AUTOSAR XML (schema 00046)
package /VehicleProject
  system System
package /Diagnostics
  diagnostic service table DS_HUT: diagnostic-connections=DC_0xE001_oHUT_oCAN, ecu-instance=HUT
  diagnostic connection DC_0xE001_oHUT_oCAN: functional-request=msg_diag_RequestGlobal_oTN_0x00E0_Tester, physical-request=msg_diag_Request_MyECU_oTN_0x0001_HUT, response=msg_diag_Response_MyECU_oTN_0x0001_HUT
package /NM
  nm config NmConfig: can-nm-cluster-coupling=coupled-cluster=[B30_for_SC_CAN_V3_2_CAN, CAN]
    can nm cluster B30_for_SC_CAN_V3_2_CAN: communication-cluster=B30_for_SC_CAN_V3_2, nm-channel-id=1, nm-msg-cycle-time=0.5, nm-network-timeout=2, nm-repeat-message-time=1.5, nm-user-data-length=6, nm-wait-bus-sleep-time=5
      7 x can nm node, all with nm-node-id=0, nm-range-config={lower-can-id=1280, upper-can-id=1379}:
        CEM: nm-if-ecu=CEM_CAN, rx-nm-pdu=[DVR_NM_oB30_for_SC_CAN_V3_2, HUT_NM_oB30_for_SC_CAN_V3_2, T_Box_NM_oB30_for_SC_CAN_V3_2, XBOX_D_NM_oB30_for_SC_CAN_V3_2], tx-nm-pdu=CEM_NM_oB30_for_SC_CAN_V3_2
        DVR: nm-if-ecu=DVR_CAN, rx-nm-pdu=[CEM_NM_oB30_for_SC_CAN_V3_2, HUT_NM_oB30_for_SC_CAN_V3_2, T_Box_NM_oB30_for_SC_CAN_V3_2, XBOX_D_NM_oB30_for_SC_CAN_V3_2], tx-nm-pdu=DVR_NM_oB30_for_SC_CAN_V3_2
        GW: nm-if-ecu=GW_CAN, nm-passive-mode-enabled=true
        HUT: controller=CT_B30_for_SC_CAN_V3_2, nm-if-ecu=HUT_CAN, rx-nm-pdu=[CEM_NM_oB30_for_SC_CAN_V3_2, DVR_NM_oB30_for_SC_CAN_V3_2, T_Box_NM_oB30_for_SC_CAN_V3_2, XBOX_D_NM_oB30_for_SC_CAN_V3_2], tx-nm-pdu=HUT_NM_oB30_for_SC_CAN_V3_2
        T_BOX: nm-if-ecu=T_BOX_CAN, rx-nm-pdu=[CEM_NM_oB30_for_SC_CAN_V3_2, DVR_NM_oB30_for_SC_CAN_V3_2, HUT_NM_oB30_for_SC_CAN_V3_2, XBOX_D_NM_oB30_for_SC_CAN_V3_2], tx-nm-pdu=T_Box_NM_oB30_for_SC_CAN_V3_2
        Tester: nm-if-ecu=Tester_CAN, nm-passive-mode-enabled=true
        XBOX_D: nm-if-ecu=XBOX_D_CAN, rx-nm-pdu=[CEM_NM_oB30_for_SC_CAN_V3_2, DVR_NM_oB30_for_SC_CAN_V3_2, HUT_NM_oB30_for_SC_CAN_V3_2, T_Box_NM_oB30_for_SC_CAN_V3_2], tx-nm-pdu=XBOX_D_NM_oB30_for_SC_CAN_V3_2
    can nm cluster CAN: communication-cluster=CAN, nm-channel-id=0, nm-cbv-position=0, nm-msg-cycle-time=0.1, nm-network-timeout=1, nm-nid-position=1, nm-repeat-message-time=0.4, nm-user-data-length=6, nm-wait-bus-sleep-time=0.75
      can nm node HUT: controller=CT_CAN, nm-if-ecu=HUT_CAN, nm-node-id=0, rx-nm-pdu=[msg_nm_OtherECU_oCAN, msg_nm_RearECU_oCAN], tx-nm-pdu=msg_nm_MyECU_oCAN, nm-msg-cycle-offset=0, nm-msg-reduced-time=0.05, nm-range-config={lower-can-id=1024, upper-can-id=1087}
      can nm node OtherECU: nm-if-ecu=OtherECU_CAN, nm-node-id=0, rx-nm-pdu=[msg_nm_MyECU_oCAN, msg_nm_RearECU_oCAN], tx-nm-pdu=msg_nm_OtherECU_oCAN, nm-msg-cycle-offset=0, nm-msg-reduced-time=0.05, nm-range-config={lower-can-id=1024, upper-can-id=1087}
      can nm node RearECU: nm-if-ecu=RearECU_CAN, nm-node-id=1, rx-nm-pdu=[msg_nm_MyECU_oCAN, msg_nm_OtherECU_oCAN], tx-nm-pdu=msg_nm_RearECU_oCAN, nm-msg-cycle-offset=0, nm-msg-reduced-time=0.05, nm-range-config={lower-can-id=1024, upper-can-id=1087}
    nm-if-ecus:
      9 x nm ecu, all with nm-node-id-enabled=true, nm-user-data-enabled=true:
        CEM_CAN
        DVR_CAN
        GW_CAN: nm-passive-mode-enabled=true
        HUT_CAN: ecu-instance=HUT
        OtherECU_CAN
        RearECU_CAN
        T_BOX_CAN
        Tester_CAN: nm-passive-mode-enabled=true
        XBOX_D_CAN
package /TP
  can tp config B30_for_SC_CAN_V3_2_CAN: communication-cluster=B30_for_SC_CAN_V3_2, can-tp-ecu{cycle-time-main-function=0.005, ecu-instance=HUT}
    can tp channel TPCH: channel-id=1, channel-mode=FULL-DUPLEX-MODE
    can-tp-connection addressing-format=STANDARD, can-tp-channel=B30_for_SC_CAN_V3_2_CAN/TPCH, data-pdu=DiagFuncReq_Tp_oB30_for_SC_CAN_V3_2, receiver=TN_HUT_FD, ta-type=FUNCTIONAL-CAN-FD, tp-sdu=DiagFuncReq_oB30_for_SC_CAN_V3_2, transmitter=TN_Tester_FD:
      ident DiagFuncReq_FD_oTN_Tester_FD
    can-tp-connection addressing-format=STANDARD, can-tp-channel=B30_for_SC_CAN_V3_2_CAN/TPCH, data-pdu=DiagFuncReq_Tp_oB30_for_SC_CAN_V3_2_20, receiver=B30_for_SC_CAN_V3_2_CAN/TN_HUT, ta-type=FUNCTIONAL, tp-sdu=DiagFuncReq_oB30_for_SC_CAN_V3_2_20, transmitter=TN_Tester:
      ident DiagFuncReq_oTN_Tester
    can-tp-connection addressing-format=STANDARD, can-tp-channel=B30_for_SC_CAN_V3_2_CAN/TPCH, data-pdu=HUT_Phy_Req_Tp_oB30_for_SC_CAN_V3_2_20, flow-control-pdu=HUT_Phy_Resp_Tp_oB30_for_SC_CAN_V3_2_20, receiver=B30_for_SC_CAN_V3_2_CAN/TN_HUT, ta-type=PHYSICAL, tp-sdu=HUT_Phy_Req_oB30_for_SC_CAN_V3_2_20, transmitter=TN_Tester:
      ident HUT_Phy_Req_oTN_HUT
    can-tp-connection addressing-format=STANDARD, can-tp-channel=B30_for_SC_CAN_V3_2_CAN/TPCH, data-pdu=HUT_Phy_Req_Tp_oB30_for_SC_CAN_V3_2, flow-control-pdu=HUT_Phy_Resp_Tp_oB30_for_SC_CAN_V3_2, receiver=TN_HUT_FD, ta-type=PHYSICAL-CAN-FD, tp-sdu=HUT_Phy_Req_oB30_for_SC_CAN_V3_2, transmitter=TN_Tester_FD:
      ident HUT_Phy_Req_oTN_HUT_FD
    can-tp-connection addressing-format=STANDARD, can-tp-channel=B30_for_SC_CAN_V3_2_CAN/TPCH, data-pdu=HUT_Phy_Resp_Tp_oB30_for_SC_CAN_V3_2_20, flow-control-pdu=HUT_Phy_Req_Tp_oB30_for_SC_CAN_V3_2_20, receiver=TN_Tester, ta-type=PHYSICAL, tp-sdu=HUT_Phy_Resp_oB30_for_SC_CAN_V3_2_20, transmitter=B30_for_SC_CAN_V3_2_CAN/TN_HUT:
      ident HUT_Phy_Resp_oTN_HUT
    can-tp-connection addressing-format=STANDARD, can-tp-channel=B30_for_SC_CAN_V3_2_CAN/TPCH, data-pdu=HUT_Phy_Resp_Tp_oB30_for_SC_CAN_V3_2, flow-control-pdu=HUT_Phy_Req_Tp_oB30_for_SC_CAN_V3_2, receiver=TN_Tester_FD, ta-type=PHYSICAL-CAN-FD, tp-sdu=HUT_Phy_Resp_oB30_for_SC_CAN_V3_2, transmitter=TN_HUT_FD:
      ident HUT_Phy_Resp_oTN_HUT_FD
    4 x can tp node:
      TN_HUT: connector=CN_B30_for_SC_CAN_V3_2
      TN_HUT_FD: connector=CN_B30_for_SC_CAN_V3_2
      TN_Tester
      TN_Tester_FD
  can tp config CAN: communication-cluster=CAN, can-tp-ecu{cycle-time-main-function=0.005, ecu-instance=HUT}
    can tp address TA_0x0000: tp-address=0
    can tp address TA_0x0001: tp-address=1
    can tp address TA_0x00E0: tp-address=224
    can tp channel TPCH: channel-id=0, channel-mode=FULL-DUPLEX-MODE
    can-tp-connection addressing-format=STANDARD, can-tp-channel=CAN/TPCH, data-pdu=msg_diag_RequestGlobal_Tp_oCAN, multicast=TA_0x0000, receiver=CAN/TN_HUT, ta-type=FUNCTIONAL, tp-sdu=msg_diag_RequestGlobal_oCAN, transmitter=TN_0x00E0_Tester:
      ident msg_diag_RequestGlobal_oTN_0x00E0_Tester
    can-tp-connection addressing-format=STANDARD, can-tp-channel=CAN/TPCH, data-pdu=msg_diag_Request_MyECU_Tp_oCAN, flow-control-pdu=msg_diag_Response_MyECU_Tp_oCAN, receiver=TN_0x0001_HUT, ta-type=PHYSICAL, tp-sdu=msg_diag_Request_MyECU_oCAN, transmitter=TN_0x00E0_Tester:
      ident msg_diag_Request_MyECU_oTN_0x0001_HUT
    can-tp-connection addressing-format=STANDARD, can-tp-channel=CAN/TPCH, data-pdu=msg_diag_Response_MyECU_Tp_oCAN, flow-control-pdu=msg_diag_Request_MyECU_Tp_oCAN, receiver=TN_0x00E0_Tester, ta-type=PHYSICAL, tp-sdu=msg_diag_Response_MyECU_oCAN, transmitter=TN_0x0001_HUT:
      ident msg_diag_Response_MyECU_oTN_0x0001_HUT
    can tp node TN_0x0001_HUT: connector=CN_CAN, tp-address=TA_0x0001
    can tp node TN_0x00E0_Tester: tp-address=TA_0x00E0
    can tp node TN_HUT: connector=CN_CAN
  lin tp config LIN00: communication-cluster=LIN00
    tp address TA_0x0001: tp-address=1
    tp address TA_0x0003: tp-address=3
    tp address TA_0x007E: tp-address=126
    tp-connections:
      data-pdu=MasterReq_Tp_oLIN00, lin-tp-n-sdu=MasterReq_oLIN00, multicast=TA_0x007E, receiver=[TN_0x0001_RearECU, TN_0x0003_Slave3], transmitter=TN_Master
      data-pdu=SlaveResp_Tp_oLIN00, flow-control=MasterReq_Tp_oLIN00, lin-tp-n-sdu=SlaveResp_RearECU_oLIN00, receiver=TN_Master, transmitter=TN_0x0001_RearECU
      data-pdu=SlaveResp_Tp_oLIN00, flow-control=MasterReq_Tp_oLIN00, lin-tp-n-sdu=SlaveResp_Slave3_oLIN00, receiver=TN_Master, transmitter=TN_0x0003_Slave3
      data-pdu=MasterReq_Tp_oLIN00, flow-control=SlaveResp_Tp_oLIN00, lin-tp-n-sdu=MasterReq_RearECU_oLIN00, receiver=TN_0x0001_RearECU, transmitter=TN_Master
      data-pdu=MasterReq_Tp_oLIN00, flow-control=SlaveResp_Tp_oLIN00, lin-tp-n-sdu=MasterReq_Slave3_oLIN00, receiver=TN_0x0003_Slave3, transmitter=TN_Master
    lin tp node TN_0x0001_RearECU: tp-address=TA_0x0001
    lin tp node TN_0x0003_Slave3: tp-address=TA_0x0003
    lin tp node TN_Master: connector=CN_LIN00
package /Cluster
  can cluster B30_for_SC_CAN_V3_2: protocol-name=CAN  # P02-001-020MM01 C_Matrix for SC_CANFD_V3.0_Merge_OnlyBigSignal_20220329
    can physical channel CHNL: comm-connectors=CN_B30_for_SC_CAN_V3_2
      frame ABM1_oB30_for_SC_CAN_V3_2: id 0x351, to HUT, frame-length=16, can-addressing-mode=STANDARD, can-frame-rx-behavior=ANY, can-frame-tx-behavior=CAN-FD
        secured i pdu ABM1_Sc_oB30_for_SC_CAN_V3_2: length=16, authentication-props=AuthABM1_Sc_oB30_for_SC_CAN_V3_2, freshness-props=FreshnessABM1_Sc_oB30_for_SC_CAN_V3_2, payload=PT_ABM1, secure-communication-props={auth-info-tx-length=48, data-id=849, freshness-value-length=64, freshness-value-tx-length=16}
      frame ABM2_oB30_for_SC_CAN_V3_2: id 0x245, to HUT, frame-length=8, can-addressing-mode=STANDARD, can-frame-rx-behavior=ANY, can-frame-tx-behavior=CAN-FD
        pdu ABM2_oB30_for_SC_CAN_V3_2: length=8, minimum-delay=0, transmission-mode-false-timing=cyclic-timing=time-period=0.02, transmission-mode-true-timing=cyclic-timing=time-period=0.02, unused-bit-pattern=0
          signal ABM2_0x245_oABM2_oB30_for_SC_CAN_V3_2: start 0, 64 bit, opaque, i-signal-type=ARRAY, init-value=8 x 0, base-type=uint8_8_none, compu-method=CM_ABM2_0x245, data-constr=DC_ABM2_0x245, transfer-property=PENDING, to HUT
      frame ABS1_oB30_for_SC_CAN_V3_2: id 0x231, to HUT, frame-length=8, can-addressing-mode=STANDARD, can-frame-rx-behavior=ANY, can-frame-tx-behavior=CAN-FD
        pdu ABS1_oB30_for_SC_CAN_V3_2: length=8, minimum-delay=0, transmission-mode-false-timing=cyclic-timing=time-period=0.02, transmission-mode-true-timing=cyclic-timing=time-period=0.02, unused-bit-pattern=0
          signal ABS1_0x231_oABS1_oB30_for_SC_CAN_V3_2: start 0, 64 bit, opaque, i-signal-type=ARRAY, init-value=8 x 0, base-type=uint8_8_none, compu-method=CM_ABS1_0x231, data-constr=DC_ABS1_0x231, transfer-property=PENDING, to HUT
      frame ABS2_oB30_for_SC_CAN_V3_2: id 0x246, to HUT, frame-length=8, can-addressing-mode=STANDARD, can-frame-rx-behavior=ANY, can-frame-tx-behavior=CAN-FD
        pdu ABS2_oB30_for_SC_CAN_V3_2: length=8, minimum-delay=0, transmission-mode-false-timing=cyclic-timing=time-period=0.02, transmission-mode-true-timing=cyclic-timing=time-period=0.02, unused-bit-pattern=0
          signal ABS2_0x246_oABS2_oB30_for_SC_CAN_V3_2: start 0, 64 bit, opaque, i-signal-type=ARRAY, init-value=8 x 0, base-type=uint8_8_none, compu-method=CM_ABS2_0x246, data-constr=DC_ABS2_0x246, transfer-property=PENDING, to HUT
      frame AC1_oB30_for_SC_CAN_V3_2: id 0x29D, to HUT, frame-length=8, can-addressing-mode=STANDARD, can-frame-rx-behavior=ANY, can-frame-tx-behavior=CAN-FD
        pdu AC1_oB30_for_SC_CAN_V3_2: length=8, minimum-delay=0, transmission-mode-false-timing=cyclic-timing=time-period=0.1, transmission-mode-true-timing=cyclic-timing=time-period=0.1, unused-bit-pattern=0
          signal AC1_0x29D_oAC1_oB30_for_SC_CAN_V3_2: start 0, 64 bit, opaque, i-signal-type=ARRAY, init-value=8 x 0, base-type=uint8_8_none, compu-method=CM_AC1_0x29D, data-constr=DC_AC1_0x29D, transfer-property=PENDING, to HUT
      frame AC14_oB30_for_SC_CAN_V3_2: id 0x299, to HUT, frame-length=8, can-addressing-mode=STANDARD, can-frame-rx-behavior=ANY, can-frame-tx-behavior=CAN-FD
        pdu AC14_oB30_for_SC_CAN_V3_2: length=8, minimum-delay=0, transmission-mode-false-timing=cyclic-timing=time-period=0.1, transmission-mode-true-timing=cyclic-timing=time-period=0.1, unused-bit-pattern=0
          signal AC14_0x299_oAC14_oB30_for_SC_CAN_V3_2: start 0, 64 bit, opaque, i-signal-type=ARRAY, init-value=8 x 0, base-type=uint8_8_none, compu-method=CM_AC14_0x299, data-constr=DC_AC14_0x299, transfer-property=PENDING, to HUT
      frame AC2_oB30_for_SC_CAN_V3_2: id 0x385, to HUT, frame-length=8, can-addressing-mode=STANDARD, can-frame-rx-behavior=ANY, can-frame-tx-behavior=CAN-FD
        pdu AC2_oB30_for_SC_CAN_V3_2: length=8, minimum-delay=0, transmission-mode-false-timing=cyclic-timing=time-period=0.1, transmission-mode-true-timing=cyclic-timing=time-period=0.1, unused-bit-pattern=0
          signal AC2_0x385_oAC2_oB30_for_SC_CAN_V3_2: start 0, 64 bit, opaque, i-signal-type=ARRAY, init-value=8 x 0, base-type=uint8_8_none, compu-method=CM_AC2_0x385, data-constr=DC_AC2_0x385, transfer-property=PENDING, to HUT
      frame AC3_oB30_for_SC_CAN_V3_2: id 0x2FD, to HUT, frame-length=8, can-addressing-mode=STANDARD, can-frame-rx-behavior=ANY, can-frame-tx-behavior=CAN-FD
        pdu AC3_oB30_for_SC_CAN_V3_2: length=8, minimum-delay=0, transmission-mode-false-timing=cyclic-timing=time-period=0.1, transmission-mode-true-timing=cyclic-timing=time-period=0.1, unused-bit-pattern=0
          signal AC3_0x2FD_oAC3_oB30_for_SC_CAN_V3_2: start 0, 64 bit, opaque, i-signal-type=ARRAY, init-value=8 x 0, base-type=uint8_8_none, compu-method=CM_AC3_0x2FD, data-constr=DC_AC3_0x2FD, transfer-property=PENDING, to HUT
      frame AC4_oB30_for_SC_CAN_V3_2: id 0x2CC, to HUT, frame-length=8, can-addressing-mode=STANDARD, can-frame-rx-behavior=ANY, can-frame-tx-behavior=CAN-FD
        pdu AC4_oB30_for_SC_CAN_V3_2: length=8, minimum-delay=0, transmission-mode-false-timing=cyclic-timing=time-period=0.1, transmission-mode-true-timing=cyclic-timing=time-period=0.1, unused-bit-pattern=0
          signal AC4_0x2CC_oAC4_oB30_for_SC_CAN_V3_2: start 0, 64 bit, opaque, i-signal-type=ARRAY, init-value=8 x 0, base-type=uint8_8_none, compu-method=CM_AC4_0x2CC, data-constr=DC_AC4_0x2CC, transfer-property=PENDING, to HUT
      frame AC6_oB30_for_SC_CAN_V3_2: id 0x2F8, to HUT, frame-length=8, can-addressing-mode=STANDARD, can-frame-rx-behavior=ANY, can-frame-tx-behavior=CAN-FD
        pdu AC6_oB30_for_SC_CAN_V3_2: length=8, minimum-delay=0, transmission-mode-false-timing=cyclic-timing=time-period=0.1, transmission-mode-true-timing=cyclic-timing=time-period=0.1, unused-bit-pattern=0
          signal AC6_0x2F8_oAC6_oB30_for_SC_CAN_V3_2: start 0, 64 bit, opaque, i-signal-type=ARRAY, init-value=8 x 0, base-type=uint8_8_none, compu-method=CM_AC6_0x2F8, data-constr=DC_AC6_0x2F8, transfer-property=PENDING, to HUT
      frame AC7_oB30_for_SC_CAN_V3_2: id 0x2D0, to HUT, frame-length=8, can-addressing-mode=STANDARD, can-frame-rx-behavior=ANY, can-frame-tx-behavior=CAN-FD
        pdu AC7_oB30_for_SC_CAN_V3_2: length=8, minimum-delay=0, transmission-mode-false-timing=cyclic-timing=time-period=0.1, transmission-mode-true-timing=cyclic-timing=time-period=0.1, unused-bit-pattern=0
          signal AC7_0x2D0_oAC7_oB30_for_SC_CAN_V3_2: start 0, 64 bit, opaque, i-signal-type=ARRAY, init-value=8 x 0, base-type=uint8_8_none, compu-method=CM_AC7_0x2D0, data-constr=DC_AC7_0x2D0, transfer-property=PENDING, to HUT
      frame AC8_oB30_for_SC_CAN_V3_2: id 0x27C, to HUT, frame-length=8, can-addressing-mode=STANDARD, can-frame-rx-behavior=ANY, can-frame-tx-behavior=CAN-FD
        pdu AC8_oB30_for_SC_CAN_V3_2: length=8, minimum-delay=0, transmission-mode-false-timing=cyclic-timing=time-period=0.05, transmission-mode-true-timing=cyclic-timing=time-period=0.05, unused-bit-pattern=0
          signal AC8_0x27C_oAC8_oB30_for_SC_CAN_V3_2: start 0, 64 bit, opaque, i-signal-type=ARRAY, init-value=8 x 0, base-type=uint8_8_none, compu-method=CM_AC8_0x27C, data-constr=DC_AC8_0x27C, transfer-property=PENDING, to HUT
      frame ACC_FD2_oB30_for_SC_CAN_V3_2: id 0x2AB, to HUT, frame-length=64, can-addressing-mode=STANDARD, can-frame-rx-behavior=ANY, can-frame-tx-behavior=CAN-FD
        secured i pdu ACC_FD2_Sc_oB30_for_SC_CAN_V3_2: length=64, authentication-props=AuthACC_FD2_Sc_oB30_for_SC_CAN_V3_2, freshness-props=FreshnessACC_FD2_Sc_oB30_for_SC_CAN_V3_2, payload=PT_ACC_FD2, secure-communication-props={auth-info-tx-length=48, data-id=683, freshness-value-length=64, freshness-value-tx-length=16}
      frame ACC_FD3_oB30_for_SC_CAN_V3_2: id 0x2B4, to HUT, frame-length=64, can-addressing-mode=STANDARD, can-frame-rx-behavior=ANY, can-frame-tx-behavior=CAN-FD
        pdu ACC_FD3_oB30_for_SC_CAN_V3_2: length=64, minimum-delay=0, transmission-mode-false-timing=cyclic-timing=time-period=0.1, transmission-mode-true-timing=cyclic-timing=time-period=0.1, unused-bit-pattern=0
          signal ACC_FD3_0x2B4_oACC_FD3_oB30_for_SC_CAN_V3_2: start 0, 512 bit, opaque, i-signal-type=ARRAY, init-value=64 x 0, base-type=uint8_64_none, compu-method=CM_ACC_FD3_0x2B4, data-constr=DC_ACC_FD3_0x2B4, transfer-property=PENDING, to HUT
      frame ACC_FD4_oB30_for_SC_CAN_V3_2: id 0x2B8, to HUT, frame-length=64, can-addressing-mode=STANDARD, can-frame-rx-behavior=ANY, can-frame-tx-behavior=CAN-FD
        pdu ACC_FD4_oB30_for_SC_CAN_V3_2: length=64, minimum-delay=0, transmission-mode-false-timing=cyclic-timing=time-period=0.1, transmission-mode-true-timing=cyclic-timing=time-period=0.1, unused-bit-pattern=0
          signal ACC_FD4_0x2B8_oACC_FD4_oB30_for_SC_CAN_V3_2: start 0, 512 bit, opaque, i-signal-type=ARRAY, init-value=64 x 0, base-type=uint8_64_none, compu-method=CM_ACC_FD4_0x2B8, data-constr=DC_ACC_FD4_0x2B8, transfer-property=PENDING, to HUT
      frame AEB_FD1_oB30_for_SC_CAN_V3_2: id 0x18B, to HUT, frame-length=64, can-addressing-mode=STANDARD, can-frame-rx-behavior=ANY, can-frame-tx-behavior=CAN-FD
        pdu AEB_FD1_oB30_for_SC_CAN_V3_2: length=64, minimum-delay=0, transmission-mode-false-timing=cyclic-timing=time-period=0.02, transmission-mode-true-timing=cyclic-timing=time-period=0.02, unused-bit-pattern=0
          signal AEB_FD1_0x18B_oAEB_FD1_oB30_for_SC_CAN_V3_2: start 0, 512 bit, opaque, i-signal-type=ARRAY, init-value=64 x 0, base-type=uint8_64_none, compu-method=CM_AEB_FD1_0x18B, data-constr=DC_AEB_FD1_0x18B, transfer-property=PENDING, to HUT
      frame AEB_FD2_oB30_for_SC_CAN_V3_2: id 0x227, to HUT, frame-length=64, can-addressing-mode=STANDARD, can-frame-rx-behavior=ANY, can-frame-tx-behavior=CAN-FD
        secured i pdu AEB_FD2_Sc_oB30_for_SC_CAN_V3_2: length=64, authentication-props=AuthAEB_FD2_Sc_oB30_for_SC_CAN_V3_2, freshness-props=FreshnessAEB_FD2_Sc_oB30_for_SC_CAN_V3_2, payload=PT_AEB_FD2, secure-communication-props={auth-info-tx-length=48, data-id=551, freshness-value-length=64, freshness-value-tx-length=16}
      frame ALS1_oB30_for_SC_CAN_V3_2: id 0x287, to HUT, frame-length=16, can-addressing-mode=STANDARD, can-frame-rx-behavior=ANY, can-frame-tx-behavior=CAN-FD
        pdu ALS1_oB30_for_SC_CAN_V3_2: length=16, minimum-delay=0, transmission-mode-false-timing=cyclic-timing=time-period=0.1, transmission-mode-true-timing=cyclic-timing=time-period=0.1, unused-bit-pattern=0
          signal ALS1_0x287_oALS1_oB30_for_SC_CAN_V3_2: start 0, 128 bit, opaque, i-signal-type=ARRAY, init-value=16 x 0, base-type=uint8_16_none, compu-method=CM_ALS1_0x287, data-constr=DC_ALS1_0x287, transfer-property=PENDING, to HUT
      frame AMP1_oB30_for_SC_CAN_V3_2: id 0x3E1, to HUT, frame-length=8, can-addressing-mode=STANDARD, can-frame-rx-behavior=ANY, can-frame-tx-behavior=CAN-FD
        pdu AMP1_oB30_for_SC_CAN_V3_2: length=8, minimum-delay=0, transmission-mode-false-timing=event-controlled-timing={number-of-repetitions=5, repetition-period=0.02}, transmission-mode-true-timing=event-controlled-timing={number-of-repetitions=5, repetition-period=0.02}, unused-bit-pattern=0
          signal AMP1_0x3E1_oAMP1_oB30_for_SC_CAN_V3_2: start 0, 64 bit, opaque, i-signal-type=ARRAY, init-value=8 x 0, base-type=uint8_8_none, compu-method=CM_AMP1_0x3E1, data-constr=DC_AMP1_0x3E1, transfer-property=TRIGGERED, to HUT
      frame AMP2_oB30_for_SC_CAN_V3_2: id 0x3E3, to HUT, frame-length=16, can-addressing-mode=STANDARD, can-frame-rx-behavior=ANY, can-frame-tx-behavior=CAN-FD
        secured i pdu AMP2_Sc_oB30_for_SC_CAN_V3_2: length=16, authentication-props=AuthAMP2_Sc_oB30_for_SC_CAN_V3_2, freshness-props=FreshnessAMP2_Sc_oB30_for_SC_CAN_V3_2, payload=PT_AMP2, secure-communication-props={auth-info-tx-length=48, data-id=995, freshness-value-length=64, freshness-value-tx-length=16}
      frame AMP3_oB30_for_SC_CAN_V3_2: id 0x3E5, to HUT, frame-length=8, can-addressing-mode=STANDARD, can-frame-rx-behavior=ANY, can-frame-tx-behavior=CAN-FD
        pdu AMP3_oB30_for_SC_CAN_V3_2: length=8, minimum-delay=0, transmission-mode-false-timing=event-controlled-timing={number-of-repetitions=5, repetition-period=0.02}, transmission-mode-true-timing=event-controlled-timing={number-of-repetitions=5, repetition-period=0.02}, unused-bit-pattern=0
          signal AMP3_0x3E5_oAMP3_oB30_for_SC_CAN_V3_2: start 0, 64 bit, opaque, i-signal-type=ARRAY, init-value=8 x 0, base-type=uint8_8_none, compu-method=CM_AMP3_0x3E5, data-constr=DC_AMP3_0x3E5, transfer-property=TRIGGERED, to HUT
      frame AMP4_ANC1_oB30_for_SC_CAN_V3_2: id 0x2D2, to HUT, frame-length=8, can-addressing-mode=STANDARD, can-frame-rx-behavior=ANY, can-frame-tx-behavior=CAN-FD
        pdu AMP4_ANC1_oB30_for_SC_CAN_V3_2: length=8, minimum-delay=0, transmission-mode-false-timing=event-controlled-timing={number-of-repetitions=5, repetition-period=0.02}, transmission-mode-true-timing=event-controlled-timing={number-of-repetitions=5, repetition-period=0.02}, unused-bit-pattern=0
          signal AMP4_ANC1_0x2D2_oAMP4_ANC1_oB30_for_SC_CAN_V3_2: start 0, 64 bit, opaque, i-signal-type=ARRAY, init-value=8 x 0, base-type=uint8_8_none, compu-method=CM_AMP4_ANC1_0x2D2, data-constr=DC_AMP4_ANC1_0x2D2, transfer-property=TRIGGERED, to HUT
      frame BCM1_oB30_for_SC_CAN_V3_2: id 0x319, to HUT, frame-length=16, can-addressing-mode=STANDARD, can-frame-rx-behavior=ANY, can-frame-tx-behavior=CAN-FD
        secured i pdu BCM1_Sc_oB30_for_SC_CAN_V3_2: length=16, authentication-props=AuthBCM1_Sc_oB30_for_SC_CAN_V3_2, freshness-props=FreshnessBCM1_Sc_oB30_for_SC_CAN_V3_2, payload=PT_BCM1, secure-communication-props={auth-info-tx-length=48, data-id=793, freshness-value-length=64, freshness-value-tx-length=16}
      frame BCM11_oB30_for_SC_CAN_V3_2: id 0x305, to HUT, frame-length=8, can-addressing-mode=STANDARD, can-frame-rx-behavior=ANY, can-frame-tx-behavior=CAN-FD
        pdu BCM11_oB30_for_SC_CAN_V3_2: length=8, minimum-delay=0, transmission-mode-false-timing=cyclic-timing=time-period=0.1, transmission-mode-true-timing=cyclic-timing=time-period=0.1, unused-bit-pattern=0
          signal BCM11_0x305_oBCM11_oB30_for_SC_CAN_V3_2: start 0, 64 bit, opaque, i-signal-type=ARRAY, init-value=8 x 0, base-type=uint8_8_none, compu-method=CM_BCM11_0x305, data-constr=DC_BCM11_0x305, transfer-property=PENDING, to HUT
      frame BCM12_oB30_for_SC_CAN_V3_2: id 0x238, to HUT, frame-length=8, can-addressing-mode=STANDARD, can-frame-rx-behavior=ANY, can-frame-tx-behavior=CAN-FD
        pdu BCM12_oB30_for_SC_CAN_V3_2: length=8, minimum-delay=0, transmission-mode-false-timing=cyclic-timing=time-period=0.05, transmission-mode-true-timing=cyclic-timing=time-period=0.05, unused-bit-pattern=0
          signal BCM12_0x238_oBCM12_oB30_for_SC_CAN_V3_2: start 0, 64 bit, opaque, i-signal-type=ARRAY, init-value=8 x 0, base-type=uint8_8_none, compu-method=CM_BCM12_0x238, data-constr=DC_BCM12_0x238, transfer-property=PENDING, to HUT
      frame BCM14_oB30_for_SC_CAN_V3_2: id 0x2A3, to HUT, frame-length=8, can-addressing-mode=STANDARD, can-frame-rx-behavior=ANY, can-frame-tx-behavior=CAN-FD
        pdu BCM14_oB30_for_SC_CAN_V3_2: length=8, minimum-delay=0, transmission-mode-false-timing=cyclic-timing=time-period=0.1, transmission-mode-true-timing=cyclic-timing=time-period=0.1, unused-bit-pattern=0
          signal BCM14_0x2A3_oBCM14_oB30_for_SC_CAN_V3_2: start 0, 64 bit, opaque, i-signal-type=ARRAY, init-value=8 x 0, base-type=uint8_8_none, compu-method=CM_BCM14_0x2A3, data-constr=DC_BCM14_0x2A3, transfer-property=PENDING, to HUT
      frame BCM18_oB30_for_SC_CAN_V3_2: id 0x34D, to HUT, frame-length=8, can-addressing-mode=STANDARD, can-frame-rx-behavior=ANY, can-frame-tx-behavior=CAN-FD
        pdu BCM18_oB30_for_SC_CAN_V3_2: length=8, minimum-delay=0, transmission-mode-false-timing=cyclic-timing=time-period=0.5, transmission-mode-true-timing=cyclic-timing=time-period=0.5, unused-bit-pattern=0
          signal BCM18_0x34D_oBCM18_oB30_for_SC_CAN_V3_2: start 0, 64 bit, opaque, i-signal-type=ARRAY, init-value=8 x 0, base-type=uint8_8_none, compu-method=CM_BCM18_0x34D, data-constr=DC_BCM18_0x34D, transfer-property=PENDING, to HUT
      frame BCM19_oB30_for_SC_CAN_V3_2: id 0x30F, to HUT, frame-length=8, can-addressing-mode=STANDARD, can-frame-rx-behavior=ANY, can-frame-tx-behavior=CAN-FD
        pdu BCM19_oB30_for_SC_CAN_V3_2: length=8, minimum-delay=0, transmission-mode-false-timing=cyclic-timing=time-period=0.1, transmission-mode-true-timing=cyclic-timing=time-period=0.1, unused-bit-pattern=0
          signal BCM19_0x30F_oBCM19_oB30_for_SC_CAN_V3_2: start 0, 64 bit, opaque, i-signal-type=ARRAY, init-value=8 x 0, base-type=uint8_8_none, compu-method=CM_BCM19_0x30F, data-constr=DC_BCM19_0x30F, transfer-property=PENDING, to HUT
      frame BCM3_oB30_for_SC_CAN_V3_2: id 0x345, to HUT, frame-length=16, can-addressing-mode=STANDARD, can-frame-rx-behavior=ANY, can-frame-tx-behavior=CAN-FD
        secured i pdu BCM3_Sc_oB30_for_SC_CAN_V3_2: length=16, authentication-props=AuthBCM3_Sc_oB30_for_SC_CAN_V3_2, freshness-props=FreshnessBCM3_Sc_oB30_for_SC_CAN_V3_2, payload=PT_BCM3, secure-communication-props={auth-info-tx-length=48, data-id=837, freshness-value-length=64, freshness-value-tx-length=16}
      frame BCM7_oB30_for_SC_CAN_V3_2: id 0x28D, to HUT, frame-length=8, can-addressing-mode=STANDARD, can-frame-rx-behavior=ANY, can-frame-tx-behavior=CAN-FD
        pdu BCM7_oB30_for_SC_CAN_V3_2: length=8, minimum-delay=0, transmission-mode-false-timing=cyclic-timing=time-period=0.1, transmission-mode-true-timing=cyclic-timing=time-period=0.1, unused-bit-pattern=0
          signal BCM7_0x28D_oBCM7_oB30_for_SC_CAN_V3_2: start 0, 64 bit, opaque, i-signal-type=ARRAY, init-value=8 x 0, base-type=uint8_8_none, compu-method=CM_BCM7_0x28D, data-constr=DC_BCM7_0x28D, transfer-property=PENDING, to HUT
      frame BCM8_oB30_for_SC_CAN_V3_2: id 0x29F, to HUT, frame-length=8, can-addressing-mode=STANDARD, can-frame-rx-behavior=ANY, can-frame-tx-behavior=CAN-FD
        pdu BCM8_oB30_for_SC_CAN_V3_2: length=8, minimum-delay=0, transmission-mode-false-timing=cyclic-timing=time-period=0.1, transmission-mode-true-timing=cyclic-timing=time-period=0.1, unused-bit-pattern=0
          signal BCM8_0x29F_oBCM8_oB30_for_SC_CAN_V3_2: start 0, 64 bit, opaque, i-signal-type=ARRAY, init-value=8 x 0, base-type=uint8_8_none, compu-method=CM_BCM8_0x29F, data-constr=DC_BCM8_0x29F, transfer-property=PENDING, to HUT
      frame BLE1_oB30_for_SC_CAN_V3_2: id 0x25C, to HUT, frame-length=8, can-addressing-mode=STANDARD, can-frame-rx-behavior=ANY, can-frame-tx-behavior=CAN-FD
        pdu BLE1_oB30_for_SC_CAN_V3_2: length=8, minimum-delay=0, transmission-mode-false-timing=cyclic-timing=time-period=0.05, transmission-mode-true-timing=cyclic-timing=time-period=0.05, unused-bit-pattern=0
          signal BLE1_0x25C_oBLE1_oB30_for_SC_CAN_V3_2: start 0, 64 bit, opaque, i-signal-type=ARRAY, init-value=8 x 0, base-type=uint8_8_none, compu-method=CM_BLE1_0x25C, data-constr=DC_BLE1_0x25C, transfer-property=PENDING, to HUT
      frame BLE5_oB30_for_SC_CAN_V3_2: id 0x1FA, to HUT, frame-length=8, can-addressing-mode=STANDARD, can-frame-rx-behavior=ANY, can-frame-tx-behavior=CAN-FD
        pdu BLE5_oB30_for_SC_CAN_V3_2: length=8, minimum-delay=0, transmission-mode-false-timing=event-controlled-timing={number-of-repetitions=5, repetition-period=0.02}, transmission-mode-true-timing=event-controlled-timing={number-of-repetitions=5, repetition-period=0.02}, unused-bit-pattern=0
          signal BLE5_0x1FA_oBLE5_oB30_for_SC_CAN_V3_2: start 0, 64 bit, opaque, i-signal-type=ARRAY, init-value=8 x 0, base-type=uint8_8_none, compu-method=CM_BLE5_0x1FA, data-constr=DC_BLE5_0x1FA, transfer-property=TRIGGERED, to HUT
      frame BMS_FD14_oB30_for_SC_CAN_V3_2: id 0x1E3, to HUT, frame-length=8, can-addressing-mode=STANDARD, can-frame-rx-behavior=ANY, can-frame-tx-behavior=CAN-FD
        pdu BMS_FD14_oB30_for_SC_CAN_V3_2: length=8, minimum-delay=0, transmission-mode-false-timing=event-controlled-timing={number-of-repetitions=5, repetition-period=0.02}, transmission-mode-true-timing=event-controlled-timing={number-of-repetitions=5, repetition-period=0.02}, unused-bit-pattern=0
          signal BMS_FD14_0x1E3_oBMS_FD14_oB30_for_SC_CAN_V3_2: start 0, 64 bit, opaque, i-signal-type=ARRAY, init-value=8 x 0, base-type=uint8_8_none, compu-method=CM_BMS_FD14_0x1E3, data-constr=DC_BMS_FD14_0x1E3, transfer-property=TRIGGERED, to HUT
      frame BMS19_oB30_for_SC_CAN_V3_2: id 0x352, to HUT, frame-length=8, can-addressing-mode=STANDARD, can-frame-rx-behavior=ANY, can-frame-tx-behavior=CAN-FD
        pdu BMS19_oB30_for_SC_CAN_V3_2: length=8, minimum-delay=0, transmission-mode-false-timing=cyclic-timing=time-period=0.5, transmission-mode-true-timing=cyclic-timing=time-period=0.5, unused-bit-pattern=0
          signal BMS19_0x352_oBMS19_oB30_for_SC_CAN_V3_2: start 0, 64 bit, opaque, i-signal-type=ARRAY, init-value=8 x 0, base-type=uint8_8_none, compu-method=CM_BMS19_0x352, data-constr=DC_BMS19_0x352, transfer-property=PENDING, to HUT
      frame BMS22_oB30_for_SC_CAN_V3_2: id 0x3BF, to HUT, frame-length=8, can-addressing-mode=STANDARD, can-frame-rx-behavior=ANY, can-frame-tx-behavior=CAN-FD
        pdu BMS22_oB30_for_SC_CAN_V3_2: length=8, minimum-delay=0, transmission-mode-false-timing=cyclic-timing=time-period=1, transmission-mode-true-timing=cyclic-timing=time-period=1, unused-bit-pattern=0
          signal BMS22_0x3BF_oBMS22_oB30_for_SC_CAN_V3_2: start 0, 64 bit, opaque, i-signal-type=ARRAY, init-value=8 x 0, base-type=uint8_8_none, compu-method=CM_BMS22_0x3BF, data-constr=DC_BMS22_0x3BF, transfer-property=PENDING, to HUT
      frame BMS30_oB30_for_SC_CAN_V3_2: id 0x3F1, to HUT, frame-length=8, can-addressing-mode=STANDARD, can-frame-rx-behavior=ANY, can-frame-tx-behavior=CAN-FD
        pdu BMS30_oB30_for_SC_CAN_V3_2: length=8, minimum-delay=0, transmission-mode-false-timing=cyclic-timing=time-period=1, transmission-mode-true-timing=cyclic-timing=time-period=1, unused-bit-pattern=0
          signal BMS30_0x3F1_oBMS30_oB30_for_SC_CAN_V3_2: start 0, 64 bit, opaque, i-signal-type=ARRAY, init-value=8 x 0, base-type=uint8_8_none, compu-method=CM_BMS30_0x3F1, data-constr=DC_BMS30_0x3F1, transfer-property=PENDING, to HUT
      frame BMS35_oB30_for_SC_CAN_V3_2: id 0x2C4, to HUT, frame-length=8, can-addressing-mode=STANDARD, can-frame-rx-behavior=ANY, can-frame-tx-behavior=CAN-FD
        pdu BMS35_oB30_for_SC_CAN_V3_2: length=8, minimum-delay=0, transmission-mode-false-timing=cyclic-timing=time-period=0.1, transmission-mode-true-timing=cyclic-timing=time-period=0.1, unused-bit-pattern=0
          signal BMS35_0x2C4_oBMS35_oB30_for_SC_CAN_V3_2: start 0, 64 bit, opaque, i-signal-type=ARRAY, init-value=8 x 0, base-type=uint8_8_none, compu-method=CM_BMS35_0x2C4, data-constr=DC_BMS35_0x2C4, transfer-property=PENDING, to HUT
      frame BMS4_oB30_for_SC_CAN_V3_2: id 0xF1, to HUT, frame-length=8, can-addressing-mode=STANDARD, can-frame-rx-behavior=ANY, can-frame-tx-behavior=CAN-FD
        pdu BMS4_oB30_for_SC_CAN_V3_2: length=8, minimum-delay=0, transmission-mode-false-timing=cyclic-timing=time-period=0.01, transmission-mode-true-timing=cyclic-timing=time-period=0.01, unused-bit-pattern=0
          signal BMS4_0xF1_oBMS4_oB30_for_SC_CAN_V3_2: start 0, 64 bit, opaque, i-signal-type=ARRAY, init-value=8 x 0, base-type=uint8_8_none, compu-method=CM_BMS4_0xF1, data-constr=DC_BMS4_0xF1, transfer-property=PENDING, to HUT
      frame BMS65_oB30_for_SC_CAN_V3_2: id 0x14F, to HUT, frame-length=8, can-addressing-mode=STANDARD, can-frame-rx-behavior=ANY, can-frame-tx-behavior=CAN-FD
        pdu BMS65_oB30_for_SC_CAN_V3_2: length=8, minimum-delay=0, transmission-mode-false-timing=cyclic-timing=time-period=0.02, transmission-mode-true-timing=cyclic-timing=time-period=0.02, unused-bit-pattern=0
          signal BMS65_0x14F_oBMS65_oB30_for_SC_CAN_V3_2: start 0, 64 bit, opaque, i-signal-type=ARRAY, init-value=8 x 0, base-type=uint8_8_none, compu-method=CM_BMS65_0x14F, data-constr=DC_BMS65_0x14F, transfer-property=PENDING, to HUT
      frame BMS66_oB30_for_SC_CAN_V3_2: id 0x3AE, to HUT, frame-length=8, can-addressing-mode=STANDARD, can-frame-rx-behavior=ANY, can-frame-tx-behavior=CAN-FD
        pdu BMS66_oB30_for_SC_CAN_V3_2: length=8, minimum-delay=0, transmission-mode-false-timing=cyclic-timing=time-period=1, transmission-mode-true-timing=cyclic-timing=time-period=1, unused-bit-pattern=0
          signal BMS66_0x3AE_oBMS66_oB30_for_SC_CAN_V3_2: start 0, 64 bit, opaque, i-signal-type=ARRAY, init-value=8 x 0, base-type=uint8_8_none, compu-method=CM_BMS66_0x3AE, data-constr=DC_BMS66_0x3AE, transfer-property=PENDING, to HUT
      frame BMS8_oB30_for_SC_CAN_V3_2: id 0x285, to HUT, frame-length=8, can-addressing-mode=STANDARD, can-frame-rx-behavior=ANY, can-frame-tx-behavior=CAN-FD
        pdu BMS8_oB30_for_SC_CAN_V3_2: length=8, minimum-delay=0, transmission-mode-false-timing=cyclic-timing=time-period=0.1, transmission-mode-true-timing=cyclic-timing=time-period=0.1, unused-bit-pattern=0
          signal BMS8_0x285_oBMS8_oB30_for_SC_CAN_V3_2: start 0, 64 bit, opaque, i-signal-type=ARRAY, init-value=8 x 0, base-type=uint8_8_none, compu-method=CM_BMS8_0x285, data-constr=DC_BMS8_0x285, transfer-property=PENDING, to HUT
      frame CEM_NM_oB30_for_SC_CAN_V3_2: id 0x501, to HUT, frame-length=8, can-addressing-mode=STANDARD, can-frame-rx-behavior=ANY, can-frame-tx-behavior=CAN-20
        nm pdu CEM_NM_oB30_for_SC_CAN_V3_2: length=8, unused-bit-pattern=0
      frame CP1_oB30_for_SC_CAN_V3_2: id 0x35E, to HUT, frame-length=8, can-addressing-mode=STANDARD, can-frame-rx-behavior=ANY, can-frame-tx-behavior=CAN-FD
        pdu CP1_oB30_for_SC_CAN_V3_2: length=8, minimum-delay=0, transmission-mode-false-timing=cyclic-timing=time-period=0.5, transmission-mode-true-timing=cyclic-timing=time-period=0.5, unused-bit-pattern=0
          signal CP1_0x35E_oCP1_oB30_for_SC_CAN_V3_2: start 0, 64 bit, opaque, i-signal-type=ARRAY, init-value=8 x 0, base-type=uint8_8_none, compu-method=CM_CP1_0x35E, data-constr=DC_CP1_0x35E, transfer-property=PENDING, to HUT
      frame CR_FD1_oB30_for_SC_CAN_V3_2: id 0x15E, to HUT, frame-length=64, can-addressing-mode=STANDARD, can-frame-rx-behavior=ANY, can-frame-tx-behavior=CAN-FD
        pdu CR_FD1_oB30_for_SC_CAN_V3_2: length=64, minimum-delay=0, transmission-mode-false-timing=cyclic-timing=time-period=0.02, transmission-mode-true-timing=cyclic-timing=time-period=0.02, unused-bit-pattern=0
          signal CR_FD1_0x15E_oCR_FD1_oB30_for_SC_CAN_V3_2: start 0, 512 bit, opaque, i-signal-type=ARRAY, init-value=64 x 0, base-type=uint8_64_none, compu-method=CM_CR_FD1_0x15E, data-constr=DC_CR_FD1_0x15E, transfer-property=PENDING, to HUT
      frame CSA1_oB30_for_SC_CAN_V3_2: id 0x165, to HUT, frame-length=8, can-addressing-mode=STANDARD, can-frame-rx-behavior=ANY, can-frame-tx-behavior=CAN-FD
        pdu CSA1_oB30_for_SC_CAN_V3_2: length=8, minimum-delay=0, transmission-mode-false-timing=cyclic-timing=time-period=0.02, transmission-mode-true-timing=cyclic-timing=time-period=0.02, unused-bit-pattern=0
          signal CSA1_0x165_oCSA1_oB30_for_SC_CAN_V3_2: start 0, 64 bit, opaque, i-signal-type=ARRAY, init-value=8 x 0, base-type=uint8_8_none, compu-method=CM_CSA1_0x165, data-constr=DC_CSA1_0x165, transfer-property=PENDING, to HUT
      frame CSA2_oB30_for_SC_CAN_V3_2: id 0xA1, to HUT, frame-length=8, can-addressing-mode=STANDARD, can-frame-rx-behavior=ANY, can-frame-tx-behavior=CAN-FD
        pdu CSA2_oB30_for_SC_CAN_V3_2: length=8, minimum-delay=0, transmission-mode-false-timing=cyclic-timing=time-period=0.01, transmission-mode-true-timing=cyclic-timing=time-period=0.01, unused-bit-pattern=0
          signal CSA2_0xA1_oCSA2_oB30_for_SC_CAN_V3_2: start 0, 64 bit, opaque, i-signal-type=ARRAY, init-value=8 x 0, base-type=uint8_8_none, compu-method=CM_CSA2_0xA1, data-constr=DC_CSA2_0xA1, transfer-property=PENDING, to HUT
      frame CSA3_oB30_for_SC_CAN_V3_2: id 0x244, to HUT, frame-length=8, can-addressing-mode=STANDARD, can-frame-rx-behavior=ANY, can-frame-tx-behavior=CAN-FD
        pdu CSA3_oB30_for_SC_CAN_V3_2: length=8, minimum-delay=0, transmission-mode-false-timing=cyclic-timing=time-period=0.05, transmission-mode-true-timing=cyclic-timing=time-period=0.05, unused-bit-pattern=0
          signal CSA3_0x244_oCSA3_oB30_for_SC_CAN_V3_2: start 0, 64 bit, opaque, i-signal-type=ARRAY, init-value=8 x 0, base-type=uint8_8_none, compu-method=CM_CSA3_0x244, data-constr=DC_CSA3_0x244, transfer-property=PENDING, to HUT
      frame DCT_FD4_oB30_for_SC_CAN_V3_2: id 0x236, to HUT, frame-length=64, can-addressing-mode=STANDARD, can-frame-rx-behavior=ANY, can-frame-tx-behavior=CAN-FD
        pdu DCT_FD4_oB30_for_SC_CAN_V3_2: length=64, minimum-delay=0, transmission-mode-false-timing=cyclic-timing=time-period=0.05, transmission-mode-true-timing=cyclic-timing=time-period=0.05, unused-bit-pattern=0
          signal DCT_FD4_0x236_oDCT_FD4_oB30_for_SC_CAN_V3_2: start 0, 512 bit, opaque, i-signal-type=ARRAY, init-value=64 x 0, base-type=uint8_64_none, compu-method=CM_DCT_FD4_0x236, data-constr=DC_DCT_FD4_0x236, transfer-property=PENDING, to HUT
      frame DCT3_oB30_for_SC_CAN_V3_2: id 0xA6, to HUT, frame-length=8, can-addressing-mode=STANDARD, can-frame-rx-behavior=ANY, can-frame-tx-behavior=CAN-FD
        pdu DCT3_oB30_for_SC_CAN_V3_2: length=8, minimum-delay=0, transmission-mode-false-timing=cyclic-timing=time-period=0.01, transmission-mode-true-timing=cyclic-timing=time-period=0.01, unused-bit-pattern=0
          signal DCT3_0xA6_oDCT3_oB30_for_SC_CAN_V3_2: start 0, 64 bit, opaque, i-signal-type=ARRAY, init-value=8 x 0, base-type=uint8_8_none, compu-method=CM_DCT3_0xA6, data-constr=DC_DCT3_0xA6, transfer-property=PENDING, to HUT
      frame DCT5_oB30_for_SC_CAN_V3_2: id 0x221, to HUT, frame-length=8, can-addressing-mode=STANDARD, can-frame-rx-behavior=ANY, can-frame-tx-behavior=CAN-FD
        pdu DCT5_oB30_for_SC_CAN_V3_2: length=8, minimum-delay=0, transmission-mode-false-timing=cyclic-timing=time-period=0.02, transmission-mode-true-timing=cyclic-timing=time-period=0.02, unused-bit-pattern=0
          signal DCT5_0x221_oDCT5_oB30_for_SC_CAN_V3_2: start 0, 64 bit, opaque, i-signal-type=ARRAY, init-value=8 x 0, base-type=uint8_8_none, compu-method=CM_DCT5_0x221, data-constr=DC_DCT5_0x221, transfer-property=PENDING, to HUT
      frame DDCM1_oB30_for_SC_CAN_V3_2: id 0x2CA, to HUT, frame-length=8, can-addressing-mode=STANDARD, can-frame-rx-behavior=ANY, can-frame-tx-behavior=CAN-FD
        pdu DDCM1_oB30_for_SC_CAN_V3_2: length=8, minimum-delay=0, transmission-mode-false-timing=cyclic-timing=time-period=0.1, transmission-mode-true-timing=cyclic-timing=time-period=0.1, unused-bit-pattern=0
          signal DDCM1_0x2CA_oDDCM1_oB30_for_SC_CAN_V3_2: start 0, 64 bit, opaque, i-signal-type=ARRAY, init-value=8 x 0, base-type=uint8_8_none, compu-method=CM_DDCM1_0x2CA, data-constr=DC_DDCM1_0x2CA, transfer-property=PENDING, to HUT
      frame DDCM3_oB30_for_SC_CAN_V3_2: id 0x2F7, to HUT, frame-length=8, can-addressing-mode=STANDARD, can-frame-rx-behavior=ANY, can-frame-tx-behavior=CAN-FD
        pdu DDCM3_oB30_for_SC_CAN_V3_2: length=8, minimum-delay=0, transmission-mode-false-timing=cyclic-timing=time-period=0.1, transmission-mode-true-timing=cyclic-timing=time-period=0.1, unused-bit-pattern=0
          signal DDCM3_0x2F7_oDDCM3_oB30_for_SC_CAN_V3_2: start 0, 64 bit, opaque, i-signal-type=ARRAY, init-value=8 x 0, base-type=uint8_8_none, compu-method=CM_DDCM3_0x2F7, data-constr=DC_DDCM3_0x2F7, transfer-property=PENDING, to HUT
      frame DiagFuncReq_oB30_for_SC_CAN_V3_2: id 0x760, to HUT, frame-length=8, can-addressing-mode=STANDARD, can-frame-rx-behavior=CAN-FD, can-frame-tx-behavior=CAN-FD
        n pdu DiagFuncReq_Tp_oB30_for_SC_CAN_V3_2: length=8
      frame DiagFuncReq_oB30_for_SC_CAN_V3_2_20: id 0x760, to HUT, frame-length=8, can-addressing-mode=STANDARD, can-frame-rx-behavior=CAN-20, can-frame-tx-behavior=CAN-20
        n pdu DiagFuncReq_Tp_oB30_for_SC_CAN_V3_2_20: length=8
      frame DMS_FD1_oB30_for_SC_CAN_V3_2: id 0x24D, from HUT, frame-length=64, can-addressing-mode=STANDARD, can-frame-rx-behavior=ANY, can-frame-tx-behavior=CAN-FD
        pdu DMS_FD1_oB30_for_SC_CAN_V3_2: length=64, minimum-delay=0, transmission-mode-false-timing=cyclic-timing=time-period=0.05, transmission-mode-true-timing=cyclic-timing=time-period=0.05, unused-bit-pattern=0
          signal DMS_FD1_0x24D_oDMS_FD1_oB30_for_SC_CAN_V3_2: start 0, 512 bit, opaque, i-signal-type=ARRAY, init-value=64 x 0, base-type=uint8_64_none, compu-method=CM_DMS_FD1_0x24D, data-constr=DC_DMS_FD1_0x24D, transfer-property=PENDING
      frame DOCK1_oB30_for_SC_CAN_V3_2: id 0x311, to HUT, frame-length=64, can-addressing-mode=STANDARD, can-frame-rx-behavior=ANY, can-frame-tx-behavior=CAN-FD
        pdu DOCK1_oB30_for_SC_CAN_V3_2: length=64, minimum-delay=0, transmission-mode-false-timing=cyclic-timing=time-period=0.2, transmission-mode-true-timing=cyclic-timing=time-period=0.2, unused-bit-pattern=0
          signal DOCK1_0x311_oDOCK1_oB30_for_SC_CAN_V3_2: start 0, 512 bit, opaque, i-signal-type=ARRAY, init-value=64 x 0, base-type=uint8_64_none, compu-method=CM_DOCK1_0x311, data-constr=DC_DOCK1_0x311, transfer-property=PENDING, to HUT
      frame DOCK2_oB30_for_SC_CAN_V3_2: id 0x1DF, to HUT, frame-length=64, can-addressing-mode=STANDARD, can-frame-rx-behavior=ANY, can-frame-tx-behavior=CAN-FD
        pdu DOCK2_oB30_for_SC_CAN_V3_2: length=64, minimum-delay=0, transmission-mode-false-timing=event-controlled-timing={number-of-repetitions=5, repetition-period=0.02}, transmission-mode-true-timing=event-controlled-timing={number-of-repetitions=5, repetition-period=0.02}, unused-bit-pattern=0
          signal DOCK2_0x1DF_oDOCK2_oB30_for_SC_CAN_V3_2: start 0, 512 bit, opaque, i-signal-type=ARRAY, init-value=64 x 0, base-type=uint8_64_none, compu-method=CM_DOCK2_0x1DF, data-constr=DC_DOCK2_0x1DF, transfer-property=TRIGGERED, to HUT
      frame DSC4_oB30_for_SC_CAN_V3_2: id 0x2CE, to HUT, frame-length=8, can-addressing-mode=STANDARD, can-frame-rx-behavior=ANY, can-frame-tx-behavior=CAN-FD
        pdu DSC4_oB30_for_SC_CAN_V3_2: length=8, minimum-delay=0, transmission-mode-false-timing=cyclic-timing=time-period=0.1, transmission-mode-true-timing=cyclic-timing=time-period=0.1, unused-bit-pattern=0
          signal DSC4_0x2CE_oDSC4_oB30_for_SC_CAN_V3_2: start 0, 64 bit, opaque, i-signal-type=ARRAY, init-value=8 x 0, base-type=uint8_8_none, compu-method=CM_DSC4_0x2CE, data-constr=DC_DSC4_0x2CE, transfer-property=PENDING, to HUT
      frame DSM1_oB30_for_SC_CAN_V3_2: id 0x2C1, to HUT, frame-length=8, can-addressing-mode=STANDARD, can-frame-rx-behavior=ANY, can-frame-tx-behavior=CAN-FD
        pdu DSM1_oB30_for_SC_CAN_V3_2: length=8, minimum-delay=0, transmission-mode-false-timing=cyclic-timing=time-period=0.1, transmission-mode-true-timing=cyclic-timing=time-period=0.1, unused-bit-pattern=0
          signal DSM1_0x2C1_oDSM1_oB30_for_SC_CAN_V3_2: start 0, 64 bit, opaque, i-signal-type=ARRAY, init-value=8 x 0, base-type=uint8_8_none, compu-method=CM_DSM1_0x2C1, data-constr=DC_DSM1_0x2C1, transfer-property=PENDING, to HUT
      frame DVR_FD1_oB30_for_SC_CAN_V3_2: id 0x2EC, from HUT, frame-length=64, can-addressing-mode=STANDARD, can-frame-rx-behavior=ANY, can-frame-tx-behavior=CAN-FD
        pdu DVR_FD1_oB30_for_SC_CAN_V3_2: length=64, minimum-delay=0, transmission-mode-false-timing=cyclic-timing=time-period=0.1, transmission-mode-true-timing=cyclic-timing=time-period=0.1, unused-bit-pattern=0
          signal DVR_FD1_0x2EC_oDVR_FD1_oB30_for_SC_CAN_V3_2: start 0, 512 bit, opaque, i-signal-type=ARRAY, init-value=64 x 0, base-type=uint8_64_none, compu-method=CM_DVR_FD1_0x2EC, data-constr=DC_DVR_FD1_0x2EC, transfer-property=PENDING
      frame DVR_NM_oB30_for_SC_CAN_V3_2: id 0x517, to HUT, frame-length=8, can-addressing-mode=STANDARD, can-frame-rx-behavior=ANY, can-frame-tx-behavior=CAN-20
        nm pdu DVR_NM_oB30_for_SC_CAN_V3_2: length=8, unused-bit-pattern=0
      frame DWD1_oB30_for_SC_CAN_V3_2: id 0x2B9, to HUT, frame-length=8, can-addressing-mode=STANDARD, can-frame-rx-behavior=ANY, can-frame-tx-behavior=CAN-FD
        pdu DWD1_oB30_for_SC_CAN_V3_2: length=8, minimum-delay=0, transmission-mode-false-timing=cyclic-timing=time-period=0.1, transmission-mode-true-timing=cyclic-timing=time-period=0.1, unused-bit-pattern=0
          signal DWD1_0x2B9_oDWD1_oB30_for_SC_CAN_V3_2: start 0, 64 bit, opaque, i-signal-type=ARRAY, init-value=8 x 0, base-type=uint8_8_none, compu-method=CM_DWD1_0x2B9, data-constr=DC_DWD1_0x2B9, transfer-property=PENDING, to HUT
      frame EBOOSTER_FD1_oB30_for_SC_CAN_V3_2: id 0x12D, to HUT, frame-length=64, can-addressing-mode=STANDARD, can-frame-rx-behavior=ANY, can-frame-tx-behavior=CAN-FD
        pdu EBOOSTER_FD1_oB30_for_SC_CAN_V3_2: length=64, minimum-delay=0, transmission-mode-false-timing=cyclic-timing=time-period=0.02, transmission-mode-true-timing=cyclic-timing=time-period=0.02, unused-bit-pattern=0
          signal EBOOSTER_FD1_0x12D_oEBOOSTER_FD1_oB30_for_SC_CAN_V3_2: start 0, 512 bit, opaque, i-signal-type=ARRAY, init-value=64 x 0, base-type=uint8_64_none, compu-method=CM_EBOOSTER_FD1_0x12D, data-constr=DC_EBOOSTER_FD1_0x12D, transfer-property=PENDING, to HUT
      frame ECM_PT5_oB30_for_SC_CAN_V3_2: id 0x8E, to HUT, frame-length=8, can-addressing-mode=STANDARD, can-frame-rx-behavior=ANY, can-frame-tx-behavior=CAN-FD
        pdu ECM_PT5_oB30_for_SC_CAN_V3_2: length=8, minimum-delay=0, transmission-mode-false-timing=cyclic-timing=time-period=0.01, transmission-mode-true-timing=cyclic-timing=time-period=0.01, unused-bit-pattern=0
          signal ECM_PT5_0x8E_oECM_PT5_oB30_for_SC_CAN_V3_2: start 0, 64 bit, opaque, i-signal-type=ARRAY, init-value=8 x 0, base-type=uint8_8_none, compu-method=CM_ECM_PT5_0x8E, data-constr=DC_ECM_PT5_0x8E, transfer-property=PENDING, to HUT
      frame ECM_PT6_oB30_for_SC_CAN_V3_2: id 0x290, to HUT, frame-length=8, can-addressing-mode=STANDARD, can-frame-rx-behavior=ANY, can-frame-tx-behavior=CAN-FD
        pdu ECM_PT6_oB30_for_SC_CAN_V3_2: length=8, minimum-delay=0, transmission-mode-false-timing=cyclic-timing=time-period=0.1, transmission-mode-true-timing=cyclic-timing=time-period=0.1, unused-bit-pattern=0
          signal ECM_PT6_0x290_oECM_PT6_oB30_for_SC_CAN_V3_2: start 0, 64 bit, opaque, i-signal-type=ARRAY, init-value=8 x 0, base-type=uint8_8_none, compu-method=CM_ECM_PT6_0x290, data-constr=DC_ECM_PT6_0x290, transfer-property=PENDING, to HUT
      frame ECM_PT7_oB30_for_SC_CAN_V3_2: id 0x117, to HUT, frame-length=8, can-addressing-mode=STANDARD, can-frame-rx-behavior=ANY, can-frame-tx-behavior=CAN-FD
        pdu ECM_PT7_oB30_for_SC_CAN_V3_2: length=8, minimum-delay=0, transmission-mode-false-timing=cyclic-timing=time-period=0.02, transmission-mode-true-timing=cyclic-timing=time-period=0.02, unused-bit-pattern=0
          signal ECM_PT7_0x117_oECM_PT7_oB30_for_SC_CAN_V3_2: start 0, 64 bit, opaque, i-signal-type=ARRAY, init-value=8 x 0, base-type=uint8_8_none, compu-method=CM_ECM_PT7_0x117, data-constr=DC_ECM_PT7_0x117, transfer-property=PENDING, to HUT
      frame ECM1_oB30_for_SC_CAN_V3_2: id 0x111, to HUT, frame-length=8, can-addressing-mode=STANDARD, can-frame-rx-behavior=ANY, can-frame-tx-behavior=CAN-FD
        pdu ECM1_oB30_for_SC_CAN_V3_2: length=8, minimum-delay=0, transmission-mode-false-timing=cyclic-timing=time-period=0.01, transmission-mode-true-timing=cyclic-timing=time-period=0.01, unused-bit-pattern=0
          signal ECM1_0x111_oECM1_oB30_for_SC_CAN_V3_2: start 0, 64 bit, opaque, i-signal-type=ARRAY, init-value=8 x 0, base-type=uint8_8_none, compu-method=CM_ECM1_0x111, data-constr=DC_ECM1_0x111, transfer-property=PENDING, to HUT
      frame ECM11_oB30_for_SC_CAN_V3_2: id 0x2D3, to HUT, frame-length=8, can-addressing-mode=STANDARD, can-frame-rx-behavior=ANY, can-frame-tx-behavior=CAN-FD
        pdu ECM11_oB30_for_SC_CAN_V3_2: length=8, minimum-delay=0, transmission-mode-false-timing=cyclic-timing=time-period=0.1, transmission-mode-true-timing=cyclic-timing=time-period=0.1, unused-bit-pattern=0
          signal ECM11_0x2D3_oECM11_oB30_for_SC_CAN_V3_2: start 0, 64 bit, opaque, i-signal-type=ARRAY, init-value=8 x 0, base-type=uint8_8_none, compu-method=CM_ECM11_0x2D3, data-constr=DC_ECM11_0x2D3, transfer-property=PENDING, to HUT
      frame ECM16_oB30_for_SC_CAN_V3_2: id 0x2D4, to HUT, frame-length=8, can-addressing-mode=STANDARD, can-frame-rx-behavior=ANY, can-frame-tx-behavior=CAN-FD
        pdu ECM16_oB30_for_SC_CAN_V3_2: length=8, minimum-delay=0, transmission-mode-false-timing=cyclic-timing=time-period=0.1, transmission-mode-true-timing=cyclic-timing=time-period=0.1, unused-bit-pattern=0
          signal ECM16_0x2D4_oECM16_oB30_for_SC_CAN_V3_2: start 0, 64 bit, opaque, i-signal-type=ARRAY, init-value=8 x 0, base-type=uint8_8_none, compu-method=CM_ECM16_0x2D4, data-constr=DC_ECM16_0x2D4, transfer-property=PENDING, to HUT
      frame ECM19_oB30_for_SC_CAN_V3_2: id 0x3B5, to HUT, frame-length=8, can-addressing-mode=STANDARD, can-frame-rx-behavior=ANY, can-frame-tx-behavior=CAN-FD
        pdu ECM19_oB30_for_SC_CAN_V3_2: length=8, minimum-delay=0, transmission-mode-false-timing=cyclic-timing=time-period=1, transmission-mode-true-timing=cyclic-timing=time-period=1, unused-bit-pattern=0
          signal ECM19_0x3B5_oECM19_oB30_for_SC_CAN_V3_2: start 0, 64 bit, opaque, i-signal-type=ARRAY, init-value=8 x 0, base-type=uint8_8_none, compu-method=CM_ECM19_0x3B5, data-constr=DC_ECM19_0x3B5, transfer-property=PENDING, to HUT
      frame ECM2_oB30_for_SC_CAN_V3_2: id 0x271, to HUT, frame-length=8, can-addressing-mode=STANDARD, can-frame-rx-behavior=ANY, can-frame-tx-behavior=CAN-FD
        pdu ECM2_oB30_for_SC_CAN_V3_2: length=8, minimum-delay=0, transmission-mode-false-timing=cyclic-timing=time-period=0.02, transmission-mode-true-timing=cyclic-timing=time-period=0.02, unused-bit-pattern=0
          signal ECM2_0x271_oECM2_oB30_for_SC_CAN_V3_2: start 0, 64 bit, opaque, i-signal-type=ARRAY, init-value=8 x 0, base-type=uint8_8_none, compu-method=CM_ECM2_0x271, data-constr=DC_ECM2_0x271, transfer-property=PENDING, to HUT
      frame ECM20_oB30_for_SC_CAN_V3_2: id 0x3B7, to HUT, frame-length=8, can-addressing-mode=STANDARD, can-frame-rx-behavior=ANY, can-frame-tx-behavior=CAN-FD
        pdu ECM20_oB30_for_SC_CAN_V3_2: length=8, minimum-delay=0, transmission-mode-false-timing=cyclic-timing=time-period=1, transmission-mode-true-timing=cyclic-timing=time-period=1, unused-bit-pattern=0
          signal ECM20_0x3B7_oECM20_oB30_for_SC_CAN_V3_2: start 0, 64 bit, opaque, i-signal-type=ARRAY, init-value=8 x 0, base-type=uint8_8_none, compu-method=CM_ECM20_0x3B7, data-constr=DC_ECM20_0x3B7, transfer-property=PENDING, to HUT
      frame ECM24_oB30_for_SC_CAN_V3_2: id 0x350, to HUT, frame-length=8, can-addressing-mode=STANDARD, can-frame-rx-behavior=ANY, can-frame-tx-behavior=CAN-FD
        pdu ECM24_oB30_for_SC_CAN_V3_2: length=8, minimum-delay=0, transmission-mode-false-timing=cyclic-timing=time-period=0.5, transmission-mode-true-timing=cyclic-timing=time-period=0.5, unused-bit-pattern=0
          signal ECM24_0x350_oECM24_oB30_for_SC_CAN_V3_2: start 0, 64 bit, opaque, i-signal-type=ARRAY, init-value=8 x 0, base-type=uint8_8_none, compu-method=CM_ECM24_0x350, data-constr=DC_ECM24_0x350, transfer-property=PENDING, to HUT
      frame ECM3_oB30_for_SC_CAN_V3_2: id 0x371, to HUT, frame-length=8, can-addressing-mode=STANDARD, can-frame-rx-behavior=ANY, can-frame-tx-behavior=CAN-FD
        pdu ECM3_oB30_for_SC_CAN_V3_2: length=8, minimum-delay=0, transmission-mode-false-timing=cyclic-timing=time-period=0.1, transmission-mode-true-timing=cyclic-timing=time-period=0.1, unused-bit-pattern=0
          signal ECM3_0x371_oECM3_oB30_for_SC_CAN_V3_2: start 0, 64 bit, opaque, i-signal-type=ARRAY, init-value=8 x 0, base-type=uint8_8_none, compu-method=CM_ECM3_0x371, data-constr=DC_ECM3_0x371, transfer-property=PENDING, to HUT
      frame ECM4_oB30_for_SC_CAN_V3_2: id 0x82, to HUT, frame-length=8, can-addressing-mode=STANDARD, can-frame-rx-behavior=ANY, can-frame-tx-behavior=CAN-FD
        pdu ECM4_oB30_for_SC_CAN_V3_2: length=8, minimum-delay=0, transmission-mode-false-timing=cyclic-timing=time-period=0.01, transmission-mode-true-timing=cyclic-timing=time-period=0.01, unused-bit-pattern=0
          signal ECM4_0x82_oECM4_oB30_for_SC_CAN_V3_2: start 0, 64 bit, opaque, i-signal-type=ARRAY, init-value=8 x 0, base-type=uint8_8_none, compu-method=CM_ECM4_0x82, data-constr=DC_ECM4_0x82, transfer-property=PENDING, to HUT
      frame ECM7_oB30_for_SC_CAN_V3_2: id 0x84, to HUT, frame-length=8, can-addressing-mode=STANDARD, can-frame-rx-behavior=ANY, can-frame-tx-behavior=CAN-FD
        pdu ECM7_oB30_for_SC_CAN_V3_2: length=8, minimum-delay=0, transmission-mode-false-timing=cyclic-timing=time-period=0.01, transmission-mode-true-timing=cyclic-timing=time-period=0.01, unused-bit-pattern=0
          signal ECM7_0x84_oECM7_oB30_for_SC_CAN_V3_2: start 0, 64 bit, opaque, i-signal-type=ARRAY, init-value=8 x 0, base-type=uint8_8_none, compu-method=CM_ECM7_0x84, data-constr=DC_ECM7_0x84, transfer-property=PENDING, to HUT
      frame ECM9_oB30_for_SC_CAN_V3_2: id 0x102, to HUT, frame-length=8, can-addressing-mode=STANDARD, can-frame-rx-behavior=ANY, can-frame-tx-behavior=CAN-FD
        pdu ECM9_oB30_for_SC_CAN_V3_2: length=8, minimum-delay=0, transmission-mode-false-timing=cyclic-timing=time-period=0.02, transmission-mode-true-timing=cyclic-timing=time-period=0.02, unused-bit-pattern=0
          signal ECM9_0x102_oECM9_oB30_for_SC_CAN_V3_2: start 0, 64 bit, opaque, i-signal-type=ARRAY, init-value=8 x 0, base-type=uint8_8_none, compu-method=CM_ECM9_0x102, data-constr=DC_ECM9_0x102, transfer-property=PENDING, to HUT
      frame EEM1_oB30_for_SC_CAN_V3_2: id 0x2A8, to HUT, frame-length=8, can-addressing-mode=STANDARD, can-frame-rx-behavior=ANY, can-frame-tx-behavior=CAN-FD
        pdu EEM1_oB30_for_SC_CAN_V3_2: length=8, minimum-delay=0, transmission-mode-false-timing=cyclic-timing=time-period=0.1, transmission-mode-true-timing=cyclic-timing=time-period=0.1, unused-bit-pattern=0
          signal EEM1_0x2A8_oEEM1_oB30_for_SC_CAN_V3_2: start 0, 64 bit, opaque, i-signal-type=ARRAY, init-value=8 x 0, base-type=uint8_8_none, compu-method=CM_EEM1_0x2A8, data-constr=DC_EEM1_0x2A8, transfer-property=PENDING, to HUT
      frame ELD1_oB30_for_SC_CAN_V3_2: id 0x152, to HUT, frame-length=8, can-addressing-mode=STANDARD, can-frame-rx-behavior=ANY, can-frame-tx-behavior=CAN-FD
        pdu ELD1_oB30_for_SC_CAN_V3_2: length=8, minimum-delay=0, transmission-mode-false-timing=cyclic-timing=time-period=0.02, transmission-mode-true-timing=cyclic-timing=time-period=0.02, unused-bit-pattern=0
          signal ELD1_0x152_oELD1_oB30_for_SC_CAN_V3_2: start 0, 64 bit, opaque, i-signal-type=ARRAY, init-value=8 x 0, base-type=uint8_8_none, compu-method=CM_ELD1_0x152, data-constr=DC_ELD1_0x152, transfer-property=PENDING, to HUT
      frame EPB1_oB30_for_SC_CAN_V3_2: id 0x16B, to HUT, frame-length=8, can-addressing-mode=STANDARD, can-frame-rx-behavior=ANY, can-frame-tx-behavior=CAN-FD
        pdu EPB1_oB30_for_SC_CAN_V3_2: length=8, minimum-delay=0, transmission-mode-false-timing=cyclic-timing=time-period=0.02, transmission-mode-true-timing=cyclic-timing=time-period=0.02, unused-bit-pattern=0
          signal EPB1_0x16B_oEPB1_oB30_for_SC_CAN_V3_2: start 0, 64 bit, opaque, i-signal-type=ARRAY, init-value=8 x 0, base-type=uint8_8_none, compu-method=CM_EPB1_0x16B, data-constr=DC_EPB1_0x16B, transfer-property=PENDING, to HUT
      frame EPS_FD1_oB30_for_SC_CAN_V3_2: id 0x147, to HUT, frame-length=64, can-addressing-mode=STANDARD, can-frame-rx-behavior=ANY, can-frame-tx-behavior=CAN-FD
        pdu EPS_FD1_oB30_for_SC_CAN_V3_2: length=64, minimum-delay=0, transmission-mode-false-timing=cyclic-timing=time-period=0.02, transmission-mode-true-timing=cyclic-timing=time-period=0.02, unused-bit-pattern=0
          signal EPS_FD1_0x147_oEPS_FD1_oB30_for_SC_CAN_V3_2: start 0, 512 bit, opaque, i-signal-type=ARRAY, init-value=64 x 0, base-type=uint8_64_none, compu-method=CM_EPS_FD1_0x147, data-constr=DC_EPS_FD1_0x147, transfer-property=PENDING, to HUT
      frame ESCL2_oB30_for_SC_CAN_V3_2: id 0x303, to HUT, frame-length=8, can-addressing-mode=STANDARD, can-frame-rx-behavior=ANY, can-frame-tx-behavior=CAN-FD
        pdu ESCL2_oB30_for_SC_CAN_V3_2: length=8, minimum-delay=0, transmission-mode-false-timing=cyclic-timing=time-period=0.2, transmission-mode-true-timing=cyclic-timing=time-period=0.2, unused-bit-pattern=0
          signal ESCL2_0x303_oESCL2_oB30_for_SC_CAN_V3_2: start 0, 64 bit, opaque, i-signal-type=ARRAY, init-value=8 x 0, base-type=uint8_8_none, compu-method=CM_ESCL2_0x303, data-constr=DC_ESCL2_0x303, transfer-property=PENDING, to HUT
      frame ESP_FD2_oB30_for_SC_CAN_V3_2: id 0x137, to HUT, frame-length=64, can-addressing-mode=STANDARD, can-frame-rx-behavior=ANY, can-frame-tx-behavior=CAN-FD
        secured i pdu ESP_FD2_Sc_oB30_for_SC_CAN_V3_2: length=64, authentication-props=AuthESP_FD2_Sc_oB30_for_SC_CAN_V3_2, freshness-props=FreshnessESP_FD2_Sc_oB30_for_SC_CAN_V3_2, payload=PT_ESP_FD2, secure-communication-props={auth-info-tx-length=48, data-id=311, freshness-value-length=64, freshness-value-tx-length=16}
      frame ESP11_oB30_for_SC_CAN_V3_2: id 0xC8, to HUT, frame-length=8, can-addressing-mode=STANDARD, can-frame-rx-behavior=ANY, can-frame-tx-behavior=CAN-FD
        pdu ESP11_oB30_for_SC_CAN_V3_2: length=8, minimum-delay=0, transmission-mode-false-timing=cyclic-timing=time-period=0.01, transmission-mode-true-timing=cyclic-timing=time-period=0.01, unused-bit-pattern=0
          signal ESP11_0xC8_oESP11_oB30_for_SC_CAN_V3_2: start 0, 64 bit, opaque, i-signal-type=ARRAY, init-value=8 x 0, base-type=uint8_8_none, compu-method=CM_ESP11_0xC8, data-constr=DC_ESP11_0xC8, transfer-property=PENDING, to HUT
      frame ESP8_oB30_for_SC_CAN_V3_2: id 0x170, to HUT, frame-length=8, can-addressing-mode=STANDARD, can-frame-rx-behavior=ANY, can-frame-tx-behavior=CAN-FD
        pdu ESP8_oB30_for_SC_CAN_V3_2: length=8, minimum-delay=0, transmission-mode-false-timing=cyclic-timing=time-period=0.02, transmission-mode-true-timing=cyclic-timing=time-period=0.02, unused-bit-pattern=0
          signal ESP8_0x170_oESP8_oB30_for_SC_CAN_V3_2: start 0, 64 bit, opaque, i-signal-type=ARRAY, init-value=8 x 0, base-type=uint8_8_none, compu-method=CM_ESP8_0x170, data-constr=DC_ESP8_0x170, transfer-property=PENDING, to HUT
      frame ETC2_oB30_for_SC_CAN_V3_2: id 0x1F1, to HUT, frame-length=8, can-addressing-mode=STANDARD, can-frame-rx-behavior=ANY, can-frame-tx-behavior=CAN-FD
        pdu ETC2_oB30_for_SC_CAN_V3_2: length=8, minimum-delay=0, transmission-mode-false-timing=event-controlled-timing={number-of-repetitions=5, repetition-period=0.02}, transmission-mode-true-timing=event-controlled-timing={number-of-repetitions=5, repetition-period=0.02}, unused-bit-pattern=0
          signal ETC2_0x1F1_oETC2_oB30_for_SC_CAN_V3_2: start 0, 64 bit, opaque, i-signal-type=ARRAY, init-value=8 x 0, base-type=uint8_8_none, compu-method=CM_ETC2_0x1F1, data-constr=DC_ETC2_0x1F1, transfer-property=TRIGGERED, to HUT
      frame ETC3_oB30_for_SC_CAN_V3_2: id 0x344, to HUT, frame-length=8, can-addressing-mode=STANDARD, can-frame-rx-behavior=ANY, can-frame-tx-behavior=CAN-FD
        pdu ETC3_oB30_for_SC_CAN_V3_2: length=8, minimum-delay=0, transmission-mode-false-timing=cyclic-timing=time-period=0.5, transmission-mode-true-timing=cyclic-timing=time-period=0.5, unused-bit-pattern=0
          signal ETC3_0x344_oETC3_oB30_for_SC_CAN_V3_2: start 0, 64 bit, opaque, i-signal-type=ARRAY, init-value=8 x 0, base-type=uint8_8_none, compu-method=CM_ETC3_0x344, data-constr=DC_ETC3_0x344, transfer-property=PENDING, to HUT
      frame ETC4_oB30_for_SC_CAN_V3_2: id 0x1F2, to HUT, frame-length=8, can-addressing-mode=STANDARD, can-frame-rx-behavior=ANY, can-frame-tx-behavior=CAN-FD
        pdu ETC4_oB30_for_SC_CAN_V3_2: length=8, minimum-delay=0, transmission-mode-false-timing=event-controlled-timing={number-of-repetitions=5, repetition-period=0.02}, transmission-mode-true-timing=event-controlled-timing={number-of-repetitions=5, repetition-period=0.02}, unused-bit-pattern=0
          signal ETC4_0x1F2_oETC4_oB30_for_SC_CAN_V3_2: start 0, 64 bit, opaque, i-signal-type=ARRAY, init-value=8 x 0, base-type=uint8_8_none, compu-method=CM_ETC4_0x1F2, data-constr=DC_ETC4_0x1F2, transfer-property=TRIGGERED, to HUT
      frame F_PBOX1_oB30_for_SC_CAN_V3_2: id 0x19B, to HUT, frame-length=8, can-addressing-mode=STANDARD, can-frame-rx-behavior=ANY, can-frame-tx-behavior=CAN-FD
        pdu F_PBOX1_oB30_for_SC_CAN_V3_2: length=8, minimum-delay=0, transmission-mode-false-timing=cyclic-timing=time-period=0.05, transmission-mode-true-timing=cyclic-timing=time-period=0.05, unused-bit-pattern=0
          signal F_PBOX1_0x19B_oF_PBOX1_oB30_for_SC_CAN_V3_2: start 0, 64 bit, opaque, i-signal-type=ARRAY, init-value=8 x 0, base-type=uint8_8_none, compu-method=CM_F_PBOX1_0x19B, data-constr=DC_F_PBOX1_0x19B, transfer-property=PENDING, to HUT
      frame GLO_NASS1_oB30_for_SC_CAN_V3_2: id 0x56, to HUT, frame-length=8, can-addressing-mode=STANDARD, can-frame-rx-behavior=ANY, can-frame-tx-behavior=CAN-FD
        pdu GLO_NASS1_oB30_for_SC_CAN_V3_2: length=8, minimum-delay=0, transmission-mode-false-timing=event-controlled-timing={number-of-repetitions=5, repetition-period=0.02}, transmission-mode-true-timing=event-controlled-timing={number-of-repetitions=5, repetition-period=0.02}, unused-bit-pattern=0
          signal GLO_NASS1_0x56_oGLO_NASS1_oB30_for_SC_CAN_V3_2: start 0, 64 bit, opaque, i-signal-type=ARRAY, init-value=8 x 0, base-type=uint8_8_none, compu-method=CM_GLO_NASS1_0x56, data-constr=DC_GLO_NASS1_0x56, transfer-property=TRIGGERED, to HUT
      frame GW_FD1_oB30_for_SC_CAN_V3_2: id 0x2BB, to HUT, frame-length=64, can-addressing-mode=STANDARD, can-frame-rx-behavior=ANY, can-frame-tx-behavior=CAN-FD
        pdu GW_FD1_oB30_for_SC_CAN_V3_2: length=64, minimum-delay=0, transmission-mode-false-timing=cyclic-timing=time-period=0.1, transmission-mode-true-timing=cyclic-timing=time-period=0.1, unused-bit-pattern=0
          signal GW_FD1_0x2BB_oGW_FD1_oB30_for_SC_CAN_V3_2: start 0, 512 bit, opaque, i-signal-type=ARRAY, init-value=64 x 0, base-type=uint8_64_none, compu-method=CM_GW_FD1_0x2BB, data-constr=DC_GW_FD1_0x2BB, transfer-property=PENDING, to HUT
      frame GW_OTA_oB30_for_SC_CAN_V3_2: id 0x1D9, to HUT, frame-length=8, can-addressing-mode=STANDARD, can-frame-rx-behavior=ANY, can-frame-tx-behavior=CAN-FD
        pdu GW_OTA_oB30_for_SC_CAN_V3_2: length=8, minimum-delay=0, transmission-mode-false-timing=event-controlled-timing={number-of-repetitions=5, repetition-period=0.02}, transmission-mode-true-timing=event-controlled-timing={number-of-repetitions=5, repetition-period=0.02}, unused-bit-pattern=0
          signal GW_OTA_0x1D9_oGW_OTA_oB30_for_SC_CAN_V3_2: start 0, 64 bit, opaque, i-signal-type=ARRAY, init-value=8 x 0, base-type=uint8_8_none, compu-method=CM_GW_OTA_0x1D9, data-constr=DC_GW_OTA_0x1D9, transfer-property=TRIGGERED, to HUT
      frame GW_Sync_Req_oB30_for_SC_CAN_V3_2: id 0x461, to HUT, frame-length=16, can-addressing-mode=STANDARD, can-frame-rx-behavior=ANY, can-frame-tx-behavior=CAN-FD
        secured i pdu GW_Sync_Req_Sc_oB30_for_SC_CAN_V3_2: length=16, authentication-props=AuthGW_Sync_Req_Sc_oB30_for_SC_CAN_V3_2, freshness-props=FreshnessGW_Sync_Req_Sc_oB30_for_SC_CAN_V3_2, payload=PT_GW_Sync_Req, secure-communication-props={auth-info-tx-length=88, data-id=1121, freshness-value-length=40, freshness-value-tx-length=40}
      frame HAP_FD1_oB30_for_SC_CAN_V3_2: id 0x15B, to HUT, frame-length=64, can-addressing-mode=STANDARD, can-frame-rx-behavior=ANY, can-frame-tx-behavior=CAN-FD
        pdu HAP_FD1_oB30_for_SC_CAN_V3_2: length=64, minimum-delay=0, transmission-mode-false-timing=cyclic-timing=time-period=0.02, transmission-mode-true-timing=cyclic-timing=time-period=0.02, unused-bit-pattern=0
          signal HAP_FD1_0x15B_oHAP_FD1_oB30_for_SC_CAN_V3_2: start 0, 512 bit, opaque, i-signal-type=ARRAY, init-value=64 x 0, base-type=uint8_64_none, compu-method=CM_HAP_FD1_0x15B, data-constr=DC_HAP_FD1_0x15B, transfer-property=PENDING, to HUT
      frame HAP_FD2_oB30_for_SC_CAN_V3_2: id 0x274, to HUT, frame-length=64, can-addressing-mode=STANDARD, can-frame-rx-behavior=ANY, can-frame-tx-behavior=CAN-FD
        pdu HAP_FD2_oB30_for_SC_CAN_V3_2: length=64, minimum-delay=0, transmission-mode-false-timing=cyclic-timing=time-period=0.05, transmission-mode-true-timing=cyclic-timing=time-period=0.05, unused-bit-pattern=0
          signal HAP_FD2_0x274_oHAP_FD2_oB30_for_SC_CAN_V3_2: start 0, 512 bit, opaque, i-signal-type=ARRAY, init-value=64 x 0, base-type=uint8_64_none, compu-method=CM_HAP_FD2_0x274, data-constr=DC_HAP_FD2_0x274, transfer-property=PENDING, to HUT
      frame HAP_FD3_oB30_for_SC_CAN_V3_2: id 0x298, to HUT, frame-length=64, can-addressing-mode=STANDARD, can-frame-rx-behavior=ANY, can-frame-tx-behavior=CAN-FD
        pdu HAP_FD3_oB30_for_SC_CAN_V3_2: length=64, minimum-delay=0, transmission-mode-false-timing=cyclic-timing=time-period=0.1, transmission-mode-true-timing=cyclic-timing=time-period=0.1, unused-bit-pattern=0
          signal HAP_FD3_0x298_oHAP_FD3_oB30_for_SC_CAN_V3_2: start 0, 512 bit, opaque, i-signal-type=ARRAY, init-value=64 x 0, base-type=uint8_64_none, compu-method=CM_HAP_FD3_0x298, data-constr=DC_HAP_FD3_0x298, transfer-property=PENDING, to HUT
      frame HAP_FD6_oB30_for_SC_CAN_V3_2: id 0x289, to HUT, frame-length=64, can-addressing-mode=STANDARD, can-frame-rx-behavior=ANY, can-frame-tx-behavior=CAN-FD
        pdu HAP_FD6_oB30_for_SC_CAN_V3_2: length=64, minimum-delay=0, transmission-mode-false-timing=cyclic-timing=time-period=0.1, transmission-mode-true-timing=cyclic-timing=time-period=0.1, unused-bit-pattern=0
          signal HAP_FD6_0x289_oHAP_FD6_oB30_for_SC_CAN_V3_2: start 0, 512 bit, opaque, i-signal-type=ARRAY, init-value=64 x 0, base-type=uint8_64_none, compu-method=CM_HAP_FD6_0x289, data-constr=DC_HAP_FD6_0x289, transfer-property=PENDING, to HUT
      frame HAP_FD7_oB30_for_SC_CAN_V3_2: id 0x29B, to HUT, frame-length=64, can-addressing-mode=STANDARD, can-frame-rx-behavior=ANY, can-frame-tx-behavior=CAN-FD
        pdu HAP_FD7_oB30_for_SC_CAN_V3_2: length=64, minimum-delay=0, transmission-mode-false-timing=cyclic-timing=time-period=0.1, transmission-mode-true-timing=cyclic-timing=time-period=0.1, unused-bit-pattern=0
          signal HAP_FD7_0x29B_oHAP_FD7_oB30_for_SC_CAN_V3_2: start 0, 512 bit, opaque, i-signal-type=ARRAY, init-value=64 x 0, base-type=uint8_64_none, compu-method=CM_HAP_FD7_0x29B, data-constr=DC_HAP_FD7_0x29B, transfer-property=PENDING, to HUT
      frame HCM_L1_oB30_for_SC_CAN_V3_2: id 0x308, to HUT, frame-length=8, can-addressing-mode=STANDARD, can-frame-rx-behavior=ANY, can-frame-tx-behavior=CAN-FD
        pdu HCM_L1_oB30_for_SC_CAN_V3_2: length=8, minimum-delay=0, transmission-mode-false-timing=cyclic-timing=time-period=0.2, transmission-mode-true-timing=cyclic-timing=time-period=0.2, unused-bit-pattern=0
          signal HCM_L1_0x308_oHCM_L1_oB30_for_SC_CAN_V3_2: start 0, 64 bit, opaque, i-signal-type=ARRAY, init-value=8 x 0, base-type=uint8_8_none, compu-method=CM_HCM_L1_0x308, data-constr=DC_HCM_L1_0x308, transfer-property=PENDING, to HUT
      frame HCM_L2_oB30_for_SC_CAN_V3_2: id 0x304, to HUT, frame-length=8, can-addressing-mode=STANDARD, can-frame-rx-behavior=ANY, can-frame-tx-behavior=CAN-FD
        pdu HCM_L2_oB30_for_SC_CAN_V3_2: length=8, minimum-delay=0, transmission-mode-false-timing=cyclic-timing=time-period=0.2, transmission-mode-true-timing=cyclic-timing=time-period=0.2, unused-bit-pattern=0
          signal HCM_L2_0x304_oHCM_L2_oB30_for_SC_CAN_V3_2: start 0, 64 bit, opaque, i-signal-type=ARRAY, init-value=8 x 0, base-type=uint8_8_none, compu-method=CM_HCM_L2_0x304, data-constr=DC_HCM_L2_0x304, transfer-property=PENDING, to HUT
      frame HCM_R1_oB30_for_SC_CAN_V3_2: id 0x30D, to HUT, frame-length=8, can-addressing-mode=STANDARD, can-frame-rx-behavior=ANY, can-frame-tx-behavior=CAN-FD
        pdu HCM_R1_oB30_for_SC_CAN_V3_2: length=8, minimum-delay=0, transmission-mode-false-timing=cyclic-timing=time-period=0.2, transmission-mode-true-timing=cyclic-timing=time-period=0.2, unused-bit-pattern=0
          signal HCM_R1_0x30D_oHCM_R1_oB30_for_SC_CAN_V3_2: start 0, 64 bit, opaque, i-signal-type=ARRAY, init-value=8 x 0, base-type=uint8_8_none, compu-method=CM_HCM_R1_0x30D, data-constr=DC_HCM_R1_0x30D, transfer-property=PENDING, to HUT
      frame HCM_R2_oB30_for_SC_CAN_V3_2: id 0x330, to HUT, frame-length=8, can-addressing-mode=STANDARD, can-frame-rx-behavior=ANY, can-frame-tx-behavior=CAN-FD
        pdu HCM_R2_oB30_for_SC_CAN_V3_2: length=8, minimum-delay=0, transmission-mode-false-timing=cyclic-timing=time-period=0.2, transmission-mode-true-timing=cyclic-timing=time-period=0.2, unused-bit-pattern=0
          signal HCM_R2_0x330_oHCM_R2_oB30_for_SC_CAN_V3_2: start 0, 64 bit, opaque, i-signal-type=ARRAY, init-value=8 x 0, base-type=uint8_8_none, compu-method=CM_HCM_R2_0x330, data-constr=DC_HCM_R2_0x330, transfer-property=PENDING, to HUT
      frame HCU_FD1_oB30_for_SC_CAN_V3_2: id 0x60, to HUT, frame-length=64, can-addressing-mode=STANDARD, can-frame-rx-behavior=ANY, can-frame-tx-behavior=CAN-FD
        pdu HCU_FD1_oB30_for_SC_CAN_V3_2: length=64, minimum-delay=0, transmission-mode-false-timing=cyclic-timing=time-period=0.01, transmission-mode-true-timing=cyclic-timing=time-period=0.01, unused-bit-pattern=0
          signal HCU_FD1_0x60_oHCU_FD1_oB30_for_SC_CAN_V3_2: start 0, 512 bit, opaque, i-signal-type=ARRAY, init-value=64 x 0, base-type=uint8_64_none, compu-method=CM_HCU_FD1_0x60, data-constr=DC_HCU_FD1_0x60, transfer-property=PENDING, to HUT
      frame HCU_HC16_oB30_for_SC_CAN_V3_2: id 0x9E, to HUT, frame-length=8, can-addressing-mode=STANDARD, can-frame-rx-behavior=ANY, can-frame-tx-behavior=CAN-FD
        pdu HCU_HC16_oB30_for_SC_CAN_V3_2: length=8, minimum-delay=0, transmission-mode-false-timing=cyclic-timing=time-period=0.01, transmission-mode-true-timing=cyclic-timing=time-period=0.01, unused-bit-pattern=0
          signal HCU_HC16_0x9E_oHCU_HC16_oB30_for_SC_CAN_V3_2: start 0, 64 bit, opaque, i-signal-type=ARRAY, init-value=8 x 0, base-type=uint8_8_none, compu-method=CM_HCU_HC16_0x9E, data-constr=DC_HCU_HC16_0x9E, transfer-property=PENDING, to HUT
      frame HCU_HC3_oB30_for_SC_CAN_V3_2: id 0x268, to HUT, frame-length=8, can-addressing-mode=STANDARD, can-frame-rx-behavior=ANY, can-frame-tx-behavior=CAN-FD
        pdu HCU_HC3_oB30_for_SC_CAN_V3_2: length=8, minimum-delay=0, transmission-mode-false-timing=cyclic-timing=time-period=0.05, transmission-mode-true-timing=cyclic-timing=time-period=0.05, unused-bit-pattern=0
          signal HCU_HC3_0x268_oHCU_HC3_oB30_for_SC_CAN_V3_2: start 0, 64 bit, opaque, i-signal-type=ARRAY, init-value=8 x 0, base-type=uint8_8_none, compu-method=CM_HCU_HC3_0x268, data-constr=DC_HCU_HC3_0x268, transfer-property=PENDING, to HUT
      frame HCU_HC6_oB30_for_SC_CAN_V3_2: id 0x314, to HUT, frame-length=8, can-addressing-mode=STANDARD, can-frame-rx-behavior=ANY, can-frame-tx-behavior=CAN-FD
        pdu HCU_HC6_oB30_for_SC_CAN_V3_2: length=8, minimum-delay=0, transmission-mode-false-timing=cyclic-timing=time-period=0.2, transmission-mode-true-timing=cyclic-timing=time-period=0.2, unused-bit-pattern=0
          signal HCU_HC6_0x314_oHCU_HC6_oB30_for_SC_CAN_V3_2: start 0, 64 bit, opaque, i-signal-type=ARRAY, init-value=8 x 0, base-type=uint8_8_none, compu-method=CM_HCU_HC6_0x314, data-constr=DC_HCU_HC6_0x314, transfer-property=PENDING, to HUT
      frame HCU_HC7_oB30_for_SC_CAN_V3_2: id 0x3C2, to HUT, frame-length=8, can-addressing-mode=STANDARD, can-frame-rx-behavior=ANY, can-frame-tx-behavior=CAN-FD
        pdu HCU_HC7_oB30_for_SC_CAN_V3_2: length=8, minimum-delay=0, transmission-mode-false-timing=cyclic-timing=time-period=1, transmission-mode-true-timing=cyclic-timing=time-period=1, unused-bit-pattern=0
          signal HCU_HC7_0x3C2_oHCU_HC7_oB30_for_SC_CAN_V3_2: start 0, 64 bit, opaque, i-signal-type=ARRAY, init-value=8 x 0, base-type=uint8_8_none, compu-method=CM_HCU_HC7_0x3C2, data-constr=DC_HCU_HC7_0x3C2, transfer-property=PENDING, to HUT
      frame HCU_HC8_oB30_for_SC_CAN_V3_2: id 0x1E2, to HUT, frame-length=8, can-addressing-mode=STANDARD, can-frame-rx-behavior=ANY, can-frame-tx-behavior=CAN-FD
        pdu HCU_HC8_oB30_for_SC_CAN_V3_2: length=8, minimum-delay=0, transmission-mode-false-timing=event-controlled-timing={number-of-repetitions=5, repetition-period=0.02}, transmission-mode-true-timing=event-controlled-timing={number-of-repetitions=5, repetition-period=0.02}, unused-bit-pattern=0
          signal HCU_HC8_0x1E2_oHCU_HC8_oB30_for_SC_CAN_V3_2: start 0, 64 bit, opaque, i-signal-type=ARRAY, init-value=8 x 0, base-type=uint8_8_none, compu-method=CM_HCU_HC8_0x1E2, data-constr=DC_HCU_HC8_0x1E2, transfer-property=TRIGGERED, to HUT
      frame HCU_HP5_oB30_for_SC_CAN_V3_2: id 0x201, to HUT, frame-length=8, can-addressing-mode=STANDARD, can-frame-rx-behavior=ANY, can-frame-tx-behavior=CAN-FD
        pdu HCU_HP5_oB30_for_SC_CAN_V3_2: length=8, minimum-delay=0, transmission-mode-false-timing=cyclic-timing=time-period=0.05, transmission-mode-true-timing=cyclic-timing=time-period=0.05, unused-bit-pattern=0
          signal HCU_HP5_0x201_oHCU_HP5_oB30_for_SC_CAN_V3_2: start 0, 64 bit, opaque, i-signal-type=ARRAY, init-value=8 x 0, base-type=uint8_8_none, compu-method=CM_HCU_HP5_0x201, data-constr=DC_HCU_HP5_0x201, transfer-property=PENDING, to HUT
      frame HCU_HP6_oB30_for_SC_CAN_V3_2: id 0x11A, to HUT, frame-length=8, can-addressing-mode=STANDARD, can-frame-rx-behavior=ANY, can-frame-tx-behavior=CAN-FD
        pdu HCU_HP6_oB30_for_SC_CAN_V3_2: length=8, minimum-delay=0, transmission-mode-false-timing=cyclic-timing=time-period=0.02, transmission-mode-true-timing=cyclic-timing=time-period=0.02, unused-bit-pattern=0
          signal HCU_HP6_0x11A_oHCU_HP6_oB30_for_SC_CAN_V3_2: start 0, 64 bit, opaque, i-signal-type=ARRAY, init-value=8 x 0, base-type=uint8_8_none, compu-method=CM_HCU_HP6_0x11A, data-constr=DC_HCU_HP6_0x11A, transfer-property=PENDING, to HUT
      frame HCU_HP8_oB30_for_SC_CAN_V3_2: id 0xF9, to HUT, frame-length=8, can-addressing-mode=STANDARD, can-frame-rx-behavior=ANY, can-frame-tx-behavior=CAN-FD
        pdu HCU_HP8_oB30_for_SC_CAN_V3_2: length=8, minimum-delay=0, transmission-mode-false-timing=cyclic-timing=time-period=0.01, transmission-mode-true-timing=cyclic-timing=time-period=0.01, unused-bit-pattern=0
          signal HCU_HP8_0xF9_oHCU_HP8_oB30_for_SC_CAN_V3_2: start 0, 64 bit, opaque, i-signal-type=ARRAY, init-value=8 x 0, base-type=uint8_8_none, compu-method=CM_HCU_HP8_0xF9, data-constr=DC_HCU_HP8_0xF9, transfer-property=PENDING, to HUT
      frame HCU_PT4_oB30_for_SC_CAN_V3_2: id 0x2FA, to HUT, frame-length=8, can-addressing-mode=STANDARD, can-frame-rx-behavior=ANY, can-frame-tx-behavior=CAN-FD
        pdu HCU_PT4_oB30_for_SC_CAN_V3_2: length=8, minimum-delay=0, transmission-mode-false-timing=cyclic-timing=time-period=0.1, transmission-mode-true-timing=cyclic-timing=time-period=0.1, unused-bit-pattern=0
          signal HCU_PT4_0x2FA_oHCU_PT4_oB30_for_SC_CAN_V3_2: start 0, 64 bit, opaque, i-signal-type=ARRAY, init-value=8 x 0, base-type=uint8_8_none, compu-method=CM_HCU_PT4_0x2FA, data-constr=DC_HCU_PT4_0x2FA, transfer-property=PENDING, to HUT
      frame HCU_PT5_oB30_for_SC_CAN_V3_2: id 0x14A, to HUT, frame-length=8, can-addressing-mode=STANDARD, can-frame-rx-behavior=ANY, can-frame-tx-behavior=CAN-FD
        pdu HCU_PT5_oB30_for_SC_CAN_V3_2: length=8, minimum-delay=0, transmission-mode-false-timing=cyclic-timing=time-period=0.02, transmission-mode-true-timing=cyclic-timing=time-period=0.02, unused-bit-pattern=0
          signal HCU_PT5_0x14A_oHCU_PT5_oB30_for_SC_CAN_V3_2: start 0, 64 bit, opaque, i-signal-type=ARRAY, init-value=8 x 0, base-type=uint8_8_none, compu-method=CM_HCU_PT5_0x14A, data-constr=DC_HCU_PT5_0x14A, transfer-property=PENDING, to HUT
      frame HCU_PT7_oB30_for_SC_CAN_V3_2: id 0x248, to HUT, frame-length=8, can-addressing-mode=STANDARD, can-frame-rx-behavior=ANY, can-frame-tx-behavior=CAN-FD
        pdu HCU_PT7_oB30_for_SC_CAN_V3_2: length=8, minimum-delay=0, transmission-mode-false-timing=cyclic-timing=time-period=0.05, transmission-mode-true-timing=cyclic-timing=time-period=0.05, unused-bit-pattern=0
          signal HCU_PT7_0x248_oHCU_PT7_oB30_for_SC_CAN_V3_2: start 0, 64 bit, opaque, i-signal-type=ARRAY, init-value=8 x 0, base-type=uint8_8_none, compu-method=CM_HCU_PT7_0x248, data-constr=DC_HCU_PT7_0x248, transfer-property=PENDING, to HUT
      frame HCU_PT8_oB30_for_SC_CAN_V3_2: id 0x1C0, to HUT, frame-length=8, can-addressing-mode=STANDARD, can-frame-rx-behavior=ANY, can-frame-tx-behavior=CAN-FD
        pdu HCU_PT8_oB30_for_SC_CAN_V3_2: length=8, minimum-delay=0, transmission-mode-false-timing=cyclic-timing=time-period=0.05, transmission-mode-true-timing=cyclic-timing=time-period=0.05, unused-bit-pattern=0
          signal HCU_PT8_0x1C0_oHCU_PT8_oB30_for_SC_CAN_V3_2: start 0, 64 bit, opaque, i-signal-type=ARRAY, init-value=8 x 0, base-type=uint8_8_none, compu-method=CM_HCU_PT8_0x1C0, data-constr=DC_HCU_PT8_0x1C0, transfer-property=PENDING, to HUT
      frame HUD1_oB30_for_SC_CAN_V3_2: id 0x325, to HUT, frame-length=8, can-addressing-mode=STANDARD, can-frame-rx-behavior=ANY, can-frame-tx-behavior=CAN-FD
        pdu HUD1_oB30_for_SC_CAN_V3_2: length=8, minimum-delay=0, transmission-mode-false-timing=cyclic-timing=time-period=0.2, transmission-mode-true-timing=cyclic-timing=time-period=0.2, unused-bit-pattern=0
          signal HUD1_0x325_oHUD1_oB30_for_SC_CAN_V3_2: start 0, 64 bit, opaque, i-signal-type=ARRAY, init-value=8 x 0, base-type=uint8_8_none, compu-method=CM_HUD1_0x325, data-constr=DC_HUD1_0x325, transfer-property=PENDING, to HUT
      frame HUT_FD1_oB30_for_SC_CAN_V3_2: id 0x2C3, from HUT, frame-length=64, can-addressing-mode=STANDARD, can-frame-rx-behavior=ANY, can-frame-tx-behavior=CAN-FD
        secured i pdu HUT_FD1_Sc_oB30_for_SC_CAN_V3_2: length=64, authentication-props=AuthHUT_FD1_Sc_oB30_for_SC_CAN_V3_2, freshness-props=FreshnessHUT_FD1_Sc_oB30_for_SC_CAN_V3_2, payload=PT_HUT_FD1, secure-communication-props={auth-info-tx-length=48, data-id=707, freshness-value-length=64, freshness-value-tx-length=16}
      frame HUT_FD2_oB30_for_SC_CAN_V3_2: id 0x203, from HUT, frame-length=64, can-addressing-mode=STANDARD, can-frame-rx-behavior=ANY, can-frame-tx-behavior=CAN-FD
        pdu HUT_FD2_oB30_for_SC_CAN_V3_2: length=64, minimum-delay=0, transmission-mode-false-timing=cyclic-timing=time-period=0.05, transmission-mode-true-timing=cyclic-timing=time-period=0.05, unused-bit-pattern=0
          signal HUT_FD2_0x203_oHUT_FD2_oB30_for_SC_CAN_V3_2: start 0, 512 bit, opaque, i-signal-type=ARRAY, init-value=64 x 0, base-type=uint8_64_none, compu-method=CM_HUT_FD2_0x203, data-constr=DC_HUT_FD2_0x203, transfer-property=PENDING
      frame HUT_FD3_oB30_for_SC_CAN_V3_2: id 0x243, from HUT, frame-length=64, can-addressing-mode=STANDARD, can-frame-rx-behavior=ANY, can-frame-tx-behavior=CAN-FD
        pdu HUT_FD3_oB30_for_SC_CAN_V3_2: length=64, minimum-delay=0, transmission-mode-false-timing=cyclic-timing=time-period=0.05, transmission-mode-true-timing=cyclic-timing=time-period=0.05, unused-bit-pattern=0
          signal HUT_FD3_0x243_oHUT_FD3_oB30_for_SC_CAN_V3_2: start 0, 512 bit, opaque, i-signal-type=ARRAY, init-value=64 x 0, base-type=uint8_64_none, compu-method=CM_HUT_FD3_0x243, data-constr=DC_HUT_FD3_0x243, transfer-property=PENDING
      frame HUT_FD4_oB30_for_SC_CAN_V3_2: id 0x1DA, from HUT, frame-length=64, can-addressing-mode=STANDARD, can-frame-rx-behavior=ANY, can-frame-tx-behavior=CAN-FD
        pdu HUT_FD4_oB30_for_SC_CAN_V3_2: length=64, minimum-delay=0, transmission-mode-false-timing=event-controlled-timing={number-of-repetitions=5, repetition-period=0.05}, transmission-mode-true-timing=event-controlled-timing={number-of-repetitions=5, repetition-period=0.05}, unused-bit-pattern=0
          signal HUT_FD4_0x1DA_oHUT_FD4_oB30_for_SC_CAN_V3_2: start 0, 512 bit, opaque, i-signal-type=ARRAY, init-value=64 x 0, base-type=uint8_64_none, compu-method=CM_HUT_FD4_0x1DA, data-constr=DC_HUT_FD4_0x1DA, transfer-property=TRIGGERED
      frame HUT_FD5_oB30_for_SC_CAN_V3_2: id 0x1DB, from HUT, frame-length=64, can-addressing-mode=STANDARD, can-frame-rx-behavior=ANY, can-frame-tx-behavior=CAN-FD
        pdu HUT_FD5_oB30_for_SC_CAN_V3_2: length=64, minimum-delay=0, transmission-mode-false-timing=event-controlled-timing={number-of-repetitions=5, repetition-period=0.05}, transmission-mode-true-timing=event-controlled-timing={number-of-repetitions=5, repetition-period=0.05}, unused-bit-pattern=0
          signal HUT_FD5_0x1DB_oHUT_FD5_oB30_for_SC_CAN_V3_2: start 0, 512 bit, opaque, i-signal-type=ARRAY, init-value=64 x 0, base-type=uint8_64_none, compu-method=CM_HUT_FD5_0x1DB, data-constr=DC_HUT_FD5_0x1DB, transfer-property=TRIGGERED
      frame HUT_NM_oB30_for_SC_CAN_V3_2: id 0x509, from HUT, frame-length=8, can-addressing-mode=STANDARD, can-frame-rx-behavior=ANY, can-frame-tx-behavior=CAN-20
        nm pdu HUT_NM_oB30_for_SC_CAN_V3_2: length=8, unused-bit-pattern=0
      frame HUT_Phy_Req_oB30_for_SC_CAN_V3_2: id 0x773, to HUT, frame-length=8, can-addressing-mode=STANDARD, can-frame-rx-behavior=CAN-FD, can-frame-tx-behavior=CAN-FD
        n pdu HUT_Phy_Req_Tp_oB30_for_SC_CAN_V3_2: length=8
      frame HUT_Phy_Req_oB30_for_SC_CAN_V3_2_20: id 0x773, to HUT, frame-length=8, can-addressing-mode=STANDARD, can-frame-rx-behavior=CAN-20, can-frame-tx-behavior=CAN-20
        n pdu HUT_Phy_Req_Tp_oB30_for_SC_CAN_V3_2_20: length=8
      frame HUT_Phy_Resp_oB30_for_SC_CAN_V3_2: id 0x7B3, from HUT, frame-length=8, can-addressing-mode=STANDARD, can-frame-rx-behavior=CAN-FD, can-frame-tx-behavior=CAN-FD
        n pdu HUT_Phy_Resp_Tp_oB30_for_SC_CAN_V3_2: length=8
      frame HUT_Phy_Resp_oB30_for_SC_CAN_V3_2_20: id 0x7B3, from HUT, frame-length=8, can-addressing-mode=STANDARD, can-frame-rx-behavior=CAN-20, can-frame-tx-behavior=CAN-20
        n pdu HUT_Phy_Resp_Tp_oB30_for_SC_CAN_V3_2_20: length=8
      frame HUT_Sync_Req_oB30_for_SC_CAN_V3_2: id 0x462, from HUT, frame-length=16, can-addressing-mode=STANDARD, can-frame-rx-behavior=ANY, can-frame-tx-behavior=CAN-FD
        pdu HUT_Sync_Req_oB30_for_SC_CAN_V3_2: length=16, minimum-delay=0, transmission-mode-false-timing=event-controlled-timing={number-of-repetitions=0, repetition-period=0}, transmission-mode-true-timing=event-controlled-timing={number-of-repetitions=0, repetition-period=0}, unused-bit-pattern=0
          signal SyncRequestMessageId_oHUT_Sync_Req_oB30_for_SC_CAN_V3_2: start 7, 8 bit, big-endian, i-signal-type=PRIMITIVE, init-value=0, base-type=uint8, compu-method=CM_SyncRequestMessageId, data-constr=DC_SyncRequestMessageId, transfer-property=TRIGGERED
          signal SyncRequstReseverData_oHUT_Sync_Req_oB30_for_SC_CAN_V3_2: start 8, 56 bit, opaque, i-signal-type=ARRAY, init-value=7 x 0, base-type=uint8_7_none, compu-method=CM_SyncRequstReseverData, data-constr=DC_SyncRequstReseverData, transfer-property=TRIGGERED
      frame HUT1_oB30_for_SC_CAN_V3_2: id 0x367, from HUT, frame-length=8, can-addressing-mode=STANDARD, can-frame-rx-behavior=ANY, can-frame-tx-behavior=CAN-FD
        pdu HUT1_oB30_for_SC_CAN_V3_2: length=8, minimum-delay=0, transmission-mode-false-timing=event-controlled-timing={number-of-repetitions=5, repetition-period=0.06}, transmission-mode-true-timing=event-controlled-timing={number-of-repetitions=5, repetition-period=0.06}, unused-bit-pattern=0
          signal HUT1_0x367_oHUT1_oB30_for_SC_CAN_V3_2: start 0, 64 bit, opaque, i-signal-type=ARRAY, init-value=8 x 0, base-type=uint8_8_none, compu-method=CM_HUT1_0x367, data-constr=DC_HUT1_0x367, transfer-property=TRIGGERED
      frame HUT10_oB30_for_SC_CAN_V3_2: id 0x331, from HUT, frame-length=8, can-addressing-mode=STANDARD, can-frame-rx-behavior=ANY, can-frame-tx-behavior=CAN-FD
        pdu HUT10_oB30_for_SC_CAN_V3_2: length=8, minimum-delay=0, transmission-mode-false-timing=event-controlled-timing={number-of-repetitions=5, repetition-period=0.06}, transmission-mode-true-timing=event-controlled-timing={number-of-repetitions=5, repetition-period=0.06}, unused-bit-pattern=0
          signal HUT10_0x331_oHUT10_oB30_for_SC_CAN_V3_2: start 0, 64 bit, opaque, i-signal-type=ARRAY, init-value=8 x 0, base-type=uint8_8_none, compu-method=CM_HUT10_0x331, data-constr=DC_HUT10_0x331, transfer-property=TRIGGERED
      frame HUT12_oB30_for_SC_CAN_V3_2: id 0x3AF, from HUT, frame-length=8, can-addressing-mode=STANDARD, can-frame-rx-behavior=ANY, can-frame-tx-behavior=CAN-FD
        pdu HUT12_oB30_for_SC_CAN_V3_2: length=8, minimum-delay=0, transmission-mode-false-timing=cyclic-timing=time-period=1, transmission-mode-true-timing=cyclic-timing=time-period=1, unused-bit-pattern=0
          signal HUT12_0x3AF_oHUT12_oB30_for_SC_CAN_V3_2: start 0, 64 bit, opaque, i-signal-type=ARRAY, init-value=8 x 0, base-type=uint8_8_none, compu-method=CM_HUT12_0x3AF, data-constr=DC_HUT12_0x3AF, transfer-property=PENDING
      frame HUT13_oB30_for_SC_CAN_V3_2: id 0x31C, from HUT, frame-length=8, can-addressing-mode=STANDARD, can-frame-rx-behavior=ANY, can-frame-tx-behavior=CAN-FD
        pdu HUT13_oB30_for_SC_CAN_V3_2: length=8, minimum-delay=0, transmission-mode-false-timing=cyclic-timing=time-period=0.1, transmission-mode-true-timing=cyclic-timing=time-period=0.1, unused-bit-pattern=0
          signal HUT13_0x31C_oHUT13_oB30_for_SC_CAN_V3_2: start 0, 64 bit, opaque, i-signal-type=ARRAY, init-value=8 x 0, base-type=uint8_8_none, compu-method=CM_HUT13_0x31C, data-constr=DC_HUT13_0x31C, transfer-property=PENDING
      frame HUT15_oB30_for_SC_CAN_V3_2: id 0x1EE, from HUT, frame-length=16, can-addressing-mode=STANDARD, can-frame-rx-behavior=ANY, can-frame-tx-behavior=CAN-FD
        secured i pdu HUT15_Sc_oB30_for_SC_CAN_V3_2: length=16, authentication-props=AuthHUT15_Sc_oB30_for_SC_CAN_V3_2, freshness-props=FreshnessHUT15_Sc_oB30_for_SC_CAN_V3_2, payload=PT_HUT15, secure-communication-props={auth-info-tx-length=48, data-id=494, freshness-value-length=64, freshness-value-tx-length=16}
      frame HUT16_oB30_for_SC_CAN_V3_2: id 0x348, from HUT, frame-length=8, can-addressing-mode=STANDARD, can-frame-rx-behavior=ANY, can-frame-tx-behavior=CAN-FD
        pdu HUT16_oB30_for_SC_CAN_V3_2: length=8, minimum-delay=0, transmission-mode-false-timing=cyclic-timing=time-period=0.5, transmission-mode-true-timing=cyclic-timing=time-period=0.5, unused-bit-pattern=0
          signal HUT16_0x348_oHUT16_oB30_for_SC_CAN_V3_2: start 0, 64 bit, opaque, i-signal-type=ARRAY, init-value=8 x 0, base-type=uint8_8_none, compu-method=CM_HUT16_0x348, data-constr=DC_HUT16_0x348, transfer-property=PENDING
      frame HUT17_oB30_for_SC_CAN_V3_2: id 0x33B, from HUT, frame-length=8, can-addressing-mode=STANDARD, can-frame-rx-behavior=ANY, can-frame-tx-behavior=CAN-FD
        pdu HUT17_oB30_for_SC_CAN_V3_2: length=8, minimum-delay=0, transmission-mode-false-timing=event-controlled-timing={number-of-repetitions=5, repetition-period=0.05}, transmission-mode-true-timing=event-controlled-timing={number-of-repetitions=5, repetition-period=0.05}, unused-bit-pattern=0
          signal HUT17_0x33B_oHUT17_oB30_for_SC_CAN_V3_2: start 0, 64 bit, opaque, i-signal-type=ARRAY, init-value=8 x 0, base-type=uint8_8_none, compu-method=CM_HUT17_0x33B, data-constr=DC_HUT17_0x33B, transfer-property=TRIGGERED
      frame HUT19_oB30_for_SC_CAN_V3_2: id 0x415, from HUT, frame-length=8, can-addressing-mode=STANDARD, can-frame-rx-behavior=ANY, can-frame-tx-behavior=CAN-FD
        pdu HUT19_oB30_for_SC_CAN_V3_2: length=8, minimum-delay=0, transmission-mode-false-timing=cyclic-timing=time-period=5, transmission-mode-true-timing=cyclic-timing=time-period=5, unused-bit-pattern=0
          signal HUT19_0x415_oHUT19_oB30_for_SC_CAN_V3_2: start 0, 64 bit, opaque, i-signal-type=ARRAY, init-value=8 x 0, base-type=uint8_8_none, compu-method=CM_HUT19_0x415, data-constr=DC_HUT19_0x415, transfer-property=PENDING
      frame HUT2_oB30_for_SC_CAN_V3_2: id 0x369, from HUT, frame-length=8, can-addressing-mode=STANDARD, can-frame-rx-behavior=ANY, can-frame-tx-behavior=CAN-FD
        pdu HUT2_oB30_for_SC_CAN_V3_2: length=8, minimum-delay=0, transmission-mode-false-timing=event-controlled-timing={number-of-repetitions=5, repetition-period=0.06}, transmission-mode-true-timing=event-controlled-timing={number-of-repetitions=5, repetition-period=0.06}, unused-bit-pattern=0
          signal HUT2_0x369_oHUT2_oB30_for_SC_CAN_V3_2: start 0, 64 bit, opaque, i-signal-type=ARRAY, init-value=8 x 0, base-type=uint8_8_none, compu-method=CM_HUT2_0x369, data-constr=DC_HUT2_0x369, transfer-property=TRIGGERED
      frame HUT20_oB30_for_SC_CAN_V3_2: id 0x2DE, from HUT, frame-length=8, can-addressing-mode=STANDARD, can-frame-rx-behavior=ANY, can-frame-tx-behavior=CAN-FD
        pdu HUT20_oB30_for_SC_CAN_V3_2: length=8, minimum-delay=0, transmission-mode-false-timing=event-controlled-timing={number-of-repetitions=5, repetition-period=0.02}, transmission-mode-true-timing=event-controlled-timing={number-of-repetitions=5, repetition-period=0.02}, unused-bit-pattern=0
          signal HUT20_0x2DE_oHUT20_oB30_for_SC_CAN_V3_2: start 0, 64 bit, opaque, i-signal-type=ARRAY, init-value=8 x 0, base-type=uint8_8_none, compu-method=CM_HUT20_0x2DE, data-constr=DC_HUT20_0x2DE, transfer-property=TRIGGERED
      frame HUT21_oB30_for_SC_CAN_V3_2: id 0x2DD, from HUT, frame-length=8, can-addressing-mode=STANDARD, can-frame-rx-behavior=ANY, can-frame-tx-behavior=CAN-FD
        pdu HUT21_oB30_for_SC_CAN_V3_2: length=8, minimum-delay=0, transmission-mode-false-timing=event-controlled-timing={number-of-repetitions=5, repetition-period=0.02}, transmission-mode-true-timing=event-controlled-timing={number-of-repetitions=5, repetition-period=0.02}, unused-bit-pattern=0
          signal HUT21_0x2DD_oHUT21_oB30_for_SC_CAN_V3_2: start 0, 64 bit, opaque, i-signal-type=ARRAY, init-value=8 x 0, base-type=uint8_8_none, compu-method=CM_HUT21_0x2DD, data-constr=DC_HUT21_0x2DD, transfer-property=TRIGGERED
      frame HUT22_oB30_for_SC_CAN_V3_2: id 0x2DA, from HUT, frame-length=8, can-addressing-mode=STANDARD, can-frame-rx-behavior=ANY, can-frame-tx-behavior=CAN-FD
        pdu HUT22_oB30_for_SC_CAN_V3_2: length=8, minimum-delay=0, transmission-mode-false-timing=event-controlled-timing={number-of-repetitions=5, repetition-period=0.02}, transmission-mode-true-timing=event-controlled-timing={number-of-repetitions=5, repetition-period=0.02}, unused-bit-pattern=0
          signal HUT22_0x2DA_oHUT22_oB30_for_SC_CAN_V3_2: start 0, 64 bit, opaque, i-signal-type=ARRAY, init-value=8 x 0, base-type=uint8_8_none, compu-method=CM_HUT22_0x2DA, data-constr=DC_HUT22_0x2DA, transfer-property=TRIGGERED
      frame HUT23_oB30_for_SC_CAN_V3_2: id 0x2D8, from HUT, frame-length=8, can-addressing-mode=STANDARD, can-frame-rx-behavior=ANY, can-frame-tx-behavior=CAN-FD
        pdu HUT23_oB30_for_SC_CAN_V3_2: length=8, minimum-delay=0, transmission-mode-false-timing=event-controlled-timing={number-of-repetitions=5, repetition-period=0.02}, transmission-mode-true-timing=event-controlled-timing={number-of-repetitions=5, repetition-period=0.02}, unused-bit-pattern=0
          signal HUT23_0x2D8_oHUT23_oB30_for_SC_CAN_V3_2: start 0, 64 bit, opaque, i-signal-type=ARRAY, init-value=8 x 0, base-type=uint8_8_none, compu-method=CM_HUT23_0x2D8, data-constr=DC_HUT23_0x2D8, transfer-property=TRIGGERED
      frame HUT25_oB30_for_SC_CAN_V3_2: id 0x339, from HUT, frame-length=8, can-addressing-mode=STANDARD, can-frame-rx-behavior=ANY, can-frame-tx-behavior=CAN-FD
        pdu HUT25_oB30_for_SC_CAN_V3_2: length=8, minimum-delay=0, transmission-mode-false-timing=event-controlled-timing={number-of-repetitions=5, repetition-period=0.05}, transmission-mode-true-timing=event-controlled-timing={number-of-repetitions=5, repetition-period=0.05}, unused-bit-pattern=0
          signal HUT25_0x339_oHUT25_oB30_for_SC_CAN_V3_2: start 0, 64 bit, opaque, i-signal-type=ARRAY, init-value=8 x 0, base-type=uint8_8_none, compu-method=CM_HUT25_0x339, data-constr=DC_HUT25_0x339, transfer-property=TRIGGERED
      frame HUT26_oB30_for_SC_CAN_V3_2: id 0x2B6, from HUT, frame-length=8, can-addressing-mode=STANDARD, can-frame-rx-behavior=ANY, can-frame-tx-behavior=CAN-FD
        pdu HUT26_oB30_for_SC_CAN_V3_2: length=8, minimum-delay=0, transmission-mode-false-timing=cyclic-timing=time-period=0.1, transmission-mode-true-timing=cyclic-timing=time-period=0.1, unused-bit-pattern=0
          signal HUT26_0x2B6_oHUT26_oB30_for_SC_CAN_V3_2: start 0, 64 bit, opaque, i-signal-type=ARRAY, init-value=8 x 0, base-type=uint8_8_none, compu-method=CM_HUT26_0x2B6, data-constr=DC_HUT26_0x2B6, transfer-property=PENDING
      frame HUT27_oB30_for_SC_CAN_V3_2: id 0x2B2, from HUT, frame-length=8, can-addressing-mode=STANDARD, can-frame-rx-behavior=ANY, can-frame-tx-behavior=CAN-FD
        pdu HUT27_oB30_for_SC_CAN_V3_2: length=8, minimum-delay=0, transmission-mode-false-timing=cyclic-timing=time-period=0.1, transmission-mode-true-timing=cyclic-timing=time-period=0.1, unused-bit-pattern=0
          signal HUT27_0x2B2_oHUT27_oB30_for_SC_CAN_V3_2: start 0, 64 bit, opaque, i-signal-type=ARRAY, init-value=8 x 0, base-type=uint8_8_none, compu-method=CM_HUT27_0x2B2, data-constr=DC_HUT27_0x2B2, transfer-property=PENDING
      frame HUT3_oB30_for_SC_CAN_V3_2: id 0x36B, from HUT, frame-length=8, can-addressing-mode=STANDARD, can-frame-rx-behavior=ANY, can-frame-tx-behavior=CAN-FD
        pdu HUT3_oB30_for_SC_CAN_V3_2: length=8, minimum-delay=0, transmission-mode-false-timing=event-controlled-timing={number-of-repetitions=5, repetition-period=0.05}, transmission-mode-true-timing=event-controlled-timing={number-of-repetitions=5, repetition-period=0.05}, unused-bit-pattern=0
          signal HUT3_0x36B_oHUT3_oB30_for_SC_CAN_V3_2: start 0, 64 bit, opaque, i-signal-type=ARRAY, init-value=8 x 0, base-type=uint8_8_none, compu-method=CM_HUT3_0x36B, data-constr=DC_HUT3_0x36B, transfer-property=TRIGGERED
      frame HUT30_oB30_for_SC_CAN_V3_2: id 0x1E9, from HUT, frame-length=8, can-addressing-mode=STANDARD, can-frame-rx-behavior=ANY, can-frame-tx-behavior=CAN-FD
        pdu HUT30_oB30_for_SC_CAN_V3_2: length=8, minimum-delay=0, transmission-mode-false-timing=event-controlled-timing={number-of-repetitions=5, repetition-period=0.05}, transmission-mode-true-timing=event-controlled-timing={number-of-repetitions=5, repetition-period=0.05}, unused-bit-pattern=0
          signal HUT30_0x1E9_oHUT30_oB30_for_SC_CAN_V3_2: start 0, 64 bit, opaque, i-signal-type=ARRAY, init-value=8 x 0, base-type=uint8_8_none, compu-method=CM_HUT30_0x1E9, data-constr=DC_HUT30_0x1E9, transfer-property=TRIGGERED
      frame HUT31_oB30_for_SC_CAN_V3_2: id 0x30C, from HUT, frame-length=8, can-addressing-mode=STANDARD, can-frame-rx-behavior=ANY, can-frame-tx-behavior=CAN-FD
        pdu HUT31_oB30_for_SC_CAN_V3_2: length=8, minimum-delay=0, transmission-mode-false-timing=cyclic-timing=time-period=0.2, transmission-mode-true-timing=cyclic-timing=time-period=0.2, unused-bit-pattern=0
          signal HUT31_0x30C_oHUT31_oB30_for_SC_CAN_V3_2: start 0, 64 bit, opaque, i-signal-type=ARRAY, init-value=8 x 0, base-type=uint8_8_none, compu-method=CM_HUT31_0x30C, data-constr=DC_HUT31_0x30C, transfer-property=PENDING
      frame HUT32_oB30_for_SC_CAN_V3_2: id 0x26F, from HUT, frame-length=8, can-addressing-mode=STANDARD, can-frame-rx-behavior=ANY, can-frame-tx-behavior=CAN-FD
        pdu HUT32_oB30_for_SC_CAN_V3_2: length=8, minimum-delay=0, transmission-mode-false-timing=cyclic-timing=time-period=0.05, transmission-mode-true-timing=cyclic-timing=time-period=0.05, unused-bit-pattern=0
          signal HUT32_0x26F_oHUT32_oB30_for_SC_CAN_V3_2: start 0, 64 bit, opaque, i-signal-type=ARRAY, init-value=8 x 0, base-type=uint8_8_none, compu-method=CM_HUT32_0x26F, data-constr=DC_HUT32_0x26F, transfer-property=PENDING
      frame HUT33_oB30_for_SC_CAN_V3_2: id 0x1ED, from HUT, frame-length=8, can-addressing-mode=STANDARD, can-frame-rx-behavior=ANY, can-frame-tx-behavior=CAN-FD
        pdu HUT33_oB30_for_SC_CAN_V3_2: length=8, minimum-delay=0, transmission-mode-false-timing=event-controlled-timing={number-of-repetitions=6, repetition-period=0.05}, transmission-mode-true-timing=event-controlled-timing={number-of-repetitions=6, repetition-period=0.05}, unused-bit-pattern=0
          signal HUT33_0x1ED_oHUT33_oB30_for_SC_CAN_V3_2: start 0, 64 bit, opaque, i-signal-type=ARRAY, init-value=8 x 0, base-type=uint8_8_none, compu-method=CM_HUT33_0x1ED, data-constr=DC_HUT33_0x1ED, transfer-property=TRIGGERED
      frame HUT34_oB30_for_SC_CAN_V3_2: id 0x370, from HUT, frame-length=8, can-addressing-mode=STANDARD, can-frame-rx-behavior=ANY, can-frame-tx-behavior=CAN-FD
        pdu HUT34_oB30_for_SC_CAN_V3_2: length=8, minimum-delay=0, transmission-mode-false-timing=cyclic-timing=time-period=1, transmission-mode-true-timing=cyclic-timing=time-period=1, unused-bit-pattern=0
          signal HUT34_0x370_oHUT34_oB30_for_SC_CAN_V3_2: start 0, 64 bit, opaque, i-signal-type=ARRAY, init-value=8 x 0, base-type=uint8_8_none, compu-method=CM_HUT34_0x370, data-constr=DC_HUT34_0x370, transfer-property=PENDING
      frame HUT35_oB30_for_SC_CAN_V3_2: id 0x1E5, from HUT, frame-length=8, can-addressing-mode=STANDARD, can-frame-rx-behavior=ANY, can-frame-tx-behavior=CAN-FD
        pdu HUT35_oB30_for_SC_CAN_V3_2: length=8, minimum-delay=0, transmission-mode-false-timing=event-controlled-timing={number-of-repetitions=5, repetition-period=0.05}, transmission-mode-true-timing=event-controlled-timing={number-of-repetitions=5, repetition-period=0.05}, unused-bit-pattern=0
          signal HUT35_0x1E5_oHUT35_oB30_for_SC_CAN_V3_2: start 0, 64 bit, opaque, i-signal-type=ARRAY, init-value=8 x 0, base-type=uint8_8_none, compu-method=CM_HUT35_0x1E5, data-constr=DC_HUT35_0x1E5, transfer-property=TRIGGERED
      frame HUT36_oB30_for_SC_CAN_V3_2: id 0x1E6, from HUT, frame-length=8, can-addressing-mode=STANDARD, can-frame-rx-behavior=ANY, can-frame-tx-behavior=CAN-FD
        pdu HUT36_oB30_for_SC_CAN_V3_2: length=8, minimum-delay=0, transmission-mode-false-timing=event-controlled-timing={number-of-repetitions=5, repetition-period=0.05}, transmission-mode-true-timing=event-controlled-timing={number-of-repetitions=5, repetition-period=0.05}, unused-bit-pattern=0
          signal HUT36_0x1E6_oHUT36_oB30_for_SC_CAN_V3_2: start 0, 64 bit, opaque, i-signal-type=ARRAY, init-value=8 x 0, base-type=uint8_8_none, compu-method=CM_HUT36_0x1E6, data-constr=DC_HUT36_0x1E6, transfer-property=TRIGGERED
      frame HUT37_oB30_for_SC_CAN_V3_2: id 0x1EC, from HUT, frame-length=8, can-addressing-mode=STANDARD, can-frame-rx-behavior=ANY, can-frame-tx-behavior=CAN-FD
        pdu HUT37_oB30_for_SC_CAN_V3_2: length=8, minimum-delay=0, transmission-mode-false-timing=event-controlled-timing={number-of-repetitions=5, repetition-period=0.05}, transmission-mode-true-timing=event-controlled-timing={number-of-repetitions=5, repetition-period=0.05}, unused-bit-pattern=0
          signal HUT37_0x1EC_oHUT37_oB30_for_SC_CAN_V3_2: start 0, 64 bit, opaque, i-signal-type=ARRAY, init-value=8 x 0, base-type=uint8_8_none, compu-method=CM_HUT37_0x1EC, data-constr=DC_HUT37_0x1EC, transfer-property=TRIGGERED
      frame HUT38_oB30_for_SC_CAN_V3_2: id 0x1E7, from HUT, frame-length=8, can-addressing-mode=STANDARD, can-frame-rx-behavior=ANY, can-frame-tx-behavior=CAN-FD
        pdu HUT38_oB30_for_SC_CAN_V3_2: length=8, minimum-delay=0, transmission-mode-false-timing=event-controlled-timing={number-of-repetitions=5, repetition-period=0.05}, transmission-mode-true-timing=event-controlled-timing={number-of-repetitions=5, repetition-period=0.05}, unused-bit-pattern=0
          signal HUT38_0x1E7_oHUT38_oB30_for_SC_CAN_V3_2: start 0, 64 bit, opaque, i-signal-type=ARRAY, init-value=8 x 0, base-type=uint8_8_none, compu-method=CM_HUT38_0x1E7, data-constr=DC_HUT38_0x1E7, transfer-property=TRIGGERED
      frame HUT39_oB30_for_SC_CAN_V3_2: id 0x1EB, from HUT, frame-length=8, can-addressing-mode=STANDARD, can-frame-rx-behavior=ANY, can-frame-tx-behavior=CAN-FD
        pdu HUT39_oB30_for_SC_CAN_V3_2: length=8, minimum-delay=0, transmission-mode-false-timing=event-controlled-timing={number-of-repetitions=5, repetition-period=0.05}, transmission-mode-true-timing=event-controlled-timing={number-of-repetitions=5, repetition-period=0.05}, unused-bit-pattern=0
          signal HUT39_0x1EB_oHUT39_oB30_for_SC_CAN_V3_2: start 0, 64 bit, opaque, i-signal-type=ARRAY, init-value=8 x 0, base-type=uint8_8_none, compu-method=CM_HUT39_0x1EB, data-constr=DC_HUT39_0x1EB, transfer-property=TRIGGERED
      frame HUT4_oB30_for_SC_CAN_V3_2: id 0x36D, from HUT, frame-length=8, can-addressing-mode=STANDARD, can-frame-rx-behavior=ANY, can-frame-tx-behavior=CAN-FD
        pdu HUT4_oB30_for_SC_CAN_V3_2: length=8, minimum-delay=0, transmission-mode-false-timing=event-controlled-timing={number-of-repetitions=5, repetition-period=0.05}, transmission-mode-true-timing=event-controlled-timing={number-of-repetitions=5, repetition-period=0.05}, unused-bit-pattern=0
          signal HUT4_0x36D_oHUT4_oB30_for_SC_CAN_V3_2: start 0, 64 bit, opaque, i-signal-type=ARRAY, init-value=8 x 0, base-type=uint8_8_none, compu-method=CM_HUT4_0x36D, data-constr=DC_HUT4_0x36D, transfer-property=TRIGGERED
      frame HUT40_oB30_for_SC_CAN_V3_2: id 0x224, from HUT, frame-length=8, can-addressing-mode=STANDARD, can-frame-rx-behavior=ANY, can-frame-tx-behavior=CAN-FD
        pdu HUT40_oB30_for_SC_CAN_V3_2: length=8, minimum-delay=0, transmission-mode-false-timing=cyclic-timing=time-period=0.05, transmission-mode-true-timing=cyclic-timing=time-period=0.05, unused-bit-pattern=0
          signal HUT40_0x224_oHUT40_oB30_for_SC_CAN_V3_2: start 0, 64 bit, opaque, i-signal-type=ARRAY, init-value=8 x 0, base-type=uint8_8_none, compu-method=CM_HUT40_0x224, data-constr=DC_HUT40_0x224, transfer-property=PENDING
      frame HUT41_oB30_for_SC_CAN_V3_2: id 0x1FB, from HUT, frame-length=8, can-addressing-mode=STANDARD, can-frame-rx-behavior=ANY, can-frame-tx-behavior=CAN-FD
        pdu HUT41_oB30_for_SC_CAN_V3_2: length=8, minimum-delay=0, transmission-mode-false-timing=event-controlled-timing={number-of-repetitions=5, repetition-period=0.05}, transmission-mode-true-timing=event-controlled-timing={number-of-repetitions=5, repetition-period=0.05}, unused-bit-pattern=0
          signal HUT41_0x1FB_oHUT41_oB30_for_SC_CAN_V3_2: start 0, 64 bit, opaque, i-signal-type=ARRAY, init-value=8 x 0, base-type=uint8_8_none, compu-method=CM_HUT41_0x1FB, data-constr=DC_HUT41_0x1FB, transfer-property=TRIGGERED
      frame HUT42_oB30_for_SC_CAN_V3_2: id 0x1F9, from HUT, frame-length=8, can-addressing-mode=STANDARD, can-frame-rx-behavior=ANY, can-frame-tx-behavior=CAN-FD
        pdu HUT42_oB30_for_SC_CAN_V3_2: length=8, minimum-delay=0, transmission-mode-false-timing=event-controlled-timing={number-of-repetitions=5, repetition-period=0.05}, transmission-mode-true-timing=event-controlled-timing={number-of-repetitions=5, repetition-period=0.05}, unused-bit-pattern=0
          signal HUT42_0x1F9_oHUT42_oB30_for_SC_CAN_V3_2: start 0, 64 bit, opaque, i-signal-type=ARRAY, init-value=8 x 0, base-type=uint8_8_none, compu-method=CM_HUT42_0x1F9, data-constr=DC_HUT42_0x1F9, transfer-property=TRIGGERED
      frame HUT43_oB30_for_SC_CAN_V3_2: id 0x1FD, from HUT, frame-length=8, can-addressing-mode=STANDARD, can-frame-rx-behavior=ANY, can-frame-tx-behavior=CAN-FD
        pdu HUT43_oB30_for_SC_CAN_V3_2: length=8, minimum-delay=0, transmission-mode-false-timing=event-controlled-timing={number-of-repetitions=5, repetition-period=0.05}, transmission-mode-true-timing=event-controlled-timing={number-of-repetitions=5, repetition-period=0.05}, unused-bit-pattern=0
          signal HUT43_0x1FD_oHUT43_oB30_for_SC_CAN_V3_2: start 0, 64 bit, opaque, i-signal-type=ARRAY, init-value=8 x 0, base-type=uint8_8_none, compu-method=CM_HUT43_0x1FD, data-constr=DC_HUT43_0x1FD, transfer-property=TRIGGERED
      frame HUT45_oB30_for_SC_CAN_V3_2: id 0x1DC, from HUT, frame-length=8, can-addressing-mode=STANDARD, can-frame-rx-behavior=ANY, can-frame-tx-behavior=CAN-FD
        pdu HUT45_oB30_for_SC_CAN_V3_2: length=8, minimum-delay=0, transmission-mode-false-timing=event-controlled-timing={number-of-repetitions=5, repetition-period=0.05}, transmission-mode-true-timing=event-controlled-timing={number-of-repetitions=5, repetition-period=0.05}, unused-bit-pattern=0
          signal HUT45_0x1DC_oHUT45_oB30_for_SC_CAN_V3_2: start 0, 64 bit, opaque, i-signal-type=ARRAY, init-value=8 x 0, base-type=uint8_8_none, compu-method=CM_HUT45_0x1DC, data-constr=DC_HUT45_0x1DC, transfer-property=TRIGGERED
      frame HUT46_oB30_for_SC_CAN_V3_2: id 0x1DD, from HUT, frame-length=8, can-addressing-mode=STANDARD, can-frame-rx-behavior=ANY, can-frame-tx-behavior=CAN-FD
        pdu HUT46_oB30_for_SC_CAN_V3_2: length=8, minimum-delay=0, transmission-mode-false-timing=event-controlled-timing={number-of-repetitions=5, repetition-period=0.05}, transmission-mode-true-timing=event-controlled-timing={number-of-repetitions=5, repetition-period=0.05}, unused-bit-pattern=0
          signal HUT46_0x1DD_oHUT46_oB30_for_SC_CAN_V3_2: start 0, 64 bit, opaque, i-signal-type=ARRAY, init-value=8 x 0, base-type=uint8_8_none, compu-method=CM_HUT46_0x1DD, data-constr=DC_HUT46_0x1DD, transfer-property=TRIGGERED
      frame HUT49_oB30_for_SC_CAN_V3_2: id 0x1D1, from HUT, frame-length=8, can-addressing-mode=STANDARD, can-frame-rx-behavior=ANY, can-frame-tx-behavior=CAN-FD
        pdu HUT49_oB30_for_SC_CAN_V3_2: length=8, minimum-delay=0, transmission-mode-false-timing=event-controlled-timing={number-of-repetitions=5, repetition-period=0.05}, transmission-mode-true-timing=event-controlled-timing={number-of-repetitions=5, repetition-period=0.05}, unused-bit-pattern=0
          signal HUT49_0x1D1_oHUT49_oB30_for_SC_CAN_V3_2: start 0, 64 bit, opaque, i-signal-type=ARRAY, init-value=8 x 0, base-type=uint8_8_none, compu-method=CM_HUT49_0x1D1, data-constr=DC_HUT49_0x1D1, transfer-property=TRIGGERED
      frame HUT6_oB30_for_SC_CAN_V3_2: id 0x4A, from HUT, frame-length=8, can-addressing-mode=STANDARD, can-frame-rx-behavior=ANY, can-frame-tx-behavior=CAN-FD
        pdu HUT6_oB30_for_SC_CAN_V3_2: length=8, minimum-delay=0, transmission-mode-false-timing=event-controlled-timing={number-of-repetitions=5, repetition-period=0.05}, transmission-mode-true-timing=event-controlled-timing={number-of-repetitions=5, repetition-period=0.05}, unused-bit-pattern=0
          signal HUT6_0x4A_oHUT6_oB30_for_SC_CAN_V3_2: start 0, 64 bit, opaque, i-signal-type=ARRAY, init-value=8 x 0, base-type=uint8_8_none, compu-method=CM_HUT6_0x4A, data-constr=DC_HUT6_0x4A, transfer-property=TRIGGERED
      frame HUT7_oB30_for_SC_CAN_V3_2: id 0x44, from HUT, frame-length=8, can-addressing-mode=STANDARD, can-frame-rx-behavior=ANY, can-frame-tx-behavior=CAN-FD
        pdu HUT7_oB30_for_SC_CAN_V3_2: length=8, minimum-delay=0, transmission-mode-false-timing=event-controlled-timing={number-of-repetitions=5, repetition-period=0.05}, transmission-mode-true-timing=event-controlled-timing={number-of-repetitions=5, repetition-period=0.05}, unused-bit-pattern=0
          signal HUT7_0x44_oHUT7_oB30_for_SC_CAN_V3_2: start 0, 64 bit, opaque, i-signal-type=ARRAY, init-value=8 x 0, base-type=uint8_8_none, compu-method=CM_HUT7_0x44, data-constr=DC_HUT7_0x44, transfer-property=TRIGGERED
      frame Ibooster_FD2_oB30_for_SC_CAN_V3_2: id 0x120, to HUT, frame-length=64, can-addressing-mode=STANDARD, can-frame-rx-behavior=ANY, can-frame-tx-behavior=CAN-FD
        pdu Ibooster_FD2_oB30_for_SC_CAN_V3_2: length=64, minimum-delay=0, transmission-mode-false-timing=cyclic-timing=time-period=0.02, transmission-mode-true-timing=cyclic-timing=time-period=0.02, unused-bit-pattern=0
          signal Ibooster_FD2_0x120_oIbooster_FD2_oB30_for_SC_CAN_V3_2: start 0, 512 bit, opaque, i-signal-type=ARRAY, init-value=64 x 0, base-type=uint8_64_none, compu-method=CM_Ibooster_FD2_0x120, data-constr=DC_Ibooster_FD2_0x120, transfer-property=PENDING, to HUT
      frame IFC_FD2_oB30_for_SC_CAN_V3_2: id 0x23D, to HUT, frame-length=64, can-addressing-mode=STANDARD, can-frame-rx-behavior=ANY, can-frame-tx-behavior=CAN-FD
        secured i pdu IFC_FD2_Sc_oB30_for_SC_CAN_V3_2: length=64, authentication-props=AuthIFC_FD2_Sc_oB30_for_SC_CAN_V3_2, freshness-props=FreshnessIFC_FD2_Sc_oB30_for_SC_CAN_V3_2, payload=PT_IFC_FD2, secure-communication-props={auth-info-tx-length=48, data-id=573, freshness-value-length=64, freshness-value-tx-length=16}
      frame IFC_FD3_oB30_for_SC_CAN_V3_2: id 0x2CF, to HUT, frame-length=64, can-addressing-mode=STANDARD, can-frame-rx-behavior=ANY, can-frame-tx-behavior=CAN-FD
        pdu IFC_FD3_oB30_for_SC_CAN_V3_2: length=64, minimum-delay=0, transmission-mode-false-timing=cyclic-timing=time-period=0.1, transmission-mode-true-timing=cyclic-timing=time-period=0.1, unused-bit-pattern=0
          signal IFC_FD3_0x2CF_oIFC_FD3_oB30_for_SC_CAN_V3_2: start 0, 512 bit, opaque, i-signal-type=ARRAY, init-value=64 x 0, base-type=uint8_64_none, compu-method=CM_IFC_FD3_0x2CF, data-constr=DC_IFC_FD3_0x2CF, transfer-property=PENDING, to HUT
      frame IFC_FD5_oB30_for_SC_CAN_V3_2: id 0x19F, to HUT, frame-length=64, can-addressing-mode=STANDARD, can-frame-rx-behavior=ANY, can-frame-tx-behavior=CAN-FD
        pdu IFC_FD5_oB30_for_SC_CAN_V3_2: length=64, minimum-delay=0, transmission-mode-false-timing=cyclic-timing=time-period=0.05, transmission-mode-true-timing=cyclic-timing=time-period=0.05, unused-bit-pattern=0
          signal IFC_FD5_0x19F_oIFC_FD5_oB30_for_SC_CAN_V3_2: start 0, 512 bit, opaque, i-signal-type=ARRAY, init-value=64 x 0, base-type=uint8_64_none, compu-method=CM_IFC_FD5_0x19F, data-constr=DC_IFC_FD5_0x19F, transfer-property=PENDING, to HUT
      frame IFC_FD6_oB30_for_SC_CAN_V3_2: id 0x222, to HUT, frame-length=64, can-addressing-mode=STANDARD, can-frame-rx-behavior=ANY, can-frame-tx-behavior=CAN-FD
        pdu IFC_FD6_oB30_for_SC_CAN_V3_2: length=64, minimum-delay=0, transmission-mode-false-timing=cyclic-timing=time-period=0.05, transmission-mode-true-timing=cyclic-timing=time-period=0.05, unused-bit-pattern=0
          signal IFC_FD6_0x222_oIFC_FD6_oB30_for_SC_CAN_V3_2: start 0, 512 bit, opaque, i-signal-type=ARRAY, init-value=64 x 0, base-type=uint8_64_none, compu-method=CM_IFC_FD6_0x222, data-constr=DC_IFC_FD6_0x222, transfer-property=PENDING, to HUT
      frame IFC1_oB30_for_SC_CAN_V3_2: id 0x109, to HUT, frame-length=8, can-addressing-mode=STANDARD, can-frame-rx-behavior=ANY, can-frame-tx-behavior=CAN-FD
        pdu IFC1_oB30_for_SC_CAN_V3_2: length=8, minimum-delay=0, transmission-mode-false-timing=cyclic-timing=time-period=0.02, transmission-mode-true-timing=cyclic-timing=time-period=0.02, unused-bit-pattern=0
          signal IFC1_0x109_oIFC1_oB30_for_SC_CAN_V3_2: start 0, 64 bit, opaque, i-signal-type=ARRAY, init-value=8 x 0, base-type=uint8_8_none, compu-method=CM_IFC1_0x109, data-constr=DC_IFC1_0x109, transfer-property=PENDING, to HUT
      frame IP1_oB30_for_SC_CAN_V3_2: id 0x293, from HUT, frame-length=8, can-addressing-mode=STANDARD, can-frame-rx-behavior=ANY, can-frame-tx-behavior=CAN-FD
        pdu IP1_oB30_for_SC_CAN_V3_2: length=8, minimum-delay=0, transmission-mode-false-timing=cyclic-timing=time-period=0.1, transmission-mode-true-timing=cyclic-timing=time-period=0.1, unused-bit-pattern=0
          signal IP1_0x293_oIP1_oB30_for_SC_CAN_V3_2: start 0, 64 bit, opaque, i-signal-type=ARRAY, init-value=8 x 0, base-type=uint8_8_none, compu-method=CM_IP1_0x293, data-constr=DC_IP1_0x293, transfer-property=PENDING
      frame IP2_oB30_for_SC_CAN_V3_2: id 0x27F, from HUT, frame-length=16, can-addressing-mode=STANDARD, can-frame-rx-behavior=ANY, can-frame-tx-behavior=CAN-FD
        secured i pdu IP2_Sc_oB30_for_SC_CAN_V3_2: length=16, authentication-props=AuthIP2_Sc_oB30_for_SC_CAN_V3_2, freshness-props=FreshnessIP2_Sc_oB30_for_SC_CAN_V3_2, payload=PT_IP2, secure-communication-props={auth-info-tx-length=48, data-id=639, freshness-value-length=64, freshness-value-tx-length=16}
      frame IP3_oB30_for_SC_CAN_V3_2: id 0x34A, from HUT, frame-length=16, can-addressing-mode=STANDARD, can-frame-rx-behavior=ANY, can-frame-tx-behavior=CAN-FD
        pdu IP3_oB30_for_SC_CAN_V3_2: length=16, minimum-delay=0, transmission-mode-false-timing=cyclic-timing=time-period=0.5, transmission-mode-true-timing=cyclic-timing=time-period=0.5, unused-bit-pattern=0
          signal IP3_0x34A_oIP3_oB30_for_SC_CAN_V3_2: start 0, 128 bit, opaque, i-signal-type=ARRAY, init-value=16 x 0, base-type=uint8_16_none, compu-method=CM_IP3_0x34A, data-constr=DC_IP3_0x34A, transfer-property=PENDING
      frame OBC1_oB30_for_SC_CAN_V3_2: id 0x316, to HUT, frame-length=8, can-addressing-mode=STANDARD, can-frame-rx-behavior=ANY, can-frame-tx-behavior=CAN-FD
        pdu OBC1_oB30_for_SC_CAN_V3_2: length=8, minimum-delay=0, transmission-mode-false-timing=cyclic-timing=time-period=0.2, transmission-mode-true-timing=cyclic-timing=time-period=0.2, unused-bit-pattern=0
          signal OBC1_0x316_oOBC1_oB30_for_SC_CAN_V3_2: start 0, 64 bit, opaque, i-signal-type=ARRAY, init-value=8 x 0, base-type=uint8_8_none, compu-method=CM_OBC1_0x316, data-constr=DC_OBC1_0x316, transfer-property=PENDING, to HUT
      frame OBC2_oB30_for_SC_CAN_V3_2: id 0x317, to HUT, frame-length=8, can-addressing-mode=STANDARD, can-frame-rx-behavior=ANY, can-frame-tx-behavior=CAN-FD
        pdu OBC2_oB30_for_SC_CAN_V3_2: length=8, minimum-delay=0, transmission-mode-false-timing=cyclic-timing=time-period=0.2, transmission-mode-true-timing=cyclic-timing=time-period=0.2, unused-bit-pattern=0
          signal OBC2_0x317_oOBC2_oB30_for_SC_CAN_V3_2: start 0, 64 bit, opaque, i-signal-type=ARRAY, init-value=8 x 0, base-type=uint8_8_none, compu-method=CM_OBC2_0x317, data-constr=DC_OBC2_0x317, transfer-property=PENDING, to HUT
      frame P2M1_oB30_for_SC_CAN_V3_2: id 0xAC, to HUT, frame-length=8, can-addressing-mode=STANDARD, can-frame-rx-behavior=ANY, can-frame-tx-behavior=CAN-FD
        pdu P2M1_oB30_for_SC_CAN_V3_2: length=8, minimum-delay=0, transmission-mode-false-timing=cyclic-timing=time-period=0.01, transmission-mode-true-timing=cyclic-timing=time-period=0.01, unused-bit-pattern=0
          signal P2M1_0xAC_oP2M1_oB30_for_SC_CAN_V3_2: start 0, 64 bit, opaque, i-signal-type=ARRAY, init-value=8 x 0, base-type=uint8_8_none, compu-method=CM_P2M1_0xAC, data-constr=DC_P2M1_0xAC, transfer-property=PENDING, to HUT
      frame P2M3_oB30_for_SC_CAN_V3_2: id 0xBE, to HUT, frame-length=8, can-addressing-mode=STANDARD, can-frame-rx-behavior=ANY, can-frame-tx-behavior=CAN-FD
        pdu P2M3_oB30_for_SC_CAN_V3_2: length=8, minimum-delay=0, transmission-mode-false-timing=cyclic-timing=time-period=0.01, transmission-mode-true-timing=cyclic-timing=time-period=0.01, unused-bit-pattern=0
          signal P2M3_0xBE_oP2M3_oB30_for_SC_CAN_V3_2: start 0, 64 bit, opaque, i-signal-type=ARRAY, init-value=8 x 0, base-type=uint8_8_none, compu-method=CM_P2M3_0xBE, data-constr=DC_P2M3_0xBE, transfer-property=PENDING, to HUT
      frame PDCM1_oB30_for_SC_CAN_V3_2: id 0x2CD, to HUT, frame-length=8, can-addressing-mode=STANDARD, can-frame-rx-behavior=ANY, can-frame-tx-behavior=CAN-FD
        pdu PDCM1_oB30_for_SC_CAN_V3_2: length=8, minimum-delay=0, transmission-mode-false-timing=cyclic-timing=time-period=0.1, transmission-mode-true-timing=cyclic-timing=time-period=0.1, unused-bit-pattern=0
          signal PDCM1_0x2CD_oPDCM1_oB30_for_SC_CAN_V3_2: start 0, 64 bit, opaque, i-signal-type=ARRAY, init-value=8 x 0, base-type=uint8_8_none, compu-method=CM_PDCM1_0x2CD, data-constr=DC_PDCM1_0x2CD, transfer-property=PENDING, to HUT
      frame PEPS2_oB30_for_SC_CAN_V3_2: id 0x295, to HUT, frame-length=8, can-addressing-mode=STANDARD, can-frame-rx-behavior=ANY, can-frame-tx-behavior=CAN-FD
        pdu PEPS2_oB30_for_SC_CAN_V3_2: length=8, minimum-delay=0, transmission-mode-false-timing=cyclic-timing=time-period=0.05, transmission-mode-true-timing=cyclic-timing=time-period=0.05, unused-bit-pattern=0
          signal PEPS2_0x295_oPEPS2_oB30_for_SC_CAN_V3_2: start 0, 64 bit, opaque, i-signal-type=ARRAY, init-value=8 x 0, base-type=uint8_8_none, compu-method=CM_PEPS2_0x295, data-constr=DC_PEPS2_0x295, transfer-property=PENDING, to HUT
      frame PEPS4_oB30_for_SC_CAN_V3_2: id 0x302, to HUT, frame-length=8, can-addressing-mode=STANDARD, can-frame-rx-behavior=ANY, can-frame-tx-behavior=CAN-FD
        pdu PEPS4_oB30_for_SC_CAN_V3_2: length=8, minimum-delay=0, transmission-mode-false-timing=cyclic-timing=time-period=0.2, transmission-mode-true-timing=cyclic-timing=time-period=0.2, unused-bit-pattern=0
          signal PEPS4_0x302_oPEPS4_oB30_for_SC_CAN_V3_2: start 0, 64 bit, opaque, i-signal-type=ARRAY, init-value=8 x 0, base-type=uint8_8_none, compu-method=CM_PEPS4_0x302, data-constr=DC_PEPS4_0x302, transfer-property=PENDING, to HUT
      frame R_PBOX1_oB30_for_SC_CAN_V3_2: id 0x19C, to HUT, frame-length=16, can-addressing-mode=STANDARD, can-frame-rx-behavior=ANY, can-frame-tx-behavior=CAN-FD
        secured i pdu R_PBOX1_Sc_oB30_for_SC_CAN_V3_2: length=16, authentication-props=AuthR_PBOX1_Sc_oB30_for_SC_CAN_V3_2, freshness-props=FreshnessR_PBOX1_Sc_oB30_for_SC_CAN_V3_2, payload=PT_R_PBOX1, secure-communication-props={auth-info-tx-length=48, data-id=412, freshness-value-length=64, freshness-value-tx-length=16}
      frame RFCM_L1_oB30_for_SC_CAN_V3_2: id 0x332, to HUT, frame-length=8, can-addressing-mode=STANDARD, can-frame-rx-behavior=ANY, can-frame-tx-behavior=CAN-FD
        pdu RFCM_L1_oB30_for_SC_CAN_V3_2: length=8, minimum-delay=0, transmission-mode-false-timing=cyclic-timing=time-period=0.2, transmission-mode-true-timing=cyclic-timing=time-period=0.2, unused-bit-pattern=0
          signal RFCM_L1_0x332_oRFCM_L1_oB30_for_SC_CAN_V3_2: start 0, 64 bit, opaque, i-signal-type=ARRAY, init-value=8 x 0, base-type=uint8_8_none, compu-method=CM_RFCM_L1_0x332, data-constr=DC_RFCM_L1_0x332, transfer-property=PENDING, to HUT
      frame RFCM_R1_oB30_for_SC_CAN_V3_2: id 0x333, to HUT, frame-length=8, can-addressing-mode=STANDARD, can-frame-rx-behavior=ANY, can-frame-tx-behavior=CAN-FD
        pdu RFCM_R1_oB30_for_SC_CAN_V3_2: length=8, minimum-delay=0, transmission-mode-false-timing=cyclic-timing=time-period=0.2, transmission-mode-true-timing=cyclic-timing=time-period=0.2, unused-bit-pattern=0
          signal RFCM_R1_0x333_oRFCM_R1_oB30_for_SC_CAN_V3_2: start 0, 64 bit, opaque, i-signal-type=ARRAY, init-value=8 x 0, base-type=uint8_8_none, compu-method=CM_RFCM_R1_0x333, data-constr=DC_RFCM_R1_0x333, transfer-property=PENDING, to HUT
      frame RSDS_FD1_oB30_for_SC_CAN_V3_2: id 0x16F, to HUT, frame-length=64, can-addressing-mode=STANDARD, can-frame-rx-behavior=ANY, can-frame-tx-behavior=CAN-FD
        pdu RSDS_FD1_oB30_for_SC_CAN_V3_2: length=64, minimum-delay=0, transmission-mode-false-timing=cyclic-timing=time-period=0.02, transmission-mode-true-timing=cyclic-timing=time-period=0.02, unused-bit-pattern=0
          signal RSDS_FD1_0x16F_oRSDS_FD1_oB30_for_SC_CAN_V3_2: start 0, 512 bit, opaque, i-signal-type=ARRAY, init-value=64 x 0, base-type=uint8_64_none, compu-method=CM_RSDS_FD1_0x16F, data-constr=DC_RSDS_FD1_0x16F, transfer-property=PENDING, to HUT
      frame RSDS_FD2_oB30_for_SC_CAN_V3_2: id 0x30A, to HUT, frame-length=64, can-addressing-mode=STANDARD, can-frame-rx-behavior=ANY, can-frame-tx-behavior=CAN-FD
        pdu RSDS_FD2_oB30_for_SC_CAN_V3_2: length=64, minimum-delay=0, transmission-mode-false-timing=cyclic-timing=time-period=0.2, transmission-mode-true-timing=cyclic-timing=time-period=0.2, unused-bit-pattern=0
          signal RSDS_FD2_0x30A_oRSDS_FD2_oB30_for_SC_CAN_V3_2: start 0, 512 bit, opaque, i-signal-type=ARRAY, init-value=64 x 0, base-type=uint8_64_none, compu-method=CM_RSDS_FD2_0x30A, data-constr=DC_RSDS_FD2_0x30A, transfer-property=PENDING, to HUT
      frame SCM1_oB30_for_SC_CAN_V3_2: id 0x2D1, to HUT, frame-length=8, can-addressing-mode=STANDARD, can-frame-rx-behavior=ANY, can-frame-tx-behavior=CAN-FD
        pdu SCM1_oB30_for_SC_CAN_V3_2: length=8, minimum-delay=0, transmission-mode-false-timing=cyclic-timing=time-period=0.1, transmission-mode-true-timing=cyclic-timing=time-period=0.1, unused-bit-pattern=0
          signal SCM1_0x2D1_oSCM1_oB30_for_SC_CAN_V3_2: start 0, 64 bit, opaque, i-signal-type=ARRAY, init-value=8 x 0, base-type=uint8_8_none, compu-method=CM_SCM1_0x2D1, data-constr=DC_SCM1_0x2D1, transfer-property=PENDING, to HUT
      frame T_BOX_FD1_oB30_for_SC_CAN_V3_2: id 0x33, to HUT, frame-length=16, can-addressing-mode=STANDARD, can-frame-rx-behavior=ANY, can-frame-tx-behavior=CAN-FD
        secured i pdu T_BOX_FD1_Sc_oB30_for_SC_CAN_V3_2: length=16, authentication-props=AuthT_BOX_FD1_Sc_oB30_for_SC_CAN_V3_2, freshness-props=FreshnessT_BOX_FD1_Sc_oB30_for_SC_CAN_V3_2, payload=PT_T_BOX_FD1, secure-communication-props={auth-info-tx-length=48, data-id=51, freshness-value-length=64, freshness-value-tx-length=16}
      frame T_BOX_FD10_oB30_for_SC_CAN_V3_2: id 0x2F0, to HUT, frame-length=64, can-addressing-mode=STANDARD, can-frame-rx-behavior=ANY, can-frame-tx-behavior=CAN-FD
        pdu T_BOX_FD10_oB30_for_SC_CAN_V3_2: length=64, minimum-delay=0, transmission-mode-false-timing=cyclic-timing=time-period=0.1, transmission-mode-true-timing=cyclic-timing=time-period=0.1, unused-bit-pattern=0
          signal T_BOX_FD10_0x2F0_oT_BOX_FD10_oB30_for_SC_CAN_V3_2: start 0, 512 bit, opaque, i-signal-type=ARRAY, init-value=64 x 0, base-type=uint8_64_none, compu-method=CM_T_BOX_FD10_0x2F0, data-constr=DC_T_BOX_FD10_0x2F0, transfer-property=PENDING, to HUT
      frame T_BOX_FD3_oB30_for_SC_CAN_V3_2: id 0x3E9, to HUT, frame-length=16, can-addressing-mode=STANDARD, can-frame-rx-behavior=ANY, can-frame-tx-behavior=CAN-FD
        secured i pdu T_BOX_FD3_Sc_oB30_for_SC_CAN_V3_2: length=16, authentication-props=AuthT_BOX_FD3_Sc_oB30_for_SC_CAN_V3_2, freshness-props=FreshnessT_BOX_FD3_Sc_oB30_for_SC_CAN_V3_2, payload=PT_T_BOX_FD3, secure-communication-props={auth-info-tx-length=48, data-id=1001, freshness-value-length=64, freshness-value-tx-length=16}
      frame T_BOX_FD4_oB30_for_SC_CAN_V3_2: id 0x1E1, to HUT, frame-length=16, can-addressing-mode=STANDARD, can-frame-rx-behavior=ANY, can-frame-tx-behavior=CAN-FD
        pdu T_BOX_FD4_oB30_for_SC_CAN_V3_2: length=16, minimum-delay=0, transmission-mode-false-timing=event-controlled-timing={number-of-repetitions=5, repetition-period=0.02}, transmission-mode-true-timing=event-controlled-timing={number-of-repetitions=5, repetition-period=0.02}, unused-bit-pattern=0
          signal T_BOX_FD4_0x1E1_oT_BOX_FD4_oB30_for_SC_CAN_V3_2: start 0, 128 bit, opaque, i-signal-type=ARRAY, init-value=16 x 0, base-type=uint8_16_none, compu-method=CM_T_BOX_FD4_0x1E1, data-constr=DC_T_BOX_FD4_0x1E1, transfer-property=TRIGGERED, to HUT
      frame T_BOX_FD9_oB30_for_SC_CAN_V3_2: id 0x1FE, to HUT, frame-length=8, can-addressing-mode=STANDARD, can-frame-rx-behavior=ANY, can-frame-tx-behavior=CAN-FD
        pdu T_BOX_FD9_oB30_for_SC_CAN_V3_2: length=8, minimum-delay=0, transmission-mode-false-timing=event-controlled-timing={number-of-repetitions=5, repetition-period=0.02}, transmission-mode-true-timing=event-controlled-timing={number-of-repetitions=5, repetition-period=0.02}, unused-bit-pattern=0
          signal T_BOX_FD9_0x1FE_oT_BOX_FD9_oB30_for_SC_CAN_V3_2: start 0, 64 bit, opaque, i-signal-type=ARRAY, init-value=8 x 0, base-type=uint8_8_none, compu-method=CM_T_BOX_FD9_0x1FE, data-constr=DC_T_BOX_FD9_0x1FE, transfer-property=TRIGGERED, to HUT
      frame T_Box_NM_oB30_for_SC_CAN_V3_2: id 0x50A, to HUT, frame-length=8, can-addressing-mode=STANDARD, can-frame-rx-behavior=ANY, can-frame-tx-behavior=CAN-20
        nm pdu T_Box_NM_oB30_for_SC_CAN_V3_2: length=8, unused-bit-pattern=0
      frame TOD1_oB30_for_SC_CAN_V3_2: id 0x251, to HUT, frame-length=8, can-addressing-mode=STANDARD, can-frame-rx-behavior=ANY, can-frame-tx-behavior=CAN-FD
        pdu TOD1_oB30_for_SC_CAN_V3_2: length=8, minimum-delay=0, transmission-mode-false-timing=cyclic-timing=time-period=0.02, transmission-mode-true-timing=cyclic-timing=time-period=0.02, unused-bit-pattern=0
          signal TOD1_0x251_oTOD1_oB30_for_SC_CAN_V3_2: start 0, 64 bit, opaque, i-signal-type=ARRAY, init-value=8 x 0, base-type=uint8_8_none, compu-method=CM_TOD1_0x251, data-constr=DC_TOD1_0x251, transfer-property=PENDING, to HUT
      frame TPMS1_oB30_for_SC_CAN_V3_2: id 0x341, to HUT, frame-length=16, can-addressing-mode=STANDARD, can-frame-rx-behavior=ANY, can-frame-tx-behavior=CAN-FD
        secured i pdu TPMS1_Sc_oB30_for_SC_CAN_V3_2: length=16, authentication-props=AuthTPMS1_Sc_oB30_for_SC_CAN_V3_2, freshness-props=FreshnessTPMS1_Sc_oB30_for_SC_CAN_V3_2, payload=PT_TPMS1, secure-communication-props={auth-info-tx-length=48, data-id=833, freshness-value-length=64, freshness-value-tx-length=16}
      frame TPMS2_oB30_for_SC_CAN_V3_2: id 0x395, to HUT, frame-length=16, can-addressing-mode=STANDARD, can-frame-rx-behavior=ANY, can-frame-tx-behavior=CAN-FD
        secured i pdu TPMS2_Sc_oB30_for_SC_CAN_V3_2: length=16, authentication-props=AuthTPMS2_Sc_oB30_for_SC_CAN_V3_2, freshness-props=FreshnessTPMS2_Sc_oB30_for_SC_CAN_V3_2, payload=PT_TPMS2, secure-communication-props={auth-info-tx-length=48, data-id=917, freshness-value-length=64, freshness-value-tx-length=16}
      frame Trailer1_oB30_for_SC_CAN_V3_2: id 0x273, to HUT, frame-length=8, can-addressing-mode=STANDARD, can-frame-rx-behavior=ANY, can-frame-tx-behavior=CAN-FD
        pdu Trailer1_oB30_for_SC_CAN_V3_2: length=8, minimum-delay=0, transmission-mode-false-timing=cyclic-timing=time-period=0.05, transmission-mode-true-timing=cyclic-timing=time-period=0.05, unused-bit-pattern=0
          signal Trailer1_0x273_oTrailer1_oB30_for_SC_CAN_V3_2: start 0, 64 bit, opaque, i-signal-type=ARRAY, init-value=8 x 0, base-type=uint8_8_none, compu-method=CM_Trailer1_0x273, data-constr=DC_Trailer1_0x273, transfer-property=PENDING, to HUT
      frame VMDR1_oB30_for_SC_CAN_V3_2: id 0x2FB, to HUT, frame-length=8, can-addressing-mode=STANDARD, can-frame-rx-behavior=ANY, can-frame-tx-behavior=CAN-FD
        pdu VMDR1_oB30_for_SC_CAN_V3_2: length=8, minimum-delay=0, transmission-mode-false-timing=cyclic-timing=time-period=0.1, transmission-mode-true-timing=cyclic-timing=time-period=0.1, unused-bit-pattern=0
          signal VMDR1_0x2FB_oVMDR1_oB30_for_SC_CAN_V3_2: start 0, 64 bit, opaque, i-signal-type=ARRAY, init-value=8 x 0, base-type=uint8_8_none, compu-method=CM_VMDR1_0x2FB, data-constr=DC_VMDR1_0x2FB, transfer-property=PENDING, to HUT
      frame WPC1_oB30_for_SC_CAN_V3_2: id 0x2BA, to HUT, frame-length=8, can-addressing-mode=STANDARD, can-frame-rx-behavior=ANY, can-frame-tx-behavior=CAN-FD
        pdu WPC1_oB30_for_SC_CAN_V3_2: length=8, minimum-delay=0, transmission-mode-false-timing=cyclic-timing=time-period=0.1, transmission-mode-true-timing=cyclic-timing=time-period=0.1, unused-bit-pattern=0
          signal WPC1_0x2BA_oWPC1_oB30_for_SC_CAN_V3_2: start 0, 64 bit, opaque, i-signal-type=ARRAY, init-value=8 x 0, base-type=uint8_8_none, compu-method=CM_WPC1_0x2BA, data-constr=DC_WPC1_0x2BA, transfer-property=PENDING, to HUT
      frame XBOX_D_NM_oB30_for_SC_CAN_V3_2: id 0x536, to HUT, frame-length=8, can-addressing-mode=STANDARD, can-frame-rx-behavior=ANY, can-frame-tx-behavior=CAN-20
        nm pdu XBOX_D_NM_oB30_for_SC_CAN_V3_2: length=8, unused-bit-pattern=0
      pdu triggering PT_ABM1: pdu=ABM1_oB30_for_SC_CAN_V3_2, to HUT
      pdu triggering PT_ACC_FD2: pdu=ACC_FD2_oB30_for_SC_CAN_V3_2, to HUT
      pdu triggering PT_AEB_FD2: pdu=AEB_FD2_oB30_for_SC_CAN_V3_2, to HUT
      pdu triggering PT_AMP2: pdu=AMP2_oB30_for_SC_CAN_V3_2, to HUT
      pdu triggering PT_BCM1: pdu=BCM1_oB30_for_SC_CAN_V3_2, to HUT
      pdu triggering PT_BCM3: pdu=BCM3_oB30_for_SC_CAN_V3_2, to HUT
      pdu triggering PT_DiagFuncReq: pdu=DiagFuncReq_oB30_for_SC_CAN_V3_2, to HUT
      pdu triggering PT_DiagFuncReq_20: pdu=DiagFuncReq_oB30_for_SC_CAN_V3_2_20, to HUT
      pdu triggering PT_ESP_FD2: pdu=ESP_FD2_oB30_for_SC_CAN_V3_2, to HUT
      pdu triggering PT_GW_Sync_Req: pdu=GW_Sync_Req_oB30_for_SC_CAN_V3_2, to HUT
      pdu triggering PT_HUT_FD1: pdu=HUT_FD1_oB30_for_SC_CAN_V3_2, from HUT
      pdu triggering PT_HUT_Phy_Req: pdu=HUT_Phy_Req_oB30_for_SC_CAN_V3_2, to HUT
      pdu triggering PT_HUT_Phy_Req_20: pdu=HUT_Phy_Req_oB30_for_SC_CAN_V3_2_20, to HUT
      pdu triggering PT_HUT_Phy_Resp: pdu=HUT_Phy_Resp_oB30_for_SC_CAN_V3_2, from HUT
      pdu triggering PT_HUT_Phy_Resp_20: pdu=HUT_Phy_Resp_oB30_for_SC_CAN_V3_2_20, from HUT
      pdu triggering PT_HUT15: pdu=HUT15_oB30_for_SC_CAN_V3_2, from HUT
      pdu triggering PT_IFC_FD2: pdu=IFC_FD2_oB30_for_SC_CAN_V3_2, to HUT
      pdu triggering PT_IP2: pdu=IP2_oB30_for_SC_CAN_V3_2, from HUT
      pdu triggering PT_R_PBOX1: pdu=R_PBOX1_oB30_for_SC_CAN_V3_2, to HUT
      pdu triggering PT_T_BOX_FD1: pdu=T_BOX_FD1_oB30_for_SC_CAN_V3_2, to HUT
      pdu triggering PT_T_BOX_FD3: pdu=T_BOX_FD3_oB30_for_SC_CAN_V3_2, to HUT
      pdu triggering PT_TPMS1: pdu=TPMS1_oB30_for_SC_CAN_V3_2, to HUT
      pdu triggering PT_TPMS2: pdu=TPMS2_oB30_for_SC_CAN_V3_2, to HUT
  can cluster CAN: baudrate=500000, protocol-name=CAN, can-fd-baudrate=500000  # CAN_FD_Mode2
    can physical channel CHNL: comm-connectors=CN_CAN
      frame GlobalTimeMaster_oCAN: id 0x380, to HUT, frame-length=8, can-addressing-mode=STANDARD, can-frame-rx-behavior=ANY, can-frame-tx-behavior=CAN-20
        user defined pdu GlobalTimeMaster_oCAN: length=8
      frame msg_diag_Request_MyECU_oCAN: id 0x610, to HUT, frame-length=8, can-addressing-mode=STANDARD, can-frame-rx-behavior=CAN-20, can-frame-tx-behavior=CAN-20
        n pdu msg_diag_Request_MyECU_Tp_oCAN: length=8
      frame msg_diag_Request_MyECU_Slave3_oCAN: id 0x611, to HUT, frame-length=8, can-addressing-mode=STANDARD, can-frame-rx-behavior=ANY, can-frame-tx-behavior=CAN-20
        user defined pdu msg_diag_Request_MyECU_Slave3_oCAN: length=8
      frame msg_diag_RequestGlobal_oCAN: id 0x614, to HUT, frame-length=8, can-addressing-mode=STANDARD, can-frame-rx-behavior=CAN-20, can-frame-tx-behavior=CAN-20
        n pdu msg_diag_RequestGlobal_Tp_oCAN: length=8
      frame msg_diag_Response_MyECU_oCAN: id 0x612, from HUT, frame-length=8, can-addressing-mode=STANDARD, can-frame-rx-behavior=CAN-20, can-frame-tx-behavior=CAN-20
        n pdu msg_diag_Response_MyECU_Tp_oCAN: length=8
      frame msg_diag_Response_MyECU_Slave3_oCAN: id 0x613, from HUT, frame-length=8, can-addressing-mode=STANDARD, can-frame-rx-behavior=ANY, can-frame-tx-behavior=CAN-20
        user defined pdu msg_diag_Response_MyECU_Slave3_oCAN: length=8
      frame msg_diag_Uudt_Response_MyECU_oCAN: id 0x616, from HUT, frame-length=8, can-addressing-mode=STANDARD, can-frame-rx-behavior=CAN-20, can-frame-tx-behavior=CAN-20
        dcm i pdu msg_diag_Uudt_Response_MyECU_oCAN: length=8, diag-pdu-type=DIAG-RESPONSE
      frame msg_nm_MyECU_oCAN: id 0x400, from HUT, frame-length=8, can-addressing-mode=STANDARD, can-frame-rx-behavior=ANY, can-frame-tx-behavior=CAN-20
        nm pdu msg_nm_MyECU_oCAN: length=8, unused-bit-pattern=0
          signal NmUd_MyECU_16bit_omsg_nm_MyECU_oCAN: start 16, 16 bit, little-endian, i-signal-type=PRIMITIVE, init-value=0, base-type=uint16, compu-method=CM_NmUd_MyECU_16bit, data-constr=DC_NmUd_MyECU_16bit, transfer-property=PENDING
          signal NmUd_MyECU_32bit_omsg_nm_MyECU_oCAN: start 32, 32 bit, little-endian, i-signal-type=PRIMITIVE, init-value=0, base-type=uint32, compu-method=CM_NmUd_MyECU_32bit, data-constr=DC_NmUd_MyECU_32bit, transfer-property=PENDING
      frame msg_nm_OtherECU_oCAN: id 0x402, to HUT, frame-length=8, can-addressing-mode=STANDARD, can-frame-rx-behavior=ANY, can-frame-tx-behavior=CAN-20
        nm pdu msg_nm_OtherECU_oCAN: length=8, unused-bit-pattern=0
      frame msg_nm_RearECU_oCAN: id 0x401, to HUT, frame-length=8, can-addressing-mode=STANDARD, can-frame-rx-behavior=ANY, can-frame-tx-behavior=CAN-20
        nm pdu msg_nm_RearECU_oCAN: length=8, unused-bit-pattern=0
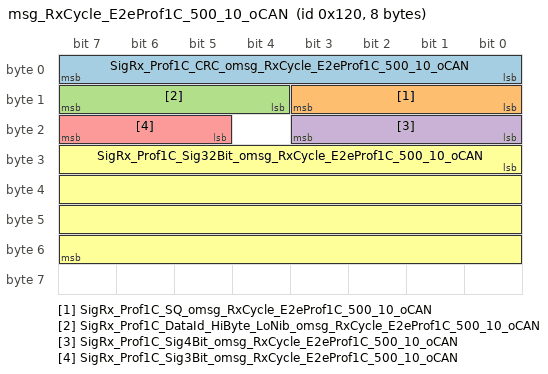
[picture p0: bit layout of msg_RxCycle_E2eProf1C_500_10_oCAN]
      frame msg_RxCycle_E2eProf1C_500_10_oCAN: id 0x120, to HUT, frame-length=8, can-addressing-mode=STANDARD, can-frame-rx-behavior=ANY, can-frame-tx-behavior=CAN-FD
        pdu msg_RxCycle_E2eProf1C_500_10_oCAN: length=8, minimum-delay=0, transmission-mode-false-timing=cyclic-timing={time-offset=0.01, time-period=0.5}, transmission-mode-true-timing=cyclic-timing={time-offset=0.01, time-period=0.5}, unused-bit-pattern=0
          signal SigRx_Prof1C_CRC_omsg_RxCycle_E2eProf1C_500_10_oCAN: start 0, 8 bit, little-endian, i-signal-type=PRIMITIVE, init-value=0, base-type=uint8, compu-method=CM_SigRx_Prof1C_CRC, data-constr=DC_SigRx_Prof1C_CRC, transfer-property=PENDING, to HUT
          signal SigRx_Prof1C_SQ_omsg_RxCycle_E2eProf1C_500_10_oCAN: start 8, 4 bit, little-endian, i-signal-type=PRIMITIVE, init-value=0, base-type=uint8, compu-method=CM_SigRx_Prof1C_SQ, data-constr=DC_SigRx_Prof1C_SQ, transfer-property=PENDING, to HUT
          signal SigRx_Prof1C_DataId_HiByte_LoNib_omsg_RxCycle_E2eProf1C_500_10_oCAN: start 12, 4 bit, little-endian, i-signal-type=PRIMITIVE, init-value=0, base-type=uint8, compu-method=CM_SigRx_Prof1C_DataId_HiByte_LoNib, data-constr=DC_SigRx_Prof1C_DataId_HiByte_LoNib, transfer-property=PENDING, to HUT
          signal SigRx_Prof1C_Sig4Bit_omsg_RxCycle_E2eProf1C_500_10_oCAN: start 16, 4 bit, little-endian, i-signal-type=PRIMITIVE, init-value=0, base-type=uint8, compu-method=CM_SigRx_Prof1C_Sig4Bit, data-constr=DC_SigRx_Prof1C_Sig4Bit, transfer-property=PENDING, to HUT
          signal SigRx_Prof1C_Sig3Bit_omsg_RxCycle_E2eProf1C_500_10_oCAN: start 21, 3 bit, little-endian, i-signal-type=PRIMITIVE, init-value=0, base-type=uint8, compu-method=CM_SigRx_Prof1C_Sig3Bit, data-constr=DC_SigRx_Prof1C_Sig3Bit, transfer-property=PENDING, to HUT
          signal SigRx_Prof1C_Sig32Bit_omsg_RxCycle_E2eProf1C_500_10_oCAN: start 24, 32 bit, little-endian, i-signal-type=PRIMITIVE, init-value=0, base-type=uint32, compu-method=CM_SigRx_Prof1C_Sig32Bit, data-constr=DC_SigRx_Prof1C_Sig32Bit, transfer-property=PENDING, to HUT
          mapping SG_RgRx_Prof1C_RxCycle: i-signal-group=SG_RgRx_Prof1C_RxCycle_omsg_RxCycle_E2eProf1C_500_10_oCAN, transfer-property=PENDING
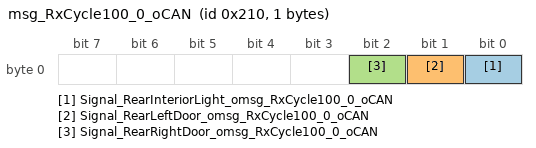
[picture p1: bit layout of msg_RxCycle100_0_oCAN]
      frame msg_RxCycle100_0_oCAN: id 0x210, to HUT, frame-length=1, can-addressing-mode=STANDARD, can-frame-rx-behavior=ANY, can-frame-tx-behavior=CAN-FD
        pdu msg_RxCycle100_0_oCAN: length=1, minimum-delay=0, transmission-mode-false-timing=cyclic-timing={time-offset=0, time-period=0.1}, transmission-mode-true-timing=cyclic-timing={time-offset=0, time-period=0.1}, unused-bit-pattern=0
          signal Signal_RearInteriorLight_omsg_RxCycle100_0_oCAN: start 0, 1 bit, little-endian, i-signal-type=PRIMITIVE, init-value=0, base-type=boolean, compu-method=CM_Signal_RearInteriorLight, data-constr=DC_Signal_RearInteriorLight, transfer-property=PENDING, to HUT
          signal Signal_RearLeftDoor_omsg_RxCycle100_0_oCAN: start 1, 1 bit, little-endian, i-signal-type=PRIMITIVE, init-value=0, base-type=boolean, compu-method=CM_Signal_RearLeftDoor, data-constr=DC_Signal_RearLeftDoor, transfer-property=PENDING, to HUT
          signal Signal_RearRightDoor_omsg_RxCycle100_0_oCAN: start 2, 1 bit, little-endian, i-signal-type=PRIMITIVE, init-value=0, base-type=boolean, compu-method=CM_Signal_RearRightDoor, data-constr=DC_Signal_RearRightDoor, transfer-property=PENDING, to HUT
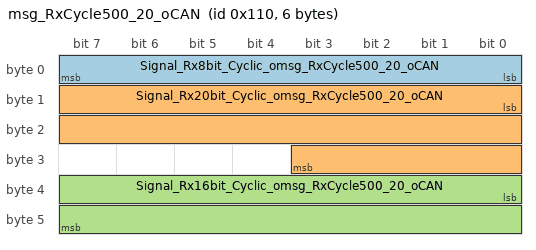
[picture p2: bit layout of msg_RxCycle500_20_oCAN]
      frame msg_RxCycle500_20_oCAN: id 0x110, to HUT, frame-length=6, can-addressing-mode=STANDARD, can-frame-rx-behavior=ANY, can-frame-tx-behavior=CAN-FD
        pdu msg_RxCycle500_20_oCAN: length=6, minimum-delay=0, transmission-mode-false-timing=cyclic-timing={time-offset=0.02, time-period=0.5}, transmission-mode-true-timing=cyclic-timing={time-offset=0.02, time-period=0.5}, unused-bit-pattern=0
          signal Signal_Rx8bit_Cyclic_omsg_RxCycle500_20_oCAN: start 0, 8 bit, little-endian, i-signal-type=PRIMITIVE, init-value=15, base-type=uint8, compu-method=CM_Signal_Rx8bit_Cyclic, data-constr=DC_Signal_Rx8bit_Cyclic, transfer-property=PENDING, to HUT
          signal Signal_Rx20bit_Cyclic_omsg_RxCycle500_20_oCAN: start 8, 20 bit, little-endian, i-signal-type=PRIMITIVE, init-value=1, base-type=uint32, compu-method=CM_Signal_Rx20bit_Cyclic, data-constr=DC_Signal_Rx20bit_Cyclic, transfer-property=PENDING, to HUT
          signal Signal_Rx16bit_Cyclic_omsg_RxCycle500_20_oCAN: start 32, 16 bit, little-endian, i-signal-type=PRIMITIVE, init-value=32768, base-type=uint16, compu-method=CM_Signal_Rx16bit_Cyclic, data-constr=DC_Signal_Rx16bit_Cyclic, transfer-property=PENDING, to HUT
      frame msg_RxEvent_20_oCAN: id 0x310, to HUT, frame-length=4, can-addressing-mode=STANDARD, can-frame-rx-behavior=ANY, can-frame-tx-behavior=CAN-FD
        pdu msg_RxEvent_20_oCAN: length=4, minimum-delay=0, transmission-mode-false-timing=event-controlled-timing={number-of-repetitions=0, repetition-period=0}, transmission-mode-true-timing=event-controlled-timing={number-of-repetitions=0, repetition-period=0}, unused-bit-pattern=0
          signal Signal_Rx11bit_OnWrite_omsg_RxEvent_20_oCAN: start 0, 11 bit, little-endian, i-signal-type=PRIMITIVE, init-value=50, base-type=uint16, compu-method=CM_Signal_Rx11bit_OnWrite, data-constr=DC_Signal_Rx11bit_OnWrite, transfer-property=TRIGGERED-WITHOUT-REPETITION, to HUT
          signal Signal_Rx15bit_OnWrite_omsg_RxEvent_20_oCAN: start 12, 15 bit, little-endian, i-signal-type=PRIMITIVE, init-value=25, base-type=uint16, compu-method=CM_Signal_Rx15bit_OnWrite, data-constr=DC_Signal_Rx15bit_OnWrite, transfer-property=TRIGGERED-WITHOUT-REPETITION, to HUT
      frame msg_StartAppl_Rx_MyECU_oCAN: id 0x501, to HUT, frame-length=64, can-addressing-mode=STANDARD, can-frame-rx-behavior=ANY, can-frame-tx-behavior=CAN-FD
        pdu msg_StartAppl_Rx_MyECU_oCAN: length=64, minimum-delay=0, transmission-mode-false-timing=cyclic-timing={time-offset=0, time-period=0.05}, transmission-mode-true-timing=cyclic-timing={time-offset=0, time-period=0.05}, unused-bit-pattern=0
          signal Signal_StartAppl_RxCtrl_MyECU_omsg_StartAppl_Rx_MyECU_oCAN: start 0, 8 bit, little-endian, i-signal-type=PRIMITIVE, init-value=0, base-type=uint8, compu-method=CM_Signal_StartAppl_RxCtrl_MyECU, data-constr=DC_Signal_StartAppl_RxCtrl_MyECU, transfer-property=PENDING, to HUT
          signal Signal_StartAppl_RxData_MyECU_omsg_StartAppl_Rx_MyECU_oCAN: start 8, 8 bit, little-endian, i-signal-type=PRIMITIVE, init-value=0, base-type=uint8, compu-method=CM_Signal_StartAppl_RxData_MyECU, data-constr=DC_Signal_StartAppl_RxData_MyECU, transfer-property=PENDING, to HUT
      frame msg_StartAppl_Tx_MyECU_oCAN: id 0x500, from HUT, frame-length=64, can-addressing-mode=STANDARD, can-frame-rx-behavior=ANY, can-frame-tx-behavior=CAN-FD
        pdu msg_StartAppl_Tx_MyECU_oCAN: length=64, minimum-delay=0, transmission-mode-false-timing=cyclic-timing={time-offset=0, time-period=0.05}, transmission-mode-true-timing=cyclic-timing={time-offset=0, time-period=0.05}, unused-bit-pattern=0
          signal Signal_StartAppl_TxCtrl_MyECU_omsg_StartAppl_Tx_MyECU_oCAN: start 0, 8 bit, little-endian, i-signal-type=PRIMITIVE, init-value=0, base-type=uint8, compu-method=CM_Signal_StartAppl_TxCtrl_MyECU, data-constr=DC_Signal_StartAppl_TxCtrl_MyECU, transfer-property=PENDING
          signal Signal_StartAppl_TxData_MyECU_omsg_StartAppl_Tx_MyECU_oCAN: start 8, 8 bit, little-endian, i-signal-type=PRIMITIVE, init-value=0, base-type=uint8, compu-method=CM_Signal_StartAppl_TxData_MyECU, data-constr=DC_Signal_StartAppl_TxData_MyECU, transfer-property=PENDING
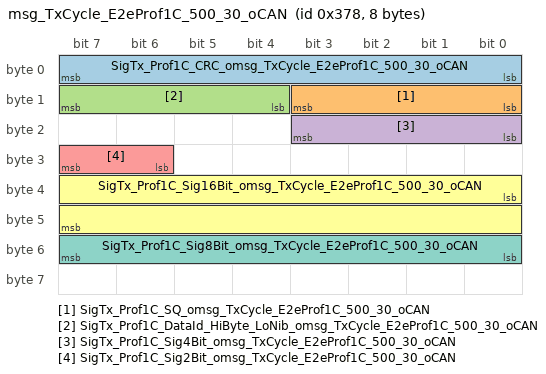
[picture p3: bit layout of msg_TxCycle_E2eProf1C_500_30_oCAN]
      frame msg_TxCycle_E2eProf1C_500_30_oCAN: id 0x378, from HUT, frame-length=8, can-addressing-mode=STANDARD, can-frame-rx-behavior=ANY, can-frame-tx-behavior=CAN-FD
        pdu msg_TxCycle_E2eProf1C_500_30_oCAN: length=8, minimum-delay=0, transmission-mode-false-timing=cyclic-timing={time-offset=0.03, time-period=0.5}, transmission-mode-true-timing=cyclic-timing={time-offset=0.03, time-period=0.5}, unused-bit-pattern=0
          signal SigTx_Prof1C_CRC_omsg_TxCycle_E2eProf1C_500_30_oCAN: start 0, 8 bit, little-endian, i-signal-type=PRIMITIVE, init-value=0, base-type=uint8, compu-method=CM_SigTx_Prof1C_CRC, data-constr=DC_SigTx_Prof1C_CRC, transfer-property=PENDING
          signal SigTx_Prof1C_SQ_omsg_TxCycle_E2eProf1C_500_30_oCAN: start 8, 4 bit, little-endian, i-signal-type=PRIMITIVE, init-value=0, base-type=uint8, compu-method=CM_SigTx_Prof1C_SQ, data-constr=DC_SigTx_Prof1C_SQ, transfer-property=PENDING
          signal SigTx_Prof1C_DataId_HiByte_LoNib_omsg_TxCycle_E2eProf1C_500_30_oCAN: start 12, 4 bit, little-endian, i-signal-type=PRIMITIVE, init-value=0, base-type=uint8, compu-method=CM_SigTx_Prof1C_DataId_HiByte_LoNib, data-constr=DC_SigTx_Prof1C_DataId_HiByte_LoNib, transfer-property=PENDING
          signal SigTx_Prof1C_Sig4Bit_omsg_TxCycle_E2eProf1C_500_30_oCAN: start 16, 4 bit, little-endian, i-signal-type=PRIMITIVE, init-value=0, base-type=uint8, compu-method=CM_SigTx_Prof1C_Sig4Bit, data-constr=DC_SigTx_Prof1C_Sig4Bit, transfer-property=PENDING
          signal SigTx_Prof1C_Sig2Bit_omsg_TxCycle_E2eProf1C_500_30_oCAN: start 30, 2 bit, little-endian, i-signal-type=PRIMITIVE, init-value=0, base-type=uint8, compu-method=CM_SigTx_Prof1C_Sig2Bit, data-constr=DC_SigTx_Prof1C_Sig2Bit, transfer-property=PENDING
          signal SigTx_Prof1C_Sig16Bit_omsg_TxCycle_E2eProf1C_500_30_oCAN: start 32, 16 bit, little-endian, i-signal-type=PRIMITIVE, init-value=0, base-type=uint16, compu-method=CM_SigTx_Prof1C_Sig16Bit, data-constr=DC_SigTx_Prof1C_Sig16Bit, transfer-property=PENDING
          signal SigTx_Prof1C_Sig8Bit_omsg_TxCycle_E2eProf1C_500_30_oCAN: start 48, 8 bit, little-endian, i-signal-type=PRIMITIVE, init-value=0, base-type=uint8, compu-method=CM_SigTx_Prof1C_Sig8Bit, data-constr=DC_SigTx_Prof1C_Sig8Bit, transfer-property=PENDING
          mapping SG_SgTx_Prof1C_TxCycle: i-signal-group=SG_SgTx_Prof1C_TxCycle_omsg_TxCycle_E2eProf1C_500_30_oCAN, transfer-property=PENDING
      frame msg_TxCycle10_0_oCAN: id 0x268, from HUT, frame-length=7, can-addressing-mode=STANDARD, can-frame-rx-behavior=ANY, can-frame-tx-behavior=CAN-FD
        pdu msg_TxCycle10_0_oCAN: length=7, minimum-delay=0, transmission-mode-false-timing=cyclic-timing={time-offset=0, time-period=0.01}, transmission-mode-true-timing=cyclic-timing={time-offset=0, time-period=0.01}, unused-bit-pattern=0
          signal Signal_Tx32bit_Cyclic_omsg_TxCycle10_0_oCAN: start 0, 32 bit, little-endian, i-signal-type=PRIMITIVE, init-value=0, base-type=uint32, compu-method=CM_Signal_Tx32bit_Cyclic, data-constr=DC_Signal_Tx32bit_Cyclic, transfer-property=PENDING
          signal Signal_Tx24bit_Cyclic_omsg_TxCycle10_0_oCAN: start 32, 24 bit, little-endian, i-signal-type=PRIMITIVE, init-value=0, base-type=uint32, compu-method=CM_Signal_Tx24bit_Cyclic, data-constr=DC_Signal_Tx24bit_Cyclic, transfer-property=PENDING
      frame msg_TxCycle1000_10_oCAN: id 0x368, from HUT, frame-length=2, can-addressing-mode=STANDARD, can-frame-rx-behavior=ANY, can-frame-tx-behavior=CAN-FD
        pdu msg_TxCycle1000_10_oCAN: length=2, minimum-delay=0, transmission-mode-false-timing=cyclic-timing={time-offset=0.01, time-period=1}, transmission-mode-true-timing=cyclic-timing={time-offset=0.01, time-period=1}, unused-bit-pattern=0
          signal Signal_Tx10bit_Cyclic_omsg_TxCycle1000_10_oCAN: start 0, 10 bit, little-endian, i-signal-type=PRIMITIVE, init-value=0, base-type=uint16, compu-method=CM_Signal_Tx10bit_Cyclic, data-constr=DC_Signal_Tx10bit_Cyclic, transfer-property=PENDING
          signal Signal_Tx4bit_Cyclic_omsg_TxCycle1000_10_oCAN: start 10, 4 bit, little-endian, i-signal-type=PRIMITIVE, init-value=0, base-type=uint8, compu-method=CM_Signal_Tx4bit_Cyclic, data-constr=DC_Signal_Tx4bit_Cyclic, transfer-property=PENDING
      frame msg_TxEvent_10_oCAN: id 0x168, from HUT, frame-length=7, can-addressing-mode=STANDARD, can-frame-rx-behavior=ANY, can-frame-tx-behavior=CAN-FD
        pdu msg_TxEvent_10_oCAN: length=7, minimum-delay=0, transmission-mode-false-timing=event-controlled-timing={number-of-repetitions=0, repetition-period=0}, transmission-mode-true-timing=event-controlled-timing={number-of-repetitions=0, repetition-period=0}, unused-bit-pattern=0
          signal Signal_Tx32bit_OnWrite_omsg_TxEvent_10_oCAN: start 0, 32 bit, little-endian, i-signal-type=PRIMITIVE, init-value=31, base-type=uint32, compu-method=CM_Signal_Tx32bit_OnWrite, data-constr=DC_Signal_Tx32bit_OnWrite, transfer-property=TRIGGERED-WITHOUT-REPETITION
          signal Signal_Tx24bit_OnWrite_omsg_TxEvent_10_oCAN: start 32, 24 bit, little-endian, i-signal-type=PRIMITIVE, init-value=63, base-type=uint32, compu-method=CM_Signal_Tx24bit_OnWrite, data-constr=DC_Signal_Tx24bit_OnWrite, transfer-property=TRIGGERED-WITHOUT-REPETITION
      frame msg_XCP_Request_MyECU_oCAN: id 0x703, to HUT, frame-length=8, can-addressing-mode=STANDARD, can-frame-rx-behavior=ANY, can-frame-tx-behavior=CAN-20
        xcp pdu msg_XCP_Request_MyECU_oCAN: length=8
      frame msg_XCP_Response_MyECU_oCAN: id 0x704, from HUT, frame-length=8, can-addressing-mode=STANDARD, can-frame-rx-behavior=ANY, can-frame-tx-behavior=CAN-20
        xcp pdu msg_XCP_Response_MyECU_oCAN: length=8
      pdu triggering PT_msg_diag_Request_MyECU: pdu=msg_diag_Request_MyECU_oCAN, to HUT
      pdu triggering PT_msg_diag_RequestGlobal: pdu=msg_diag_RequestGlobal_oCAN, to HUT
      pdu triggering PT_msg_diag_Response_MyECU: pdu=msg_diag_Response_MyECU_oCAN, from HUT
  lin cluster LIN00: baudrate=19200, protocol-name=LIN, protocol-version=LIN20  # LIN_MyECU
    lin physical channel CHNL: comm-connectors=CN_LIN00
      frame Frame_LinTr_HUT_oLIN00: id 0x11, from HUT, frame-length=1, lin-checksum=ENHANCED
        pdu Frame_LinTr_HUT_oLIN00: length=1, unused-bit-pattern=255
          signal Sig_StartAppl_LinData_Tx_oFrame_LinTr_HUT_oLIN00: start 0, 8 bit, little-endian, i-signal-type=PRIMITIVE, init-value=0, base-type=uint8, compu-method=CM_Sig_StartAppl_LinData_Tx, data-constr=DC_Sig_StartAppl_LinData_Tx
      frame Frame_LinTr_HUT2_oLIN00: id 0x13, from HUT, frame-length=3, lin-checksum=ENHANCED
        pdu Frame_LinTr_HUT2_oLIN00: length=3, unused-bit-pattern=255
          signal Sig_LinTr_HUT2_0_oFrame_LinTr_HUT2_oLIN00: start 0, 6 bit, little-endian, i-signal-type=PRIMITIVE, init-value=0, base-type=uint8, compu-method=CM_Sig_LinTr_HUT2_0, data-constr=DC_Sig_LinTr_HUT2_0
          signal Sig_LinTr_HUT2_1_oFrame_LinTr_HUT2_oLIN00: start 6, 14 bit, little-endian, i-signal-type=PRIMITIVE, init-value=0, base-type=uint16, compu-method=CM_Sig_LinTr_HUT2_1, data-constr=DC_Sig_LinTr_HUT2_1
      frame Frame_LinTr_RearECU_oLIN00: id 0x12, to HUT, frame-length=1, lin-checksum=ENHANCED
        pdu Frame_LinTr_RearECU_oLIN00: length=1, unused-bit-pattern=255
          signal Sig_StartAppl_LinData_Rx_oFrame_LinTr_RearECU_oLIN00: start 0, 8 bit, little-endian, i-signal-type=PRIMITIVE, init-value=0, base-type=uint8, compu-method=CM_Sig_StartAppl_LinData_Rx, data-constr=DC_Sig_StartAppl_LinData_Rx, to HUT
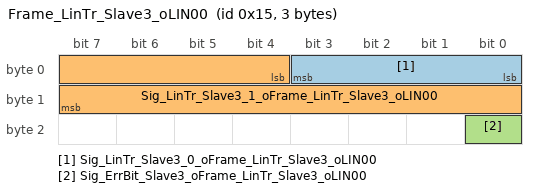
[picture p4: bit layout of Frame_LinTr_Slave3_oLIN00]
      frame Frame_LinTr_Slave3_oLIN00: id 0x15, to HUT, frame-length=3, lin-checksum=ENHANCED
        pdu Frame_LinTr_Slave3_oLIN00: length=3, unused-bit-pattern=255
          signal Sig_LinTr_Slave3_0_oFrame_LinTr_Slave3_oLIN00: start 0, 4 bit, little-endian, i-signal-type=PRIMITIVE, init-value=0, base-type=uint8, compu-method=CM_Sig_LinTr_Slave3_0, data-constr=DC_Sig_LinTr_Slave3_0, to HUT
          signal Sig_LinTr_Slave3_1_oFrame_LinTr_Slave3_oLIN00: start 4, 12 bit, little-endian, i-signal-type=PRIMITIVE, init-value=0, base-type=uint16, compu-method=CM_Sig_LinTr_Slave3_1, data-constr=DC_Sig_LinTr_Slave3_1, to HUT
          signal Sig_ErrBit_Slave3_oFrame_LinTr_Slave3_oLIN00: start 16, 1 bit, little-endian, i-signal-type=PRIMITIVE, init-value=0, base-type=boolean, compu-method=CM_Sig_ErrBit_Slave3, data-constr=DC_Sig_ErrBit_Slave3, to HUT
      frame MasterReq_oLIN00: id 0x3C, from HUT, frame-length=8, lin-checksum=CLASSIC
        n pdu MasterReq_Tp_oLIN00: length=8
      frame SlaveResp_oLIN00: id 0x3D, to HUT, frame-length=8, lin-checksum=CLASSIC
        n pdu SlaveResp_Tp_oLIN00: length=8
      pdu triggering PT_MasterReq: pdu=MasterReq_oLIN00, from HUT
      pdu triggering PT_MasterReq_RearECU: pdu=MasterReq_RearECU_oLIN00, from HUT
      pdu triggering PT_MasterReq_Slave3: pdu=MasterReq_Slave3_oLIN00, from HUT
      pdu triggering PT_SlaveResp_RearECU: pdu=SlaveResp_RearECU_oLIN00, to HUT
      pdu triggering PT_SlaveResp_Slave3: pdu=SlaveResp_Slave3_oLIN00, to HUT
      lin schedule table Diagnose: run-mode=RUN-CONTINUOUS
        table-entrys:
          delay=0.08, position-in-table=0, frame-triggering=FT_MasterReq
          delay=0.08, position-in-table=1, frame-triggering=FT_SlaveResp
      lin schedule table Normal: run-mode=RUN-CONTINUOUS
        table-entrys:
          delay=0.005, position-in-table=0, frame-triggering=FT_Frame_LinTr_HUT
          delay=0.005, position-in-table=1, frame-triggering=FT_Frame_LinTr_RearECU
          delay=0.01, position-in-table=2, frame-triggering=FT_Frame_LinTr_HUT2
          delay=0.01, position-in-table=3, frame-triggering=FT_Frame_LinTr_Slave3
package /ECU
  ecu instance HUT: associated-com-i-pdu-group=[HUT_oB30_for_SC_CAN_V3_2_Rx, HUT_oB30_for_SC_CAN_V3_2_Tx, HUT_oCAN_Rx, HUT_oCAN_Tx, HUT_oLIN00_Rx, HUT_oLIN00_Tx]
    can communication controller CT_B30_for_SC_CAN_V3_2
    can communication controller CT_CAN
    lin master CT_LIN00: protocol-version=LIN20, time-base=0.001, time-base-jitter=0
    can communication connector CN_B30_for_SC_CAN_V3_2: comm-controller=CT_B30_for_SC_CAN_V3_2
    can communication connector CN_CAN: comm-controller=CT_CAN
    lin communication connector CN_LIN00: comm-controller=CT_LIN00
package /Gateway
  gateway HUT: ecu=HUT
package /IPDUGroup
  6 x i signal i pdu group:
    HUT_oB30_for_SC_CAN_V3_2_Rx: communication-direction=IN
      i-signal-i-pdus:
        ABM1_oB30_for_SC_CAN_V3_2
        ABM2_oB30_for_SC_CAN_V3_2
        ABS1_oB30_for_SC_CAN_V3_2
        ABS2_oB30_for_SC_CAN_V3_2
        AC1_oB30_for_SC_CAN_V3_2
        AC14_oB30_for_SC_CAN_V3_2
        AC{2..4}_oB30_for_SC_CAN_V3_2
        AC{6..8}_oB30_for_SC_CAN_V3_2
        ACC_FD{2..4}_oB30_for_SC_CAN_V3_2
        AEB_FD1_oB30_for_SC_CAN_V3_2
        AEB_FD2_oB30_for_SC_CAN_V3_2
        ALS1_oB30_for_SC_CAN_V3_2
        AMP{1..3}_oB30_for_SC_CAN_V3_2
        AMP4_ANC1_oB30_for_SC_CAN_V3_2
        BCM1_oB30_for_SC_CAN_V3_2
        BCM11_oB30_for_SC_CAN_V3_2
        BCM12_oB30_for_SC_CAN_V3_2
        BCM14_oB30_for_SC_CAN_V3_2
        BCM18_oB30_for_SC_CAN_V3_2
        BCM19_oB30_for_SC_CAN_V3_2
        BCM3_oB30_for_SC_CAN_V3_2
        BCM7_oB30_for_SC_CAN_V3_2
        BCM8_oB30_for_SC_CAN_V3_2
        BLE1_oB30_for_SC_CAN_V3_2
        BLE5_oB30_for_SC_CAN_V3_2
        BMS_FD14_oB30_for_SC_CAN_V3_2
        BMS19_oB30_for_SC_CAN_V3_2
        BMS22_oB30_for_SC_CAN_V3_2
        BMS30_oB30_for_SC_CAN_V3_2
        BMS35_oB30_for_SC_CAN_V3_2
        BMS4_oB30_for_SC_CAN_V3_2
        BMS65_oB30_for_SC_CAN_V3_2
        BMS66_oB30_for_SC_CAN_V3_2
        BMS8_oB30_for_SC_CAN_V3_2
        CP1_oB30_for_SC_CAN_V3_2
        CR_FD1_oB30_for_SC_CAN_V3_2
        CSA{1..3}_oB30_for_SC_CAN_V3_2
        DCT_FD4_oB30_for_SC_CAN_V3_2
        DCT3_oB30_for_SC_CAN_V3_2
        DCT5_oB30_for_SC_CAN_V3_2
        DDCM1_oB30_for_SC_CAN_V3_2
        DDCM3_oB30_for_SC_CAN_V3_2
        DOCK1_oB30_for_SC_CAN_V3_2
        DOCK2_oB30_for_SC_CAN_V3_2
        DSC4_oB30_for_SC_CAN_V3_2
        DSM1_oB30_for_SC_CAN_V3_2
        DWD1_oB30_for_SC_CAN_V3_2
        EBOOSTER_FD1_oB30_for_SC_CAN_V3_2
        ECM_PT{5..7}_oB30_for_SC_CAN_V3_2
        ECM1_oB30_for_SC_CAN_V3_2
        ECM11_oB30_for_SC_CAN_V3_2
        ECM16_oB30_for_SC_CAN_V3_2
        ECM19_oB30_for_SC_CAN_V3_2
        ECM2_oB30_for_SC_CAN_V3_2
        ECM20_oB30_for_SC_CAN_V3_2
        ECM24_oB30_for_SC_CAN_V3_2
        ECM3_oB30_for_SC_CAN_V3_2
        ECM4_oB30_for_SC_CAN_V3_2
        ECM7_oB30_for_SC_CAN_V3_2
        ECM9_oB30_for_SC_CAN_V3_2
        EEM1_oB30_for_SC_CAN_V3_2
        ELD1_oB30_for_SC_CAN_V3_2
        EPB1_oB30_for_SC_CAN_V3_2
        EPS_FD1_oB30_for_SC_CAN_V3_2
        ESCL2_oB30_for_SC_CAN_V3_2
        ESP_FD2_oB30_for_SC_CAN_V3_2
        ESP11_oB30_for_SC_CAN_V3_2
        ESP8_oB30_for_SC_CAN_V3_2
        ETC{2..4}_oB30_for_SC_CAN_V3_2
        F_PBOX1_oB30_for_SC_CAN_V3_2
        GLO_NASS1_oB30_for_SC_CAN_V3_2
        GW_FD1_oB30_for_SC_CAN_V3_2
        GW_OTA_oB30_for_SC_CAN_V3_2
        GW_Sync_Req_oB30_for_SC_CAN_V3_2
        HAP_FD{1..3}_oB30_for_SC_CAN_V3_2
        HAP_FD6_oB30_for_SC_CAN_V3_2
        HAP_FD7_oB30_for_SC_CAN_V3_2
        HCM_L1_oB30_for_SC_CAN_V3_2
        HCM_L2_oB30_for_SC_CAN_V3_2
        HCM_R1_oB30_for_SC_CAN_V3_2
        HCM_R2_oB30_for_SC_CAN_V3_2
        HCU_FD1_oB30_for_SC_CAN_V3_2
        HCU_HC16_oB30_for_SC_CAN_V3_2
        HCU_HC3_oB30_for_SC_CAN_V3_2
        HCU_HC{6..8}_oB30_for_SC_CAN_V3_2
        HCU_HP5_oB30_for_SC_CAN_V3_2
        HCU_HP6_oB30_for_SC_CAN_V3_2
        HCU_HP8_oB30_for_SC_CAN_V3_2
        HCU_PT4_oB30_for_SC_CAN_V3_2
        HCU_PT5_oB30_for_SC_CAN_V3_2
        HCU_PT7_oB30_for_SC_CAN_V3_2
        HCU_PT8_oB30_for_SC_CAN_V3_2
        HUD1_oB30_for_SC_CAN_V3_2
        Ibooster_FD2_oB30_for_SC_CAN_V3_2
        IFC_FD2_oB30_for_SC_CAN_V3_2
        IFC_FD3_oB30_for_SC_CAN_V3_2
        IFC_FD5_oB30_for_SC_CAN_V3_2
        IFC_FD6_oB30_for_SC_CAN_V3_2
        IFC1_oB30_for_SC_CAN_V3_2
        OBC1_oB30_for_SC_CAN_V3_2
        OBC2_oB30_for_SC_CAN_V3_2
        P2M1_oB30_for_SC_CAN_V3_2
        P2M3_oB30_for_SC_CAN_V3_2
        PDCM1_oB30_for_SC_CAN_V3_2
        PEPS2_oB30_for_SC_CAN_V3_2
        PEPS4_oB30_for_SC_CAN_V3_2
        R_PBOX1_oB30_for_SC_CAN_V3_2
        RFCM_L1_oB30_for_SC_CAN_V3_2
        RFCM_R1_oB30_for_SC_CAN_V3_2
        RSDS_FD1_oB30_for_SC_CAN_V3_2
        RSDS_FD2_oB30_for_SC_CAN_V3_2
        SCM1_oB30_for_SC_CAN_V3_2
        T_BOX_FD1_oB30_for_SC_CAN_V3_2
        T_BOX_FD10_oB30_for_SC_CAN_V3_2
        T_BOX_FD3_oB30_for_SC_CAN_V3_2
        T_BOX_FD4_oB30_for_SC_CAN_V3_2
        T_BOX_FD9_oB30_for_SC_CAN_V3_2
        TOD1_oB30_for_SC_CAN_V3_2
        TPMS1_oB30_for_SC_CAN_V3_2
        TPMS2_oB30_for_SC_CAN_V3_2
        Trailer1_oB30_for_SC_CAN_V3_2
        VMDR1_oB30_for_SC_CAN_V3_2
        WPC1_oB30_for_SC_CAN_V3_2
    HUT_oB30_for_SC_CAN_V3_2_Tx: communication-direction=OUT
      i-signal-i-pdus:
        DMS_FD1_oB30_for_SC_CAN_V3_2
        DVR_FD1_oB30_for_SC_CAN_V3_2
        HUT_FD{1..5}_oB30_for_SC_CAN_V3_2
        HUT_Sync_Req_oB30_for_SC_CAN_V3_2
        HUT1_oB30_for_SC_CAN_V3_2
        HUT10_oB30_for_SC_CAN_V3_2
        HUT12_oB30_for_SC_CAN_V3_2
        HUT13_oB30_for_SC_CAN_V3_2
        HUT{15..17}_oB30_for_SC_CAN_V3_2
        HUT19_oB30_for_SC_CAN_V3_2
        HUT2_oB30_for_SC_CAN_V3_2
        HUT{20..23}_oB30_for_SC_CAN_V3_2
        HUT{25..27}_oB30_for_SC_CAN_V3_2
        HUT3_oB30_for_SC_CAN_V3_2
        HUT{30..39}_oB30_for_SC_CAN_V3_2
        HUT4_oB30_for_SC_CAN_V3_2
        HUT{40..43}_oB30_for_SC_CAN_V3_2
        HUT45_oB30_for_SC_CAN_V3_2
        HUT46_oB30_for_SC_CAN_V3_2
        HUT49_oB30_for_SC_CAN_V3_2
        HUT6_oB30_for_SC_CAN_V3_2
        HUT7_oB30_for_SC_CAN_V3_2
        IP{1..3}_oB30_for_SC_CAN_V3_2
    HUT_oCAN_Rx: communication-direction=IN
      i-signal-i-pdus:
        msg_RxCycle_E2eProf1C_500_10_oCAN
        msg_RxCycle100_0_oCAN
        msg_RxCycle500_20_oCAN
        msg_RxEvent_20_oCAN
        msg_StartAppl_Rx_MyECU_oCAN
    HUT_oCAN_Tx: communication-direction=OUT
      i-signal-i-pdus:
        msg_StartAppl_Tx_MyECU_oCAN
        msg_TxCycle_E2eProf1C_500_30_oCAN
        msg_TxCycle10_0_oCAN
        msg_TxCycle1000_10_oCAN
        msg_TxEvent_10_oCAN
    HUT_oLIN00_Rx: communication-direction=IN, i-signal-i-pdus=[Frame_LinTr_RearECU_oLIN00, Frame_LinTr_Slave3_oLIN00]
    HUT_oLIN00_Tx: communication-direction=OUT, i-signal-i-pdus=[Frame_LinTr_HUT_oLIN00, Frame_LinTr_HUT2_oLIN00]
package /PDU
  pdu ABM1_oB30_for_SC_CAN_V3_2: length=8, minimum-delay=0, transmission-mode-false-timing=cyclic-timing=time-period=0.5, transmission-mode-true-timing=cyclic-timing=time-period=0.5, unused-bit-pattern=0
    signal ABM1_0x351_oABM1_oB30_for_SC_CAN_V3_2: start 0, 64 bit, opaque, i-signal-type=ARRAY, init-value=8 x 0, base-type=uint8_8_none, compu-method=CM_ABM1_0x351, data-constr=DC_ABM1_0x351, transfer-property=PENDING, to HUT
  pdu ACC_FD2_oB30_for_SC_CAN_V3_2: length=56, minimum-delay=0, transmission-mode-false-timing=cyclic-timing=time-period=0.1, transmission-mode-true-timing=cyclic-timing=time-period=0.1, unused-bit-pattern=0
    signal ACC_FD2_0x2AB_oACC_FD2_oB30_for_SC_CAN_V3_2: start 0, 448 bit, opaque, i-signal-type=ARRAY, init-value=56 x 0, base-type=uint8_56_none, compu-method=CM_ACC_FD2_0x2AB, data-constr=DC_ACC_FD2_0x2AB, transfer-property=PENDING, to HUT
  pdu AEB_FD2_oB30_for_SC_CAN_V3_2: length=56, minimum-delay=0, transmission-mode-false-timing=cyclic-timing=time-period=0.05, transmission-mode-true-timing=cyclic-timing=time-period=0.05, unused-bit-pattern=0
    signal AEB_FD2_0x227_oAEB_FD2_oB30_for_SC_CAN_V3_2: start 0, 448 bit, opaque, i-signal-type=ARRAY, init-value=56 x 0, base-type=uint8_56_none, compu-method=CM_AEB_FD2_0x227, data-constr=DC_AEB_FD2_0x227, transfer-property=PENDING, to HUT
  pdu AMP2_oB30_for_SC_CAN_V3_2: length=8, minimum-delay=0, transmission-mode-false-timing=event-controlled-timing={number-of-repetitions=5, repetition-period=0.02}, transmission-mode-true-timing=event-controlled-timing={number-of-repetitions=5, repetition-period=0.02}, unused-bit-pattern=0
    signal AMP2_0x3E3_oAMP2_oB30_for_SC_CAN_V3_2: start 0, 64 bit, opaque, i-signal-type=ARRAY, init-value=8 x 0, base-type=uint8_8_none, compu-method=CM_AMP2_0x3E3, data-constr=DC_AMP2_0x3E3, transfer-property=TRIGGERED, to HUT
  pdu BCM1_oB30_for_SC_CAN_V3_2: length=8, minimum-delay=0, transmission-mode-false-timing=cyclic-timing=time-period=0.05, transmission-mode-true-timing=cyclic-timing=time-period=0.05, unused-bit-pattern=0
    signal BCM1_0x319_oBCM1_oB30_for_SC_CAN_V3_2: start 0, 64 bit, opaque, i-signal-type=ARRAY, init-value=8 x 0, base-type=uint8_8_none, compu-method=CM_BCM1_0x319, data-constr=DC_BCM1_0x319, transfer-property=PENDING, to HUT
  pdu BCM3_oB30_for_SC_CAN_V3_2: length=8, minimum-delay=0, transmission-mode-false-timing=cyclic-timing=time-period=0.05, transmission-mode-true-timing=cyclic-timing=time-period=0.05, unused-bit-pattern=0
    signal BCM3_0x345_oBCM3_oB30_for_SC_CAN_V3_2: start 0, 64 bit, opaque, i-signal-type=ARRAY, init-value=8 x 0, base-type=uint8_8_none, compu-method=CM_BCM3_0x345, data-constr=DC_BCM3_0x345, transfer-property=PENDING, to HUT
  pdu ESP_FD2_oB30_for_SC_CAN_V3_2: length=56, minimum-delay=0, transmission-mode-false-timing=cyclic-timing=time-period=0.02, transmission-mode-true-timing=cyclic-timing=time-period=0.02, unused-bit-pattern=0
    signal ESP_FD2_0x137_oESP_FD2_oB30_for_SC_CAN_V3_2: start 0, 448 bit, opaque, i-signal-type=ARRAY, init-value=56 x 0, base-type=uint8_56_none, compu-method=CM_ESP_FD2_0x137, data-constr=DC_ESP_FD2_0x137, transfer-property=PENDING, to HUT
  pdu GW_Sync_Req_oB30_for_SC_CAN_V3_2: length=0, minimum-delay=0, transmission-mode-false-timing=cyclic-timing=time-period=0, transmission-mode-true-timing=cyclic-timing=time-period=0, unused-bit-pattern=0
    signal null_oGW_Sync_Req_oB30_for_SC_CAN_V3_2: start 0, 0 bit, opaque, i-signal-type=PRIMITIVE, base-type=uint8, to HUT
  pdu HUT_FD1_oB30_for_SC_CAN_V3_2: length=56, minimum-delay=0, transmission-mode-false-timing=cyclic-timing=time-period=0.1, transmission-mode-true-timing=cyclic-timing=time-period=0.1, unused-bit-pattern=0
    signal HUT_FD1_0x2C3_oHUT_FD1_oB30_for_SC_CAN_V3_2: start 0, 448 bit, opaque, i-signal-type=ARRAY, init-value=56 x 0, base-type=uint8_56_none, compu-method=CM_HUT_FD1_0x2C3, data-constr=DC_HUT_FD1_0x2C3, transfer-property=PENDING
  pdu HUT15_oB30_for_SC_CAN_V3_2: length=8, minimum-delay=0, transmission-mode-false-timing=event-controlled-timing={number-of-repetitions=5, repetition-period=0.05}, transmission-mode-true-timing=event-controlled-timing={number-of-repetitions=5, repetition-period=0.05}, unused-bit-pattern=0
    signal HUT15_0x1EE_oHUT15_oB30_for_SC_CAN_V3_2: start 0, 64 bit, opaque, i-signal-type=ARRAY, init-value=8 x 0, base-type=uint8_8_none, compu-method=CM_HUT15_0x1EE, data-constr=DC_HUT15_0x1EE, transfer-property=TRIGGERED
  pdu IFC_FD2_oB30_for_SC_CAN_V3_2: length=56, minimum-delay=0, transmission-mode-false-timing=cyclic-timing=time-period=0.05, transmission-mode-true-timing=cyclic-timing=time-period=0.05, unused-bit-pattern=0
    signal IFC_FD2_0x23D_oIFC_FD2_oB30_for_SC_CAN_V3_2: start 0, 448 bit, opaque, i-signal-type=ARRAY, init-value=56 x 0, base-type=uint8_56_none, compu-method=CM_IFC_FD2_0x23D, data-constr=DC_IFC_FD2_0x23D, transfer-property=PENDING, to HUT
  pdu IP2_oB30_for_SC_CAN_V3_2: length=8, minimum-delay=0, transmission-mode-false-timing=cyclic-timing=time-period=0.05, transmission-mode-true-timing=cyclic-timing=time-period=0.05, unused-bit-pattern=0
    signal IP2_0x27F_oIP2_oB30_for_SC_CAN_V3_2: start 0, 64 bit, opaque, i-signal-type=ARRAY, init-value=8 x 0, base-type=uint8_8_none, compu-method=CM_IP2_0x27F, data-constr=DC_IP2_0x27F, transfer-property=PENDING
  pdu R_PBOX1_oB30_for_SC_CAN_V3_2: length=8, minimum-delay=0, transmission-mode-false-timing=cyclic-timing=time-period=0.05, transmission-mode-true-timing=cyclic-timing=time-period=0.05, unused-bit-pattern=0
    signal R_PBOX1_0x19C_oR_PBOX1_oB30_for_SC_CAN_V3_2: start 0, 64 bit, opaque, i-signal-type=ARRAY, init-value=8 x 0, base-type=uint8_8_none, compu-method=CM_R_PBOX1_0x19C, data-constr=DC_R_PBOX1_0x19C, transfer-property=PENDING, to HUT
  pdu T_BOX_FD1_oB30_for_SC_CAN_V3_2: length=8, minimum-delay=0, transmission-mode-false-timing=event-controlled-timing={number-of-repetitions=5, repetition-period=0.02}, transmission-mode-true-timing=event-controlled-timing={number-of-repetitions=5, repetition-period=0.02}, unused-bit-pattern=0
    signal T_BOX_FD1_0x33_oT_BOX_FD1_oB30_for_SC_CAN_V3_2: start 0, 64 bit, opaque, i-signal-type=ARRAY, init-value=8 x 0, base-type=uint8_8_none, compu-method=CM_T_BOX_FD1_0x33, data-constr=DC_T_BOX_FD1_0x33, transfer-property=TRIGGERED, to HUT
  pdu T_BOX_FD3_oB30_for_SC_CAN_V3_2: length=8, minimum-delay=0, transmission-mode-false-timing=cyclic-timing=time-period=1, transmission-mode-true-timing=cyclic-timing=time-period=1, unused-bit-pattern=0
    signal T_BOX_FD3_0x3E9_oT_BOX_FD3_oB30_for_SC_CAN_V3_2: start 0, 64 bit, opaque, i-signal-type=ARRAY, init-value=8 x 0, base-type=uint8_8_none, compu-method=CM_T_BOX_FD3_0x3E9, data-constr=DC_T_BOX_FD3_0x3E9, transfer-property=PENDING, to HUT
  pdu TPMS1_oB30_for_SC_CAN_V3_2: length=8, minimum-delay=0, transmission-mode-false-timing=cyclic-timing=time-period=0.5, transmission-mode-true-timing=cyclic-timing=time-period=0.5, unused-bit-pattern=0
    signal TPMS1_0x341_oTPMS1_oB30_for_SC_CAN_V3_2: start 0, 64 bit, opaque, i-signal-type=ARRAY, init-value=8 x 0, base-type=uint8_8_none, compu-method=CM_TPMS1_0x341, data-constr=DC_TPMS1_0x341, transfer-property=PENDING, to HUT
  pdu TPMS2_oB30_for_SC_CAN_V3_2: length=8, minimum-delay=0, transmission-mode-false-timing=cyclic-timing=time-period=0.5, transmission-mode-true-timing=cyclic-timing=time-period=0.5, unused-bit-pattern=0
    signal TPMS2_0x395_oTPMS2_oB30_for_SC_CAN_V3_2: start 0, 64 bit, opaque, i-signal-type=ARRAY, init-value=8 x 0, base-type=uint8_8_none, compu-method=CM_TPMS2_0x395, data-constr=DC_TPMS2_0x395, transfer-property=PENDING, to HUT
  dcm i pdu DiagFuncReq_oB30_for_SC_CAN_V3_2: length=7, diag-pdu-type=DIAG-REQUEST
  dcm i pdu DiagFuncReq_oB30_for_SC_CAN_V3_2_20: length=7, diag-pdu-type=DIAG-REQUEST
  dcm i pdu HUT_Phy_Req_oB30_for_SC_CAN_V3_2: length=8, diag-pdu-type=DIAG-REQUEST
  dcm i pdu HUT_Phy_Req_oB30_for_SC_CAN_V3_2_20: length=8, diag-pdu-type=DIAG-REQUEST
  dcm i pdu HUT_Phy_Resp_oB30_for_SC_CAN_V3_2: length=8, diag-pdu-type=DIAG-RESPONSE
  dcm i pdu HUT_Phy_Resp_oB30_for_SC_CAN_V3_2_20: length=8, diag-pdu-type=DIAG-RESPONSE
  dcm i pdu MasterReq_oLIN00: length=8, diag-pdu-type=DIAG-REQUEST
  dcm i pdu MasterReq_RearECU_oLIN00: length=8, diag-pdu-type=DIAG-REQUEST
  dcm i pdu MasterReq_Slave3_oLIN00: length=8, diag-pdu-type=DIAG-REQUEST
  dcm i pdu msg_diag_Request_MyECU_oCAN: length=8, diag-pdu-type=DIAG-REQUEST
  dcm i pdu msg_diag_RequestGlobal_oCAN: length=7, diag-pdu-type=DIAG-REQUEST
  dcm i pdu msg_diag_Response_MyECU_oCAN: length=8, diag-pdu-type=DIAG-RESPONSE
  dcm i pdu SlaveResp_RearECU_oLIN00: length=8, diag-pdu-type=DIAG-RESPONSE
  dcm i pdu SlaveResp_Slave3_oLIN00: length=8, diag-pdu-type=DIAG-RESPONSE
package /ISignal
  i signal group SG_RgRx_Prof1C_RxCycle_omsg_RxCycle_E2eProf1C_500_10_oCAN: i-signal=[SigRx_Prof1C_CRC_omsg_RxCycle_E2eProf1C_500_10_oCAN, SigRx_Prof1C_DataId_HiByte_LoNib_omsg_RxCycle_E2eProf1C_500_10_oCAN, SigRx_Prof1C_Sig32Bit_omsg_RxCycle_E2eProf1C_500_10_oCAN, SigRx_Prof1C_Sig3Bit_omsg_RxCycle_E2eProf1C_500_10_oCAN, SigRx_Prof1C_Sig4Bit_omsg_RxCycle_E2eProf1C_500_10_oCAN, SigRx_Prof1C_SQ_omsg_RxCycle_E2eProf1C_500_10_oCAN], system-signal-group=SG_RgRx_Prof1C_RxCycle
  i signal group SG_SgTx_Prof1C_TxCycle_omsg_TxCycle_E2eProf1C_500_30_oCAN: i-signal=[SigTx_Prof1C_CRC_omsg_TxCycle_E2eProf1C_500_30_oCAN, SigTx_Prof1C_DataId_HiByte_LoNib_omsg_TxCycle_E2eProf1C_500_30_oCAN, SigTx_Prof1C_Sig16Bit_omsg_TxCycle_E2eProf1C_500_30_oCAN, SigTx_Prof1C_Sig2Bit_omsg_TxCycle_E2eProf1C_500_30_oCAN, SigTx_Prof1C_Sig4Bit_omsg_TxCycle_E2eProf1C_500_30_oCAN, SigTx_Prof1C_Sig8Bit_omsg_TxCycle_E2eProf1C_500_30_oCAN, SigTx_Prof1C_SQ_omsg_TxCycle_E2eProf1C_500_30_oCAN], system-signal-group=SG_SgTx_Prof1C_TxCycle
package /SecureCommunicationPropsSet
  secure communication props set SecCommPropsSet
    17 x secure communication authentication props:
      AuthABM1_Sc_oB30_for_SC_CAN_V3_2: auth-info-tx-length=48
      AuthACC_FD2_Sc_oB30_for_SC_CAN_V3_2: auth-info-tx-length=48
      AuthAEB_FD2_Sc_oB30_for_SC_CAN_V3_2: auth-info-tx-length=48
      AuthAMP2_Sc_oB30_for_SC_CAN_V3_2: auth-info-tx-length=48
      AuthBCM1_Sc_oB30_for_SC_CAN_V3_2: auth-info-tx-length=48
      AuthBCM3_Sc_oB30_for_SC_CAN_V3_2: auth-info-tx-length=48
      AuthESP_FD2_Sc_oB30_for_SC_CAN_V3_2: auth-info-tx-length=48
      AuthGW_Sync_Req_Sc_oB30_for_SC_CAN_V3_2: auth-info-tx-length=88
      AuthHUT_FD1_Sc_oB30_for_SC_CAN_V3_2: auth-info-tx-length=48
      AuthHUT15_Sc_oB30_for_SC_CAN_V3_2: auth-info-tx-length=48
      AuthIFC_FD2_Sc_oB30_for_SC_CAN_V3_2: auth-info-tx-length=48
      AuthIP2_Sc_oB30_for_SC_CAN_V3_2: auth-info-tx-length=48
      AuthR_PBOX1_Sc_oB30_for_SC_CAN_V3_2: auth-info-tx-length=48
      AuthT_BOX_FD1_Sc_oB30_for_SC_CAN_V3_2: auth-info-tx-length=48
      AuthT_BOX_FD3_Sc_oB30_for_SC_CAN_V3_2: auth-info-tx-length=48
      AuthTPMS1_Sc_oB30_for_SC_CAN_V3_2: auth-info-tx-length=48
      AuthTPMS2_Sc_oB30_for_SC_CAN_V3_2: auth-info-tx-length=48
    17 x secure communication freshness props:
      FreshnessABM1_Sc_oB30_for_SC_CAN_V3_2: freshness-value-length=64, freshness-value-tx-length=16
      FreshnessACC_FD2_Sc_oB30_for_SC_CAN_V3_2: freshness-value-length=64, freshness-value-tx-length=16
      FreshnessAEB_FD2_Sc_oB30_for_SC_CAN_V3_2: freshness-value-length=64, freshness-value-tx-length=16
      FreshnessAMP2_Sc_oB30_for_SC_CAN_V3_2: freshness-value-length=64, freshness-value-tx-length=16
      FreshnessBCM1_Sc_oB30_for_SC_CAN_V3_2: freshness-value-length=64, freshness-value-tx-length=16
      FreshnessBCM3_Sc_oB30_for_SC_CAN_V3_2: freshness-value-length=64, freshness-value-tx-length=16
      FreshnessESP_FD2_Sc_oB30_for_SC_CAN_V3_2: freshness-value-length=64, freshness-value-tx-length=16
      FreshnessGW_Sync_Req_Sc_oB30_for_SC_CAN_V3_2: freshness-value-length=40, freshness-value-tx-length=40
      FreshnessHUT_FD1_Sc_oB30_for_SC_CAN_V3_2: freshness-value-length=64, freshness-value-tx-length=16
      FreshnessHUT15_Sc_oB30_for_SC_CAN_V3_2: freshness-value-length=64, freshness-value-tx-length=16
      FreshnessIFC_FD2_Sc_oB30_for_SC_CAN_V3_2: freshness-value-length=64, freshness-value-tx-length=16
      FreshnessIP2_Sc_oB30_for_SC_CAN_V3_2: freshness-value-length=64, freshness-value-tx-length=16
      FreshnessR_PBOX1_Sc_oB30_for_SC_CAN_V3_2: freshness-value-length=64, freshness-value-tx-length=16
      FreshnessT_BOX_FD1_Sc_oB30_for_SC_CAN_V3_2: freshness-value-length=64, freshness-value-tx-length=16
      FreshnessT_BOX_FD3_Sc_oB30_for_SC_CAN_V3_2: freshness-value-length=64, freshness-value-tx-length=16
      FreshnessTPMS1_Sc_oB30_for_SC_CAN_V3_2: freshness-value-length=64, freshness-value-tx-length=16
      FreshnessTPMS2_Sc_oB30_for_SC_CAN_V3_2: freshness-value-length=64, freshness-value-tx-length=16
